VERSION "HNNBNNNYNNNNNNNNNNNNNNNNNNNNNNNNNNNNNNNNNN/4/%%%/4/'%**4NNN///"

NS_ :

BS_:

BU_: BAP_Tester FASFrontradar ICAS1_X_Gateway MFK MFK120 MIK MRR2023 NR_1 NR_2

BO_ 588 Heckradar_01: 16 ICAS1_X_Gateway
 SG_ SWA_LED_Hell_BFS : 12|7@1+ (1,0) [0|100] "Unit_PerCent"  Vector__XXX
 SG_ SWA_LED_Hell_FS : 19|7@1+ (1,0) [0|100] "Unit_PerCent"  Vector__XXX
 SG_ SWA_LED_Ausgabemodus_BFS : 26|3@1+ (1.0,0.0) [0.0|7] ""  Vector__XXX
 SG_ SWA_LED_Ausgabemodus_FS : 29|3@1+ (1.0,0.0) [0.0|7] ""  Vector__XXX
 SG_ SWA_Status : 32|2@1+ (1.0,0.0) [0.0|3] ""  MFK
 SG_ ASW_Ton_Richtung_VL : 34|1@1+ (1.0,0.0) [0.0|1] ""  Vector__XXX
 SG_ ASW_Ton_Richtung_VR : 35|1@1+ (1.0,0.0) [0.0|1] ""  Vector__XXX
 SG_ ASW_Ton_Richtung_HL : 36|1@1+ (1.0,0.0) [0.0|1] ""  Vector__XXX
 SG_ ASW_Ton_Richtung_HR : 37|1@1+ (1.0,0.0) [0.0|1] ""  Vector__XXX
 SG_ SWA_Status_System : 38|2@1+ (1.0,0.0) [0.0|3] ""  MFK120
 SG_ SWA_Brightness_Mode_FPM : 40|4@1+ (1.0,0.0) [0.0|15] ""  Vector__XXX
 SG_ SWA_Status_KuFu : 44|2@1+ (1.0,0.0) [0.0|3] ""  MFK120
 SG_ SWA_Infostufe_Assist_li : 46|1@1+ (1.0,0.0) [0.0|1] ""  Vector__XXX
 SG_ SWA_Infostufe_Assist_re : 47|1@1+ (1.0,0.0) [0.0|1] ""  Vector__XXX
 SG_ SWA_Warnstufe_Assist_li : 48|1@1+ (1.0,0.0) [0.0|1] ""  Vector__XXX
 SG_ SWA_Warnstufe_Assist_re : 49|1@1+ (1.0,0.0) [0.0|1] ""  Vector__XXX
 SG_ SWA_Modus_System : 50|3@1+ (1.0,0.0) [0.0|7] ""  MRR2023
 SG_ SWA_Kombiausgabe : 53|3@1+ (1.0,0.0) [0.0|7] ""  Vector__XXX
 SG_ ASW_Kombiausgabe : 56|3@1+ (1.0,0.0) [0.0|7] ""  Vector__XXX
 SG_ ASW_Ausgabemodus_HBFS : 64|3@1+ (1.0,0.0) [0.0|7] ""  Vector__XXX
 SG_ ASW_Ausgabemodus_HFS : 67|3@1+ (1.0,0.0) [0.0|7] ""  Vector__XXX
 SG_ ASW_Akustik_Einstellung : 70|1@1+ (1.0,0.0) [0.0|1] ""  Vector__XXX
 SG_ SWA_Anzeigen : 76|4@1+ (1.0,0.0) [0.0|15] ""  Vector__XXX
 SG_ SWA_Blindheit_erkannt : 80|1@1+ (1.0,0.0) [0.0|1] ""  FASFrontradar,MFK
 SG_ SWA_rel_Nichtverf : 81|1@1+ (1.0,0.0) [0.0|1] ""  FASFrontradar,MFK
 SG_ SWA_rel_Fehler : 82|1@1+ (1.0,0.0) [0.0|1] ""  FASFrontradar,MFK
 SG_ SWA_Sta_aktiv : 83|1@1+ (1.0,0.0) [0.0|1] ""  MFK
 SG_ SWA_Sta_passiv : 84|1@1+ (1.0,0.0) [0.0|1] ""  MFK
 SG_ SWA_FT_RueckLED : 85|1@1+ (1.0,0.0) [0.0|1] ""  Vector__XXX
 SG_ ASW_Status : 86|2@1+ (1.0,0.0) [0.0|3] ""  Vector__XXX
 SG_ SWA_Standziele_li : 88|1@1+ (1.0,0.0) [0.0|1] ""  Vector__XXX
 SG_ ASW_Ausgabemodus_BFS : 89|3@1+ (1.0,0.0) [0.0|7] ""  Vector__XXX
 SG_ ASW_Warnung_FS : 92|1@1+ (1.0,0.0) [0.0|1] ""  Vector__XXX
 SG_ ASW_Warnung_BFS : 93|1@1+ (1.0,0.0) [0.0|1] ""  Vector__XXX
 SG_ ASW_Kombitexte : 94|3@1+ (1.0,0.0) [0.0|7] ""  Vector__XXX
 SG_ ASW_Modus : 98|3@1+ (1.0,0.0) [0.0|7] ""  Vector__XXX
 SG_ SWA_Modus : 101|3@1+ (1.0,0.0) [0.0|7] ""  MFK
 SG_ SWA_Standziele_re : 104|1@1+ (1.0,0.0) [0.0|1] ""  Vector__XXX
 SG_ ASW_Ausgabemodus_FS : 105|3@1+ (1.0,0.0) [0.0|7] ""  Vector__XXX
 SG_ HRE_Anzeigetexte : 108|4@1+ (1.0,0.0) [0.0|15] ""  Vector__XXX
 SG_ SWA_Gischtzaehler : 112|7@1+ (1,0) [0|100] "Unit_PerCent"  MFK
 SG_ SWA_Blindheitsverdacht : 119|1@1+ (1.0,0.0) [0.0|1] ""  FASFrontradar,MFK
 SG_ Heckradar_Kombitexte : 120|5@1+ (1.0,0.0) [0.0|31] ""  Vector__XXX
 SG_ RCTA_Kombitexte : 125|3@1+ (1.0,0.0) [0.0|7] ""  Vector__XXX

BO_ 589 Heckradar_02: 64 ICAS1_X_Gateway
 SG_ SWA_StrukturLinks_querAbstand : 12|9@1+ (0.03125,0) [0.00000|15.93750] "Unit_Meter"  MFK
 SG_ SWA_StrukturLinks_Typ : 21|3@1+ (1.0,0.0) [0.0|7] ""  MFK
 SG_ SWA_Umfeld_Zeitstempel : 24|16@1+ (0.1,0) [0.0|6553.5] "Unit_MilliSecon"  MFK
 SG_ SWA_Umfeld_Zeitstempel_Status : 54|3@1+ (1.0,0.0) [0.0|7] ""  MFK
 SG_ SWA_Kolonne_li : 57|1@1+ (1.0,0.0) [0.0|1] ""  MFK
 SG_ SWA_Kolonne_mi : 58|1@1+ (1.0,0.0) [0.0|1] ""  MFK
 SG_ SWA_Kolonne_re : 59|1@1+ (1.0,0.0) [0.0|1] ""  MFK
 SG_ SWA_Infostufe_SWA_li : 60|1@1+ (1.0,0.0) [0.0|1] ""  FASFrontradar,MFK,MFK120
 SG_ SWA_Infostufe_SWA_re : 61|1@1+ (1.0,0.0) [0.0|1] ""  FASFrontradar,MFK,MFK120
 SG_ SWA_Warnung_SWA_li : 62|1@1+ (1.0,0.0) [0.0|1] ""  FASFrontradar,MFK,MFK120
 SG_ SWA_Warnung_SWA_re : 63|1@1+ (1.0,0.0) [0.0|1] ""  FASFrontradar,MFK,MFK120
 SG_ SWA_Obj_Kurvenradius : 64|16@1+ (1,-32767) [-32767|32767] "Unit_Meter"  MFK
 SG_ SWA_StrukturRechts_querAbstand : 80|9@1+ (0.03125,0) [0.00000|15.93750] "Unit_Meter"  MFK
 SG_ SWA_StrukturRechts_Typ : 89|3@1+ (1.0,0.0) [0.0|7] ""  MFK
 SG_ SWA_Obj_01_Gemessen : 92|1@1+ (1.0,0.0) [0.0|1] ""  FASFrontradar,MFK
 SG_ SWA_Obj_01_ID : 93|5@1+ (1,0) [1|30] ""  FASFrontradar,MFK
 SG_ SWA_Obj_02_Gemessen : 98|1@1+ (1.0,0.0) [0.0|1] ""  FASFrontradar,MFK
 SG_ SWA_Obj_02_ID : 99|5@1+ (1,0) [1|30] ""  FASFrontradar,MFK
 SG_ SWA_Obj_03_Gemessen : 104|1@1+ (1.0,0.0) [0.0|1] ""  FASFrontradar,MFK
 SG_ SWA_Obj_03_ID : 105|5@1+ (1,0) [1|30] ""  FASFrontradar,MFK
 SG_ SWA_Obj_04_Gemessen : 110|1@1+ (1.0,0.0) [0.0|1] ""  FASFrontradar,MFK
 SG_ SWA_Obj_04_ID : 111|5@1+ (1,0) [1|30] ""  FASFrontradar,MFK,MRR2023
 SG_ SWA_Obj_05_Gemessen : 116|1@1+ (1.0,0.0) [0.0|1] ""  FASFrontradar,MFK
 SG_ SWA_Obj_05_ID : 117|5@1+ (1,0) [1|30] ""  FASFrontradar,MFK
 SG_ SWA_Obj_06_Gemessen : 122|1@1+ (1.0,0.0) [0.0|1] ""  FASFrontradar,MFK
 SG_ SWA_Obj_06_ID : 123|5@1+ (1,0) [1|30] ""  FASFrontradar,MFK
 SG_ SWA_Obj_01_GeschwRelX : 128|9@1+ (0.25,-37.5) [-37.50|90.00] "Unit_MeterPerSecon"  FASFrontradar,MFK
 SG_ SWA_Obj_01_Breite : 137|7@1+ (0.03125,0) [0.00000|3.93750] "Unit_Meter"  MFK
 SG_ SWA_Obj_01_GeschwRelY : 144|9@1+ (0.03125,-7.9375) [-7.93750|8.00000] "Unit_MeterPerSecon"  MFK
 SG_ SWA_Obj_01_Existenzwahrsch : 153|7@1+ (1,0) [0|100] "Unit_PerCent"  MFK
 SG_ SWA_Obj_01_Objektklasse : 160|4@1+ (1.0,0.0) [0.0|15] ""  MFK
 SG_ SWA_Obj_01_ReferenzPkt : 164|4@1+ (1.0,0.0) [0.0|15] ""  MFK
 SG_ SWA_Obj_01_PositionX : 168|9@1+ (0.25,-102.5) [-102.50|25.00] "Unit_Meter"  FASFrontradar,MFK
 SG_ SWA_Obj_01_Laenge : 177|7@1+ (0.25,0) [0.00|31.50] "Unit_Meter"  MFK
 SG_ SWA_Obj_01_PositionY : 184|8@1+ (0.125,-16) [-16.000|15.750] "Unit_Meter"  FASFrontradar,MFK
 SG_ SWA_Obj_02_GeschwRelX : 192|9@1+ (0.25,-37.5) [-37.50|90.00] "Unit_MeterPerSecon"  FASFrontradar,MFK
 SG_ SWA_Obj_02_Breite : 201|7@1+ (0.03125,0) [0.00000|3.93750] "Unit_Meter"  MFK
 SG_ SWA_Obj_02_GeschwRelY : 208|9@1+ (0.03125,-7.9375) [-7.93750|8.00000] "Unit_MeterPerSecon"  MFK
 SG_ SWA_Obj_02_Existenzwahrsch : 217|7@1+ (1,0) [0|100] "Unit_PerCent"  MFK
 SG_ SWA_Obj_02_Objektklasse : 224|4@1+ (1.0,0.0) [0.0|15] ""  MFK
 SG_ SWA_Obj_02_ReferenzPkt : 228|4@1+ (1.0,0.0) [0.0|15] ""  MFK
 SG_ SWA_Obj_02_PositionX : 232|9@1+ (0.25,-102.5) [-102.50|25.00] "Unit_Meter"  FASFrontradar,MFK
 SG_ SWA_Obj_02_Laenge : 241|7@1+ (0.25,0) [0.00|31.50] "Unit_Meter"  MFK
 SG_ SWA_Obj_02_PositionY : 248|8@1+ (0.125,-16) [-16.000|15.750] "Unit_Meter"  FASFrontradar,MFK
 SG_ SWA_Obj_03_GeschwRelX : 256|9@1+ (0.25,-37.5) [-37.50|90.00] "Unit_MeterPerSecon"  FASFrontradar,MFK
 SG_ SWA_Obj_03_Breite : 265|7@1+ (0.03125,0) [0.00000|3.93750] "Unit_Meter"  MFK
 SG_ SWA_Obj_03_GeschwRelY : 272|9@1+ (0.03125,-7.9375) [-7.93750|8.00000] "Unit_MeterPerSecon"  MFK
 SG_ SWA_Obj_03_Existenzwahrsch : 281|7@1+ (1,0) [0|100] "Unit_PerCent"  MFK
 SG_ SWA_Obj_03_Objektklasse : 288|4@1+ (1.0,0.0) [0.0|15] ""  MFK
 SG_ SWA_Obj_03_ReferenzPkt : 292|4@1+ (1.0,0.0) [0.0|15] ""  MFK
 SG_ SWA_Obj_03_PositionX : 296|9@1+ (0.25,-102.5) [-102.50|25.00] "Unit_Meter"  FASFrontradar,MFK
 SG_ SWA_Obj_03_Laenge : 305|7@1+ (0.25,0) [0.00|31.50] "Unit_Meter"  MFK
 SG_ SWA_Obj_03_PositionY : 312|8@1+ (0.125,-16) [-16.000|15.750] "Unit_Meter"  FASFrontradar,MFK
 SG_ SWA_Obj_04_GeschwRelX : 320|9@1+ (0.25,-37.5) [-37.50|90.00] "Unit_MeterPerSecon"  FASFrontradar,MFK
 SG_ SWA_Obj_04_Breite : 329|7@1+ (0.03125,0) [0.00000|3.93750] "Unit_Meter"  MFK
 SG_ SWA_Obj_04_GeschwRelY : 336|9@1+ (0.03125,-7.9375) [-7.93750|8.00000] "Unit_MeterPerSecon"  MFK
 SG_ SWA_Obj_04_Existenzwahrsch : 345|7@1+ (1,0) [0|100] "Unit_PerCent"  MFK
 SG_ SWA_Obj_04_Objektklasse : 352|4@1+ (1.0,0.0) [0.0|15] ""  MFK
 SG_ SWA_Obj_04_ReferenzPkt : 356|4@1+ (1.0,0.0) [0.0|15] ""  MFK
 SG_ SWA_Obj_04_PositionX : 360|9@1+ (0.25,-102.5) [-102.50|25.00] "Unit_Meter"  FASFrontradar,MFK
 SG_ SWA_Obj_04_Laenge : 369|7@1+ (0.25,0) [0.00|31.50] "Unit_Meter"  MFK
 SG_ SWA_Obj_04_PositionY : 376|8@1+ (0.125,-16) [-16.000|15.750] "Unit_Meter"  FASFrontradar,MFK
 SG_ SWA_Obj_05_GeschwRelX : 384|9@1+ (0.25,-37.5) [-37.50|90.00] "Unit_MeterPerSecon"  FASFrontradar,MFK
 SG_ SWA_Obj_05_Breite : 393|7@1+ (0.03125,0) [0.00000|3.93750] "Unit_Meter"  MFK
 SG_ SWA_Obj_05_GeschwRelY : 400|9@1+ (0.03125,-7.9375) [-7.93750|8.00000] "Unit_MeterPerSecon"  MFK
 SG_ SWA_Obj_05_Existenzwahrsch : 409|7@1+ (1,0) [0|100] "Unit_PerCent"  MFK
 SG_ SWA_Obj_05_Objektklasse : 416|4@1+ (1.0,0.0) [0.0|15] ""  MFK
 SG_ SWA_Obj_05_ReferenzPkt : 420|4@1+ (1.0,0.0) [0.0|15] ""  MFK
 SG_ SWA_Obj_05_PositionX : 424|9@1+ (0.25,-102.5) [-102.50|25.00] "Unit_Meter"  FASFrontradar,MFK
 SG_ SWA_Obj_05_Laenge : 433|7@1+ (0.25,0) [0.00|31.50] "Unit_Meter"  MFK
 SG_ SWA_Obj_05_PositionY : 440|8@1+ (0.125,-16) [-16.000|15.750] "Unit_Meter"  FASFrontradar,MFK
 SG_ SWA_Obj_06_GeschwRelX : 448|9@1+ (0.25,-37.5) [-37.50|90.00] "Unit_MeterPerSecon"  FASFrontradar,MFK
 SG_ SWA_Obj_06_Breite : 457|7@1+ (0.03125,0) [0.00000|3.93750] "Unit_Meter"  MFK
 SG_ SWA_Obj_06_GeschwRelY : 464|9@1+ (0.03125,-7.9375) [-7.93750|8.00000] "Unit_MeterPerSecon"  MFK
 SG_ SWA_Obj_06_Existenzwahrsch : 473|7@1+ (1,0) [0|100] "Unit_PerCent"  MFK
 SG_ SWA_Obj_06_Objektklasse : 480|4@1+ (1.0,0.0) [0.0|15] ""  MFK
 SG_ SWA_Obj_06_ReferenzPkt : 484|4@1+ (1.0,0.0) [0.0|15] ""  MFK
 SG_ SWA_Obj_06_PositionX : 488|9@1+ (0.25,-102.5) [-102.50|25.00] "Unit_Meter"  FASFrontradar,MFK
 SG_ SWA_Obj_06_Laenge : 497|7@1+ (0.25,0) [0.00|31.50] "Unit_Meter"  MFK
 SG_ SWA_Obj_06_PositionY : 504|8@1+ (0.125,-16) [-16.000|15.750] "Unit_Meter"  FASFrontradar,MFK

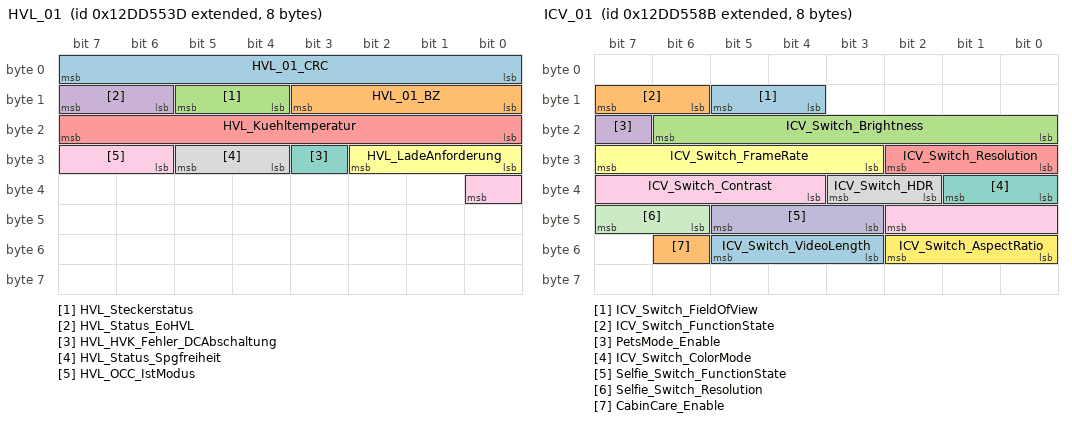
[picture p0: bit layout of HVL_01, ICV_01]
BO_ 2463978813 HVL_01: 8 ICAS1_X_Gateway
 SG_ HVL_01_CRC : 0|8@1+ (1,0) [0|255] ""  Vector__XXX
 SG_ HVL_01_BZ : 8|4@1+ (1,0) [0|15] ""  Vector__XXX
 SG_ HVL_Steckerstatus : 12|2@1+ (1.0,0.0) [0.0|3] ""  MFK,MFK120
 SG_ HVL_Status_EoHVL : 14|2@1+ (1.0,0.0) [0.0|3] ""  Vector__XXX
 SG_ HVL_Kuehltemperatur : 16|8@1+ (1,-40) [-40|213] "Unit_DegreCelsi"  Vector__XXX
 SG_ HVL_LadeAnforderung : 24|3@1+ (1.0,0.0) [0.0|7] ""  Vector__XXX
 SG_ HVL_HVK_Fehler_DCAbschaltung : 27|1@1+ (1.0,0.0) [0.0|1] ""  Vector__XXX
 SG_ HVL_Status_Spgfreiheit : 28|2@1+ (1.0,0.0) [0.0|3] ""  Vector__XXX
 SG_ HVL_OCC_IstModus : 30|3@1+ (1.0,0.0) [0.0|7] ""  Vector__XXX

BO_ 2463978891 ICV_01: 8 ICAS1_X_Gateway
 SG_ ICV_Switch_FieldOfView : 12|2@1+ (1.0,0.0) [0.0|3] ""  MIK
 SG_ ICV_Switch_FunctionState : 14|2@1+ (1.0,0.0) [0.0|3] ""  MIK
 SG_ ICV_Switch_Brightness : 16|7@1+ (1,0) [0|100] "Unit_PerCent"  MIK
 SG_ PetsMode_Enable : 23|1@1+ (1.0,0.0) [0.0|1] ""  MIK
 SG_ ICV_Switch_Resolution : 24|3@1+ (1.0,0.0) [0.0|7] ""  MIK
 SG_ ICV_Switch_FrameRate : 27|5@1+ (1,0) [15|30] "Unit_SeconInver"  MIK
 SG_ ICV_Switch_ColorMode : 32|2@1+ (1.0,0.0) [0.0|3] ""  MIK
 SG_ ICV_Switch_HDR : 34|2@1+ (1.0,0.0) [0.0|3] ""  MIK
 SG_ ICV_Switch_Contrast : 36|7@1+ (1,0) [0|100] "Unit_PerCent"  MIK
 SG_ Selfie_Switch_FunctionState : 43|3@1+ (1.0,0.0) [0.0|7] ""  MIK
 SG_ Selfie_Switch_Resolution : 46|2@1+ (1.0,0.0) [0.0|3] ""  MIK
 SG_ ICV_Switch_AspectRatio : 48|3@1+ (1.0,0.0) [0.0|7] ""  MIK
 SG_ ICV_Switch_VideoLength : 51|3@1+ (1.0,0.0) [0.0|7] ""  MIK
 SG_ CabinCare_Enable : 54|1@1+ (1.0,0.0) [0.0|1] ""  MIK

BO_ 1524 Innenlicht_11: 8 ICAS1_X_Gateway
 SG_ IL_Dimmung_V_Tuerkontur : 0|8@1+ (1,0) [0|100] "Unit_PerCent"  Vector__XXX
 SG_ IL_Dimmung_H_Tuerkontur : 8|8@1+ (1,0) [0|100] "Unit_PerCent"  Vector__XXX
 SG_ IL_Dimmung_Tuerinnengriff : 16|8@1+ (1,0) [0|100] "Unit_PerCent"  Vector__XXX
 SG_ IL_Dimmung_Umfeldbel : 24|8@1+ (1,0) [0|100] "Unit_PerCent"  Vector__XXX
 SG_ IL_Bel_FS_Ausstieg : 32|1@1+ (1.0,0.0) [0.0|1] ""  Vector__XXX
 SG_ IL_Bel_BFS_Ausstieg : 33|1@1+ (1.0,0.0) [0.0|1] ""  Vector__XXX
 SG_ IL_Bel_HFS_Ausstieg : 34|1@1+ (1.0,0.0) [0.0|1] ""  Vector__XXX
 SG_ IL_Bel_HBFS_Ausstieg : 35|1@1+ (1.0,0.0) [0.0|1] ""  Vector__XXX
 SG_ BCM1_Innenlicht_gedimmt_V : 36|1@1+ (1.0,0.0) [0.0|1] ""  Vector__XXX
 SG_ BCM1_Innenlicht_gedimmt_H : 37|1@1+ (1.0,0.0) [0.0|1] ""  Vector__XXX
 SG_ IL_Innenlicht_aktiv : 38|1@1+ (1.0,0.0) [0.0|1] ""  MFK,MIK
 SG_ IL_Klemme_30G_aktiv : 39|1@1+ (1.0,0.0) [0.0|1] ""  Vector__XXX
 SG_ BCM1_DI_Rampe_Innenlicht : 40|1@1+ (1.0,0.0) [0.0|1] ""  Vector__XXX
 SG_ BCM1_DI_Rampe_Leselicht : 41|1@1+ (1.0,0.0) [0.0|1] ""  Vector__XXX
 SG_ BCM1_Innenlicht_H : 42|1@1+ (1.0,0.0) [0.0|1] ""  Vector__XXX
 SG_ BCM1_Innenlicht_V : 43|1@1+ (1.0,0.0) [0.0|1] ""  Vector__XXX
 SG_ BCM1_Leselicht_Anf_hl : 44|1@1+ (1.0,0.0) [0.0|1] ""  Vector__XXX
 SG_ BCM1_Leselicht_Anf_hr : 45|1@1+ (1.0,0.0) [0.0|1] ""  Vector__XXX
 SG_ BCM1_Leselicht_Anf_vl : 46|1@1+ (1.0,0.0) [0.0|1] ""  Vector__XXX
 SG_ BCM1_Leselicht_Anf_vr : 47|1@1+ (1.0,0.0) [0.0|1] ""  Vector__XXX
 SG_ BCM1_Leuchten_Aus : 48|1@1+ (1.0,0.0) [0.0|1] ""  Vector__XXX
 SG_ AMB_Charisma_FahrPr : 49|4@1+ (1.0,0.0) [0.0|15] ""  Vector__XXX
 SG_ AMB_Charisma_Status : 53|2@1+ (1.0,0.0) [0.0|3] ""  Vector__XXX
 SG_ IL_Tuerkontakt_Taster : 55|1@1+ (1.0,0.0) [0.0|1] ""  Vector__XXX
 SG_ IL_Dimmung_Lautspr : 56|8@1+ (1,0) [0|100] "Unit_PerCent"  Vector__XXX

BO_ 1879 ISO_ACC_Req: 8 ICAS1_X_Gateway
 SG_ ISO_ACC_Req_Data : 0|64@1+ (1.0,0.0) [0.0|18446744073709551615] ""  FASFrontradar,MRR2023

BO_ 1985 ISO_ACC_Resp: 8 FASFrontradar
 SG_ ISO_ACC_Resp_Data : 0|64@1+ (1.0,0.0) [0.0|18446744073709551615] ""  ICAS1_X_Gateway

BO_ 1792 ISO_Funktionaler_Req_All: 8 ICAS1_X_Gateway
 SG_ ISO_ALL_01_Req_Data : 0|64@1+ (1.0,0.0) [0.0|18446744073709551615] ""  FASFrontradar,MFK,MRR2023,NR_1,NR_2

BO_ 1871 ISO_Kamera_Req: 8 ICAS1_X_Gateway
 SG_ ISO_Kamera_Req_Data : 0|64@1+ (1.0,0.0) [0.0|18446744073709551615] ""  MFK

BO_ 1977 ISO_Kamera_Resp: 8 MFK
 SG_ ISO_Kamera_Resp_Data : 0|64@1+ (1.0,0.0) [0.0|18446744073709551615] ""  ICAS1_X_Gateway

BO_ 2621440087 ISOx_ACC_Req_FD: 64 ICAS1_X_Gateway
 SG_ ISOx_ACC_Req_FD_Data : 0|512@1+ (1.0,0.0) [0.0|13407807929942597099574024998205846127479365820592393377723561443721764030073546976801874298166903427690031858186486050853753882811946569946433649006084095] ""  FASFrontradar,MRR2023

BO_ 2621571159 ISOx_ACC_Resp_FD: 64 FASFrontradar
 SG_ ISOx_ACC_Resp_FD_Data : 0|512@1+ (1.0,0.0) [0.0|13407807929942597099574024998205846127479365820592393377723561443721764030073546976801874298166903427690031858186486050853753882811946569946433649006084095] ""  ICAS1_X_Gateway

BO_ 2621505536 ISOx_Funkt_Req_All_FD: 64 ICAS1_X_Gateway
 SG_ ISOx_Funkt_Req_All_FD_Data : 0|512@1+ (1.0,0.0) [0.0|13407807929942597099574024998205846127479365820592393377723561443721764030073546976801874298166903427690031858186486050853753882811946569946433649006084095] ""  FASFrontradar,MFK,MRR2023,NR_1,NR_2

BO_ 2621440079 ISOx_Kamera_Req_FD: 64 ICAS1_X_Gateway
 SG_ ISOx_Kamera_Req_FD_Data : 0|512@1+ (1.0,0.0) [0.0|13407807929942597099574024998205846127479365820592393377723561443721764030073546976801874298166903427690031858186486050853753882811946569946433649006084095] ""  MFK

BO_ 2621571151 ISOx_Kamera_Resp_FD: 64 MFK
 SG_ ISOx_Kamera_Resp_FD_Data : 0|512@1+ (1.0,0.0) [0.0|13407807929942597099574024998205846127479365820592393377723561443721764030073546976801874298166903427690031858186486050853753882811946569946433649006084095] ""  ICAS1_X_Gateway

BO_ 2549874875 ISOx_NR_01_Req: 8 ICAS1_X_Gateway
 SG_ ISOx_NR_01_Req_Data : 0|64@1+ (1.0,0.0) [0.0|18446744073709551615] ""  NR_1

BO_ 2621440187 ISOx_NR_01_Req_FD: 64 ICAS1_X_Gateway
 SG_ ISOx_NR_01_Req_FD_Data : 0|512@1+ (1.0,0.0) [0.0|13407807929942597099574024998205846127479365820592393377723561443721764030073546976801874298166903427690031858186486050853753882811946569946433649006084095] ""  NR_1

BO_ 2550005947 ISOx_NR_01_Resp: 8 NR_1
 SG_ ISOx_NR_01_Resp_Data : 0|64@1+ (1.0,0.0) [0.0|18446744073709551615] ""  ICAS1_X_Gateway

BO_ 2621571259 ISOx_NR_01_Resp_FD: 64 NR_1
 SG_ ISOx_NR_01_Resp_FD_Data : 0|512@1+ (1.0,0.0) [0.0|13407807929942597099574024998205846127479365820592393377723561443721764030073546976801874298166903427690031858186486050853753882811946569946433649006084095] ""  ICAS1_X_Gateway

BO_ 2549874876 ISOx_NR_02_Req: 8 ICAS1_X_Gateway
 SG_ ISOx_NR_02_Req_Data : 0|64@1+ (1.0,0.0) [0.0|18446744073709551615] ""  NR_2

BO_ 2621440188 ISOx_NR_02_Req_FD: 64 ICAS1_X_Gateway
 SG_ ISOx_NR_02_Req_FD_Data : 0|512@1+ (1.0,0.0) [0.0|13407807929942597099574024998205846127479365820592393377723561443721764030073546976801874298166903427690031858186486050853753882811946569946433649006084095] ""  NR_2

BO_ 2550005948 ISOx_NR_02_Resp: 8 NR_2
 SG_ ISOx_NR_02_Resp_Data : 0|64@1+ (1.0,0.0) [0.0|18446744073709551615] ""  ICAS1_X_Gateway

BO_ 2621571260 ISOx_NR_02_Resp_FD: 64 NR_2
 SG_ ISOx_NR_02_Resp_FD_Data : 0|512@1+ (1.0,0.0) [0.0|13407807929942597099574024998205846127479365820592393377723561443721764030073546976801874298166903427690031858186486050853753882811946569946433649006084095] ""  ICAS1_X_Gateway

BO_ 2527679667 Kamera_AHC_01: 16 MFK
 SG_ Kamera_AHC_L_Funktionsstatus : 12|4@1+ (1.0,0.0) [0.0|15] ""  Vector__XXX
 SG_ Kamera_AHC_L_Gierwinkel : 16|13@1+ (0.01,-40.95) [-40.95|40.95] "Unit_DegreOfArc"  Vector__XXX
 SG_ Kamera_AHC_L_Nickwinkel : 29|13@1+ (0.01,-40.95) [-40.95|40.95] "Unit_DegreOfArc"  Vector__XXX
 SG_ Kamera_AHC_L_ROI_ID : 42|4@1+ (1,0) [0|14] "Unit_None"  Vector__XXX
 SG_ Kamera_AHC_L_Qualitaet : 46|5@1+ (4,0) [0|100] "Unit_PerCent"  Vector__XXX
 SG_ Kamera_AHC_R_Funktionsstatus : 76|4@1+ (1.0,0.0) [0.0|15] ""  Vector__XXX
 SG_ Kamera_AHC_R_Gierwinkel : 80|13@1+ (0.01,-40.95) [-40.95|40.95] "Unit_DegreOfArc"  Vector__XXX
 SG_ Kamera_AHC_R_Nickwinkel : 93|13@1+ (0.01,-40.95) [-40.95|40.95] "Unit_DegreOfArc"  Vector__XXX
 SG_ Kamera_AHC_R_ROI_ID : 106|4@1+ (1,0) [0|14] "Unit_None"  Vector__XXX
 SG_ Kamera_AHC_R_Qualitaet : 110|5@1+ (4,0) [0|100] "Unit_PerCent"  Vector__XXX

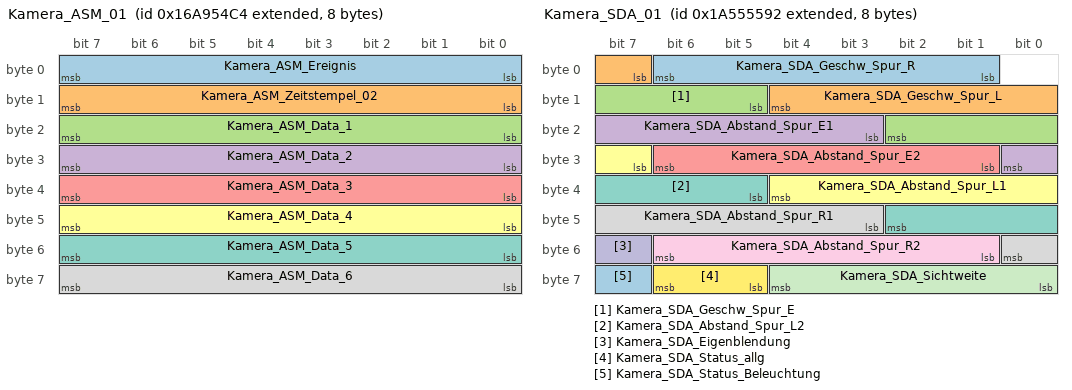
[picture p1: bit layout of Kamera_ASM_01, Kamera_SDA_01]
BO_ 2527679684 Kamera_ASM_01: 8 MFK
 SG_ Kamera_ASM_Ereignis : 0|8@1+ (1,0) [1|254] ""  ICAS1_X_Gateway
 SG_ Kamera_ASM_Zeitstempel_02 : 8|8@1+ (0.04,0) [0.00|10.16] "Unit_Secon"  ICAS1_X_Gateway
 SG_ Kamera_ASM_Data_1 : 16|8@1+ (1,0) [0|255] ""  ICAS1_X_Gateway
 SG_ Kamera_ASM_Data_2 : 24|8@1+ (1,0) [0|255] ""  ICAS1_X_Gateway
 SG_ Kamera_ASM_Data_3 : 32|8@1+ (1,0) [0|255] ""  ICAS1_X_Gateway
 SG_ Kamera_ASM_Data_4 : 40|8@1+ (1,0) [0|255] ""  ICAS1_X_Gateway
 SG_ Kamera_ASM_Data_5 : 48|8@1+ (1,0) [0|255] ""  ICAS1_X_Gateway
 SG_ Kamera_ASM_Data_6 : 56|8@1+ (1,0) [0|255] ""  ICAS1_X_Gateway

BO_ 2589283730 Kamera_SDA_01: 8 MFK
 SG_ Kamera_SDA_Geschw_Spur_R : 1|6@1+ (7.7581,-240) [-240.0000|241.0022] "Unit_KiloMeterPerHour"  ICAS1_X_Gateway
 SG_ Kamera_SDA_Geschw_Spur_L : 7|6@1+ (7.7581,-240) [-240.0000|241.0022] "Unit_KiloMeterPerHour"  ICAS1_X_Gateway
 SG_ Kamera_SDA_Geschw_Spur_E : 13|6@1+ (7.7581,-240) [-240.0000|241.0022] "Unit_KiloMeterPerHour"  ICAS1_X_Gateway
 SG_ Kamera_SDA_Abstand_Spur_E1 : 19|6@1+ (4.0323,0) [0.0000|250.0026] "Unit_Meter"  ICAS1_X_Gateway
 SG_ Kamera_SDA_Abstand_Spur_E2 : 25|6@1+ (4.0323,0) [0.0000|250.0026] "Unit_Meter"  ICAS1_X_Gateway
 SG_ Kamera_SDA_Abstand_Spur_L1 : 31|6@1+ (4.0323,0) [0.0000|250.0026] "Unit_Meter"  ICAS1_X_Gateway
 SG_ Kamera_SDA_Abstand_Spur_L2 : 37|6@1+ (4.0323,0) [0.0000|250.0026] "Unit_Meter"  ICAS1_X_Gateway
 SG_ Kamera_SDA_Abstand_Spur_R1 : 43|6@1+ (4.0323,0) [0.0000|250.0026] "Unit_Meter"  ICAS1_X_Gateway
 SG_ Kamera_SDA_Abstand_Spur_R2 : 49|6@1+ (4.0323,0) [0.0000|250.0026] "Unit_Meter"  ICAS1_X_Gateway
 SG_ Kamera_SDA_Eigenblendung : 55|1@1+ (1.0,0.0) [0.0|1] ""  ICAS1_X_Gateway
 SG_ Kamera_SDA_Sichtweite : 56|5@1+ (10,-10) [10|250] "Unit_Meter"  ICAS1_X_Gateway
 SG_ Kamera_SDA_Status_allg : 61|2@1+ (1.0,0.0) [0.0|3] ""  ICAS1_X_Gateway
 SG_ Kamera_SDA_Status_Beleuchtung : 63|1@1+ (1.0,0.0) [0.0|1] ""  ICAS1_X_Gateway

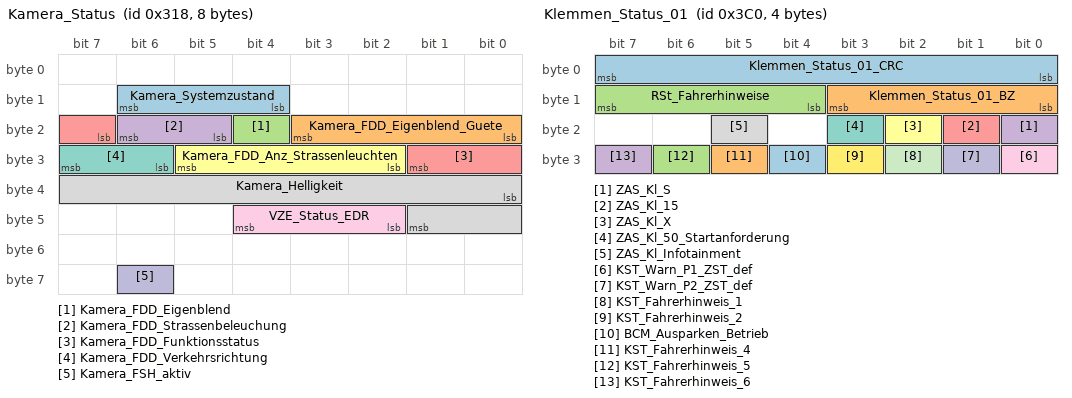
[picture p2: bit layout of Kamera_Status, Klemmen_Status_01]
BO_ 792 Kamera_Status: 8 MFK
 SG_ Kamera_Systemzustand : 12|3@1+ (1.0,0.0) [0.0|7] ""  FASFrontradar,ICAS1_X_Gateway,MRR2023
 SG_ Kamera_FDD_Eigenblend_Guete : 16|4@1+ (10,0) [0|100] "Unit_PerCent"  ICAS1_X_Gateway
 SG_ Kamera_FDD_Eigenblend : 20|1@1+ (1.0,0.0) [0.0|1] ""  ICAS1_X_Gateway
 SG_ Kamera_FDD_Strassenbeleuchung : 21|2@1+ (1.0,0.0) [0.0|3] ""  ICAS1_X_Gateway
 SG_ Kamera_FDD_Funktionsstatus : 23|3@1+ (1.0,0.0) [0.0|7] ""  ICAS1_X_Gateway
 SG_ Kamera_FDD_Anz_Strassenleuchten : 26|4@1+ (1,0) [0|14] ""  ICAS1_X_Gateway
 SG_ Kamera_FDD_Verkehrsrichtung : 30|2@1+ (1.0,0.0) [0.0|3] ""  ICAS1_X_Gateway
 SG_ Kamera_Helligkeit : 32|10@1+ (10,0) [0|10000] "Unit_Lux"  ICAS1_X_Gateway
 SG_ VZE_Status_EDR : 42|3@1+ (1.0,0.0) [0.0|7] ""  ICAS1_X_Gateway
 SG_ Kamera_FSH_aktiv : 62|1@1+ (1.0,0.0) [0.0|1] ""  ICAS1_X_Gateway

BO_ 960 Klemmen_Status_01: 4 ICAS1_X_Gateway
 SG_ Klemmen_Status_01_CRC : 0|8@1+ (1,0) [0|255] ""  FASFrontradar,MFK,MFK120,MRR2023
 SG_ Klemmen_Status_01_BZ : 8|4@1+ (1,0) [0|15] ""  FASFrontradar,MFK,MFK120,MRR2023
 SG_ RSt_Fahrerhinweise : 12|4@1+ (1.0,0.0) [0.0|15] ""  Vector__XXX
 SG_ ZAS_Kl_S : 16|1@1+ (1.0,0.0) [0.0|1] ""  MFK,MFK120
 SG_ ZAS_Kl_15 : 17|1@1+ (1.0,0.0) [0.0|1] ""  FASFrontradar,MFK,MFK120,MIK,MRR2023
 SG_ ZAS_Kl_X : 18|1@1+ (1.0,0.0) [0.0|1] ""  Vector__XXX
 SG_ ZAS_Kl_50_Startanforderung : 19|1@1+ (1.0,0.0) [0.0|1] ""  MFK,MFK120
 SG_ ZAS_Kl_Infotainment : 21|1@1+ (1.0,0.0) [0.0|1] ""  Vector__XXX
 SG_ KST_Warn_P1_ZST_def : 24|1@1+ (1.0,0.0) [0.0|1] ""  Vector__XXX
 SG_ KST_Warn_P2_ZST_def : 25|1@1+ (1.0,0.0) [0.0|1] ""  Vector__XXX
 SG_ KST_Fahrerhinweis_1 : 26|1@1+ (1.0,0.0) [0.0|1] ""  Vector__XXX
 SG_ KST_Fahrerhinweis_2 : 27|1@1+ (1.0,0.0) [0.0|1] ""  Vector__XXX
 SG_ BCM_Ausparken_Betrieb : 28|1@1+ (1.0,0.0) [0.0|1] ""  Vector__XXX
 SG_ KST_Fahrerhinweis_4 : 29|1@1+ (1.0,0.0) [0.0|1] ""  Vector__XXX
 SG_ KST_Fahrerhinweis_5 : 30|1@1+ (1.0,0.0) [0.0|1] ""  Vector__XXX
 SG_ KST_Fahrerhinweis_6 : 31|1@1+ (1.0,0.0) [0.0|1] ""  Vector__XXX

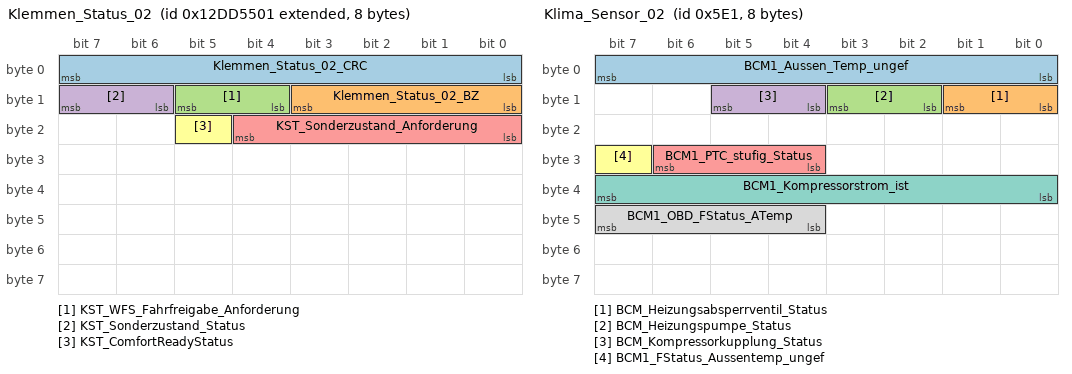
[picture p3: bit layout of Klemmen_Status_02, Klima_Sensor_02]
BO_ 2463978753 Klemmen_Status_02: 8 ICAS1_X_Gateway
 SG_ Klemmen_Status_02_CRC : 0|8@1+ (1,0) [0|255] ""  Vector__XXX
 SG_ Klemmen_Status_02_BZ : 8|4@1+ (1,0) [0|15] ""  Vector__XXX
 SG_ KST_WFS_Fahrfreigabe_Anforderung : 12|2@1+ (1.0,0.0) [0.0|3] ""  Vector__XXX
 SG_ KST_Sonderzustand_Status : 14|2@1+ (1.0,0.0) [0.0|3] ""  Vector__XXX
 SG_ KST_Sonderzustand_Anforderung : 16|5@1+ (1.0,0.0) [0.0|31] ""  Vector__XXX
 SG_ KST_ComfortReadyStatus : 21|1@1+ (1.0,0.0) [0.0|1] ""  Vector__XXX

BO_ 1640 Klima_12: 8 ICAS1_X_Gateway
 SG_ KL_LRH_Taster : 0|1@1+ (1.0,0.0) [0.0|1] ""  Vector__XXX
 SG_ KL_LRH_Stufe : 1|2@1+ (1.0,0.0) [0.0|3] ""  Vector__XXX
 SG_ HSH_Taster : 3|2@1+ (1.0,0.0) [0.0|3] ""  Vector__XXX
 SG_ FSH_Taster : 5|1@1+ (1.0,0.0) [0.0|1] ""  Vector__XXX
 SG_ KL_Zuheizer_Freigabe : 6|1@1+ (1.0,0.0) [0.0|1] ""  Vector__XXX
 SG_ KL_Beschlagsgefahr : 7|1@1+ (1.0,0.0) [0.0|1] ""  MFK,MFK120
 SG_ KL_SIH_Soll_li : 8|3@1+ (1,0) [0|6] ""  Vector__XXX
 SG_ KL_SIH_Soll_re : 11|3@1+ (1,0) [0|6] ""  Vector__XXX
 SG_ KRH_Soll_li : 14|2@1+ (1.0,0.0) [0.0|3] ""  Vector__XXX
 SG_ KL_SIL_Soll_li : 16|3@1+ (1,0) [0|6] ""  Vector__XXX
 SG_ KL_SIL_Soll_re : 19|3@1+ (1,0) [0|6] ""  Vector__XXX
 SG_ KRH_Soll_re : 22|2@1+ (1.0,0.0) [0.0|3] ""  Vector__XXX
 SG_ KL_Geblspng_Soll : 24|8@1+ (0.05,1.45) [1.50|14.00] "Unit_Volt"  Vector__XXX
 SG_ KL_Geblspng_Fond_Soll : 32|8@1+ (0.05,1.45) [1.50|14.00] "Unit_Volt"  Vector__XXX
 SG_ KL_I_Geblaese : 40|8@1+ (0.25,0) [0.00|63.50] "Unit_Amper"  Vector__XXX
 SG_ KL_Kompressorstrom_soll : 48|10@1+ (1,0) [0|1021] ""  Vector__XXX
 SG_ KL_Umluftklappe_Status : 58|4@1+ (1.0,0.0) [0.0|15] ""  Vector__XXX
 SG_ KL_PTC_Verbauinfo : 62|2@1+ (1.0,0.0) [0.0|3] ""  Vector__XXX

BO_ 1505 Klima_Sensor_02: 8 ICAS1_X_Gateway
 SG_ BCM1_Aussen_Temp_ungef : 0|8@1+ (0.5,-50) [-50.0|76.0] "Unit_DegreCelsi"  Vector__XXX
 SG_ BCM_Heizungsabsperrventil_Status : 8|2@1+ (1.0,0.0) [0.0|3] ""  Vector__XXX
 SG_ BCM_Heizungspumpe_Status : 10|2@1+ (1.0,0.0) [0.0|3] ""  Vector__XXX
 SG_ BCM_Kompressorkupplung_Status : 12|2@1+ (1.0,0.0) [0.0|3] ""  Vector__XXX
 SG_ BCM1_PTC_stufig_Status : 28|3@1+ (1.0,0.0) [0.0|7] ""  Vector__XXX
 SG_ BCM1_FStatus_Aussentemp_ungef : 31|1@1+ (1.0,0.0) [0.0|1] ""  MFK120
 SG_ BCM1_Kompressorstrom_ist : 32|8@1+ (4,0) [0|1000] "Unit_MilliAmper"  Vector__XXX
 SG_ BCM1_OBD_FStatus_ATemp : 44|4@1+ (1.0,0.0) [0.0|15] ""  Vector__XXX

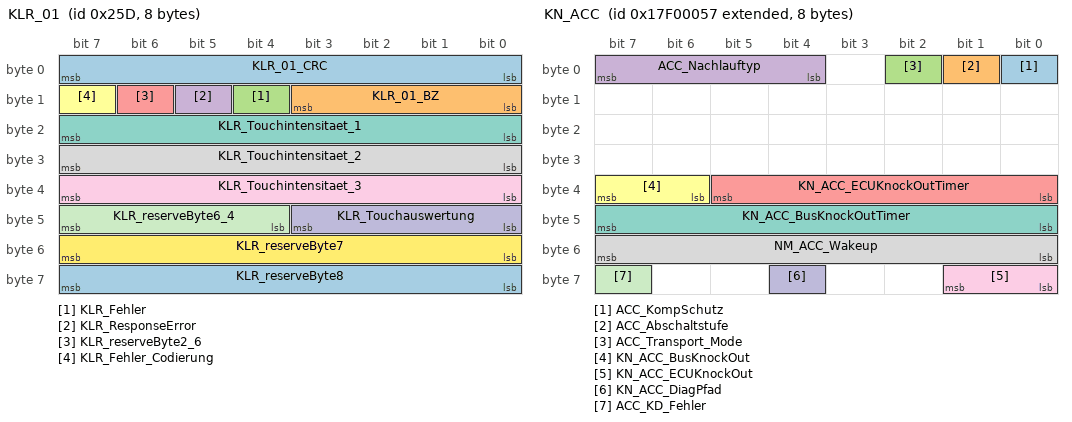
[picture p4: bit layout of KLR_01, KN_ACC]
BO_ 605 KLR_01: 8 ICAS1_X_Gateway
 SG_ KLR_01_CRC : 0|8@1+ (1,0) [0|255] ""  FASFrontradar,MRR2023
 SG_ KLR_01_BZ : 8|4@1+ (1,0) [0|15] ""  FASFrontradar,MRR2023
 SG_ KLR_Fehler : 12|1@1+ (1.0,0.0) [0.0|1] ""  MFK,MFK120
 SG_ KLR_ResponseError : 13|1@1+ (1.0,0.0) [0.0|1] ""  MFK
 SG_ KLR_reserveByte2_6 : 14|1@1+ (1.0,0.0) [0.0|1] ""  Vector__XXX
 SG_ KLR_Fehler_Codierung : 15|1@1+ (1.0,0.0) [0.0|1] ""  Vector__XXX
 SG_ KLR_Touchintensitaet_1 : 16|8@1+ (1,0) [0|250] "Unit_None"  FASFrontradar,MFK,MFK120,MRR2023
 SG_ KLR_Touchintensitaet_2 : 24|8@1+ (1,0) [0|250] "Unit_None"  MFK,MFK120
 SG_ KLR_Touchintensitaet_3 : 32|8@1+ (1,0) [0|250] "Unit_None"  MFK,MFK120
 SG_ KLR_Touchauswertung : 40|4@1+ (1.0,0.0) [0.0|15] ""  FASFrontradar,MFK,MFK120,MRR2023
 SG_ KLR_reserveByte6_4 : 44|4@1+ (1.0,0.0) [0.0|15] ""  Vector__XXX
 SG_ KLR_reserveByte7 : 48|8@1+ (1.0,0.0) [0.0|255] ""  Vector__XXX
 SG_ KLR_reserveByte8 : 56|8@1+ (1.0,0.0) [0.0|255] ""  Vector__XXX

BO_ 2549088343 KN_ACC: 8 FASFrontradar
 SG_ ACC_KompSchutz : 0|1@1+ (1.0,0.0) [0.0|1] ""  Vector__XXX
 SG_ ACC_Abschaltstufe : 1|1@1+ (1.0,0.0) [0.0|1] ""  Vector__XXX
 SG_ ACC_Transport_Mode : 2|1@1+ (1.0,0.0) [0.0|1] ""  Vector__XXX
 SG_ ACC_Nachlauftyp : 4|4@1+ (1.0,0.0) [0.0|15] ""  ICAS1_X_Gateway
 SG_ KN_ACC_ECUKnockOutTimer : 32|6@1+ (1,0) [0|62] ""  Vector__XXX
 SG_ KN_ACC_BusKnockOut : 38|2@1+ (1.0,0.0) [0.0|3] ""  Vector__XXX
 SG_ KN_ACC_BusKnockOutTimer : 40|8@1+ (1,0) [0|254] ""  Vector__XXX
 SG_ NM_ACC_Wakeup : 48|8@1+ (1.0,0.0) [0.0|255] ""  Vector__XXX
 SG_ KN_ACC_ECUKnockOut : 56|2@1+ (1.0,0.0) [0.0|3] ""  Vector__XXX
 SG_ KN_ACC_DiagPfad : 60|1@1+ (1.0,0.0) [0.0|1] ""  ICAS1_X_Gateway
 SG_ ACC_KD_Fehler : 63|1@1+ (1.0,0.0) [0.0|1] ""  ICAS1_X_Gateway

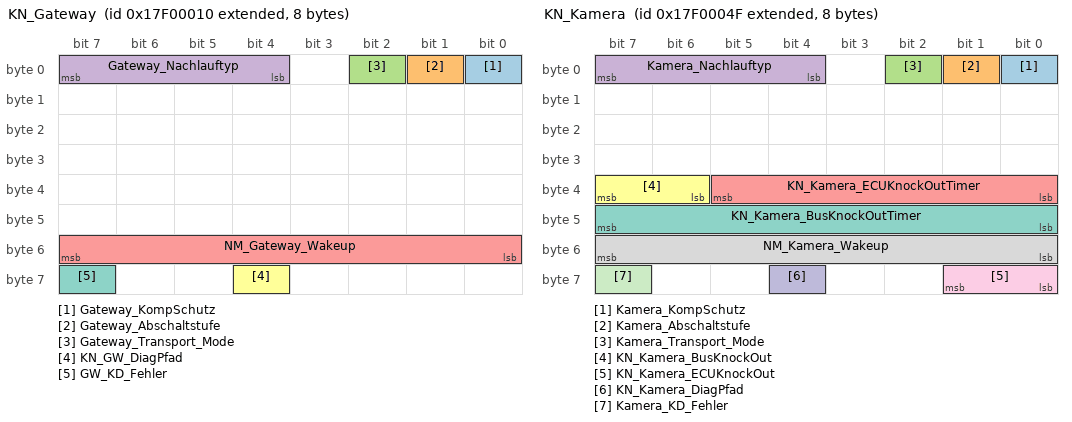
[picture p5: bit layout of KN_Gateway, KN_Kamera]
BO_ 2549088272 KN_Gateway: 8 ICAS1_X_Gateway
 SG_ Gateway_KompSchutz : 0|1@1+ (1.0,0.0) [0.0|1] ""  Vector__XXX
 SG_ Gateway_Abschaltstufe : 1|1@1+ (1.0,0.0) [0.0|1] ""  Vector__XXX
 SG_ Gateway_Transport_Mode : 2|1@1+ (1.0,0.0) [0.0|1] ""  Vector__XXX
 SG_ Gateway_Nachlauftyp : 4|4@1+ (1.0,0.0) [0.0|15] ""  Vector__XXX
 SG_ NM_Gateway_Wakeup : 48|8@1+ (1.0,0.0) [0.0|255] ""  Vector__XXX
 SG_ KN_GW_DiagPfad : 60|1@1+ (1.0,0.0) [0.0|1] ""  Vector__XXX
 SG_ GW_KD_Fehler : 63|1@1+ (1.0,0.0) [0.0|1] ""  Vector__XXX

BO_ 2549088335 KN_Kamera: 8 MFK
 SG_ Kamera_KompSchutz : 0|1@1+ (1.0,0.0) [0.0|1] ""  Vector__XXX
 SG_ Kamera_Abschaltstufe : 1|1@1+ (1.0,0.0) [0.0|1] ""  Vector__XXX
 SG_ Kamera_Transport_Mode : 2|1@1+ (1.0,0.0) [0.0|1] ""  Vector__XXX
 SG_ Kamera_Nachlauftyp : 4|4@1+ (1.0,0.0) [0.0|15] ""  ICAS1_X_Gateway
 SG_ KN_Kamera_ECUKnockOutTimer : 32|6@1+ (1,0) [0|62] ""  Vector__XXX
 SG_ KN_Kamera_BusKnockOut : 38|2@1+ (1.0,0.0) [0.0|3] ""  Vector__XXX
 SG_ KN_Kamera_BusKnockOutTimer : 40|8@1+ (1,0) [0|254] ""  Vector__XXX
 SG_ NM_Kamera_Wakeup : 48|8@1+ (1.0,0.0) [0.0|255] ""  Vector__XXX
 SG_ KN_Kamera_ECUKnockOut : 56|2@1+ (1.0,0.0) [0.0|3] ""  Vector__XXX
 SG_ KN_Kamera_DiagPfad : 60|1@1+ (1.0,0.0) [0.0|1] ""  ICAS1_X_Gateway
 SG_ Kamera_KD_Fehler : 63|1@1+ (1.0,0.0) [0.0|1] ""  ICAS1_X_Gateway

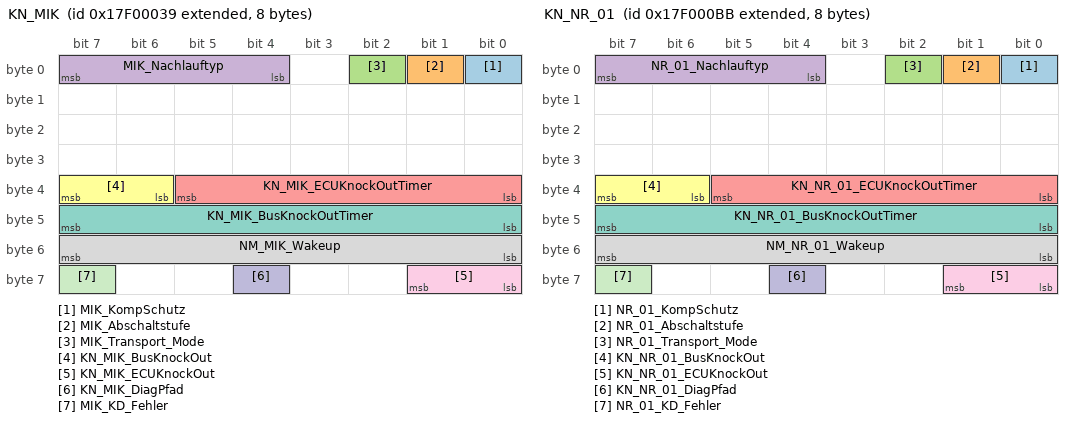
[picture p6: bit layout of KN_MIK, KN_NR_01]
BO_ 2549088313 KN_MIK: 8 MIK
 SG_ MIK_KompSchutz : 0|1@1+ (1.0,0.0) [0.0|1] ""  Vector__XXX
 SG_ MIK_Abschaltstufe : 1|1@1+ (1.0,0.0) [0.0|1] ""  Vector__XXX
 SG_ MIK_Transport_Mode : 2|1@1+ (1.0,0.0) [0.0|1] ""  Vector__XXX
 SG_ MIK_Nachlauftyp : 4|4@1+ (1.0,0.0) [0.0|15] ""  ICAS1_X_Gateway
 SG_ KN_MIK_ECUKnockOutTimer : 32|6@1+ (1,0) [0|62] "Unit_Minut"  Vector__XXX
 SG_ KN_MIK_BusKnockOut : 38|2@1+ (1.0,0.0) [0.0|3] ""  Vector__XXX
 SG_ KN_MIK_BusKnockOutTimer : 40|8@1+ (1,0) [0|254] "Unit_Minut"  Vector__XXX
 SG_ NM_MIK_Wakeup : 48|8@1+ (1.0,0.0) [0.0|255] ""  Vector__XXX
 SG_ KN_MIK_ECUKnockOut : 56|2@1+ (1.0,0.0) [0.0|3] ""  Vector__XXX
 SG_ KN_MIK_DiagPfad : 60|1@1+ (1.0,0.0) [0.0|1] ""  ICAS1_X_Gateway
 SG_ MIK_KD_Fehler : 63|1@1+ (1.0,0.0) [0.0|1] ""  ICAS1_X_Gateway

BO_ 2549088443 KN_NR_01: 8 NR_1
 SG_ NR_01_KompSchutz : 0|1@1+ (1.0,0.0) [0.0|1] ""  Vector__XXX
 SG_ NR_01_Abschaltstufe : 1|1@1+ (1.0,0.0) [0.0|1] ""  Vector__XXX
 SG_ NR_01_Transport_Mode : 2|1@1+ (1.0,0.0) [0.0|1] ""  Vector__XXX
 SG_ NR_01_Nachlauftyp : 4|4@1+ (1.0,0.0) [0.0|15] ""  ICAS1_X_Gateway
 SG_ KN_NR_01_ECUKnockOutTimer : 32|6@1+ (1,0) [0|62] ""  Vector__XXX
 SG_ KN_NR_01_BusKnockOut : 38|2@1+ (1.0,0.0) [0.0|3] ""  Vector__XXX
 SG_ KN_NR_01_BusKnockOutTimer : 40|8@1+ (1,0) [0|254] ""  Vector__XXX
 SG_ NM_NR_01_Wakeup : 48|8@1+ (1.0,0.0) [0.0|255] ""  Vector__XXX
 SG_ KN_NR_01_ECUKnockOut : 56|2@1+ (1.0,0.0) [0.0|3] ""  Vector__XXX
 SG_ KN_NR_01_DiagPfad : 60|1@1+ (1.0,0.0) [0.0|1] ""  Vector__XXX
 SG_ NR_01_KD_Fehler : 63|1@1+ (1.0,0.0) [0.0|1] ""  ICAS1_X_Gateway

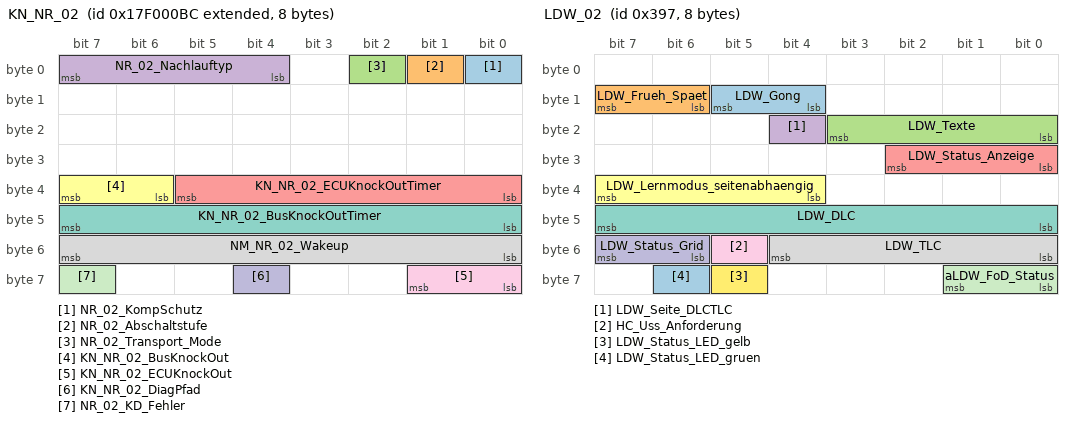
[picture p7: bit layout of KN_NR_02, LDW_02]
BO_ 2549088444 KN_NR_02: 8 NR_2
 SG_ NR_02_KompSchutz : 0|1@1+ (1.0,0.0) [0.0|1] ""  Vector__XXX
 SG_ NR_02_Abschaltstufe : 1|1@1+ (1.0,0.0) [0.0|1] ""  Vector__XXX
 SG_ NR_02_Transport_Mode : 2|1@1+ (1.0,0.0) [0.0|1] ""  Vector__XXX
 SG_ NR_02_Nachlauftyp : 4|4@1+ (1.0,0.0) [0.0|15] ""  ICAS1_X_Gateway
 SG_ KN_NR_02_ECUKnockOutTimer : 32|6@1+ (1,0) [0|62] ""  Vector__XXX
 SG_ KN_NR_02_BusKnockOut : 38|2@1+ (1.0,0.0) [0.0|3] ""  Vector__XXX
 SG_ KN_NR_02_BusKnockOutTimer : 40|8@1+ (1,0) [0|254] ""  Vector__XXX
 SG_ NM_NR_02_Wakeup : 48|8@1+ (1.0,0.0) [0.0|255] ""  Vector__XXX
 SG_ KN_NR_02_ECUKnockOut : 56|2@1+ (1.0,0.0) [0.0|3] ""  Vector__XXX
 SG_ KN_NR_02_DiagPfad : 60|1@1+ (1.0,0.0) [0.0|1] ""  ICAS1_X_Gateway
 SG_ NR_02_KD_Fehler : 63|1@1+ (1.0,0.0) [0.0|1] ""  ICAS1_X_Gateway

BO_ 2621440343 KS_ACC_Req_FD: 16 ICAS1_X_Gateway
 SG_ KS_ACC_Req_FD_Data : 0|128@1+ (1.0,0.0) [0.0|340282366920938463463374607431768211455] ""  FASFrontradar,MRR2023

BO_ 2621571415 KS_ACC_Resp_FD: 16 FASFrontradar
 SG_ KS_ACC_Resp_FD_Data : 0|128@1+ (1.0,0.0) [0.0|340282366920938463463374607431768211455] ""  ICAS1_X_Gateway

BO_ 2621440335 KS_Kamera_Req_FD: 16 ICAS1_X_Gateway
 SG_ KS_Kamera_Req_FD_Data : 0|128@1+ (1.0,0.0) [0.0|340282366920938463463374607431768211455] ""  MFK

BO_ 2621571407 KS_Kamera_Resp_FD: 16 MFK
 SG_ KS_Kamera_Resp_FD_Data : 0|128@1+ (1.0,0.0) [0.0|340282366920938463463374607431768211455] ""  ICAS1_X_Gateway

BO_ 2621440443 KS_NR_01_Req_FD: 16 ICAS1_X_Gateway
 SG_ KS_NR_01_Req_FD_Data : 0|128@1+ (1.0,0.0) [0.0|340282366920938463463374607431768211455] ""  NR_1

BO_ 2621571515 KS_NR_01_Resp_FD: 16 NR_1
 SG_ KS_NR_01_Resp_FD_Data : 0|128@1+ (1.0,0.0) [0.0|340282366920938463463374607431768211455] ""  ICAS1_X_Gateway

BO_ 2621440444 KS_NR_02_Req_FD: 16 ICAS1_X_Gateway
 SG_ KS_NR_02_Req_FD_Data : 0|128@1+ (1.0,0.0) [0.0|340282366920938463463374607431768211455] ""  NR_2

BO_ 2621571516 KS_NR_02_Resp_FD: 16 NR_2
 SG_ KS_NR_02_Resp_FD_Data : 0|128@1+ (1.0,0.0) [0.0|340282366920938463463374607431768211455] ""  ICAS1_X_Gateway

BO_ 919 LDW_02: 8 MFK
 SG_ LDW_Gong : 12|2@1+ (1.0,0.0) [0.0|3] ""  ICAS1_X_Gateway
 SG_ LDW_Frueh_Spaet : 14|2@1+ (1.0,0.0) [0.0|3] ""  ICAS1_X_Gateway
 SG_ LDW_Texte : 16|4@1+ (1.0,0.0) [0.0|15] ""  ICAS1_X_Gateway
 SG_ LDW_Seite_DLCTLC : 20|1@1+ (1.0,0.0) [0.0|1] ""  ICAS1_X_Gateway
 SG_ LDW_Status_Anzeige : 24|3@1+ (1.0,0.0) [0.0|7] ""  ICAS1_X_Gateway
 SG_ LDW_Lernmodus_seitenabhaengig : 36|4@1+ (1.0,0.0) [0.0|15] ""  ICAS1_X_Gateway
 SG_ LDW_DLC : 40|8@1+ (0.01,-1.25) [-1.25|1.25] "Unit_Meter"  ICAS1_X_Gateway
 SG_ LDW_TLC : 48|5@1+ (0.1,0) [0.0|3.0] "Unit_Secon"  ICAS1_X_Gateway
 SG_ HC_Uss_Anforderung : 53|1@1+ (1.0,0.0) [0.0|1] ""  ICAS1_X_Gateway
 SG_ LDW_Status_Grid : 54|2@1+ (1.0,0.0) [0.0|3] ""  ICAS1_X_Gateway
 SG_ aLDW_FoD_Status : 56|2@1+ (1.0,0.0) [0.0|3] ""  ICAS1_X_Gateway
 SG_ LDW_Status_LED_gelb : 61|1@1+ (1.0,0.0) [0.0|1] ""  ICAS1_X_Gateway
 SG_ LDW_Status_LED_gruen : 62|1@1+ (1.0,0.0) [0.0|1] ""  ICAS1_X_Gateway

BO_ 810 LH_EPS_01: 8 ICAS1_X_Gateway
 SG_ EPS_01_CRC : 0|8@1+ (1,0) [0|255] ""  Vector__XXX
 SG_ EPS_01_BZ : 8|4@1+ (1,0) [0|15] ""  Vector__XXX
 SG_ EPS_SpannungsAnf : 12|2@1+ (1.0,0.0) [0.0|3] ""  Vector__XXX
 SG_ EPS_Endanschlag : 14|2@1+ (1.0,0.0) [0.0|3] ""  Vector__XXX
 SG_ EPS_Akustiksignal : 16|1@1+ (1.0,0.0) [0.0|1] ""  Vector__XXX
 SG_ EPS_Fehlerlampe : 17|1@1+ (1.0,0.0) [0.0|1] ""  Vector__XXX
 SG_ EPS_Warnungen : 19|3@1+ (1.0,0.0) [0.0|7] ""  Vector__XXX
 SG_ EPS_PLA_Abbruch : 22|4@1+ (1,0) [0|15] ""  Vector__XXX
 SG_ EPS_PLA_Fehler : 26|4@1+ (1,0) [0|15] ""  Vector__XXX
 SG_ EPS_PLA_Status : 30|4@1+ (1.0,0.0) [0.0|15] ""  Vector__XXX
 SG_ EPS_Charisma_FahrPr : 34|4@1+ (1.0,0.0) [0.0|15] ""  Vector__XXX
 SG_ EPS_Charisma_Status : 38|2@1+ (1.0,0.0) [0.0|3] ""  Vector__XXX
 SG_ EPS_VZ_Zst_Offset_Geradeaus : 40|1@1+ (1.0,0.0) [0.0|1] ""  MFK,MFK120
 SG_ EPS_Lenkerposition : 41|2@1+ (1.0,0.0) [0.0|3] ""  Vector__XXX
 SG_ EPS_Anf_KL : 43|1@1+ (1.0,0.0) [0.0|1] ""  Vector__XXX
 SG_ EPS_ARA_Status : 44|4@1+ (1.0,0.0) [0.0|15] ""  Vector__XXX
 SG_ EPS_Zst_Offset_Geradeaus : 48|9@1+ (0.00306,0) [0.00000|1.55754] "Unit_MilliMeter"  MFK,MFK120

BO_TX_BU_ 1985 :FASFrontradar,MRR2023;
BO_TX_BU_ 2621571159 :FASFrontradar,MRR2023;
BO_TX_BU_ 2527679684 :MFK,MFK120;
BO_TX_BU_ 2589283730 :MFK,MFK120;
BO_TX_BU_ 792 :MFK,MFK120;
BO_TX_BU_ 2549088343 :FASFrontradar,MRR2023;
BO_TX_BU_ 2549088335 :MFK,MFK120;
BO_TX_BU_ 2621571415 :FASFrontradar,MRR2023;
BO_TX_BU_ 919 :MFK,MFK120;
CM_ BO_ 2621505536 "VWAG Diagnose funktionaler Request auf CANFD";
CM_ BO_ 960 "MQB";
CM_ BO_ 1640 "ab MQB IS-4";
CM_ BO_ 1505 "ab MQB 7.3";
CM_ BO_ 919 "ab MQB ohne CHK/BZ, LDW_SW_Warnung_links/rechts, KD-Fehler und mit Zyklus 100ms";
CM_ BO_ 810 "MQB: 50ms (für CAN-SG), geändertes Charisma, Entfall KD-Fehler";

CM_ SG_ 588 ASW_Akustik_Einstellung "Einstellung der Akustik der Funktion ASW.";
CM_ SG_ 588 ASW_Ausgabemodus_BFS "Ansteuerinformationen der ASW Aktoren";
CM_ SG_ 588 ASW_Ausgabemodus_FS "Ansteuerinformationen der ASW Aktoren";
CM_ SG_ 588 ASW_Ausgabemodus_HBFS "Ansteuerinformationen der ASW Aktoren";
CM_ SG_ 588 ASW_Ausgabemodus_HFS "Ansteuerinformationen der ASW Aktoren";
CM_ SG_ 588 ASW_Kombiausgabe "ASW_Kombiausgabe bestimmt, welcher Text im Kombi angezeigt wird. Darüber hinaus werden auch Kombi-Akkustik durch dieses Signal ausgelöst.";
CM_ SG_ 588 ASW_Kombitexte "ASW_Kombitexte bestimmt welcher Text im Kombi angezeigt wird. Darüber hinaus werden auch Kombi-Akkustik durch dieses Signal ausgelöst.

Dieses Signal ersetzt SWA_Anzeigen für den ASW-Anteil. Der SWA-Anteil des alten Signals findet sich in SWA-Kombitexte";
CM_ SG_ 588 ASW_Modus "gibt die Verfügbarkeit der ASW Modus an";
CM_ SG_ 588 ASW_Status "Funktionsstatus Ausstiegswarnung (ASW)";
CM_ SG_ 588 ASW_Ton_Richtung_HL "ASW-Warntonausgabe hinten links";
CM_ SG_ 588 ASW_Ton_Richtung_HR "ASW_Warntonausgabe hinten rechts";
CM_ SG_ 588 ASW_Ton_Richtung_VL "ASW-Warntonausgabe vorne links";
CM_ SG_ 588 ASW_Ton_Richtung_VR "ASW-Warntonausgabe vorne rechts";
CM_ SG_ 588 ASW_Warnung_BFS "Modus Beifahrerseite der Funktion Ausstiegswarnung (ASW)";
CM_ SG_ 588 ASW_Warnung_FS "Modus Beifahrerseite der Funktion Ausstiegswarnung (ASW)";
CM_ SG_ 588 Heckradar_Kombitexte "Heckradar_Kombitexte bestimmt welcher Text im Kombi angezeigt wird. Darüber hinaus werden auch Kombi-Akkustik durch dieses Signal ausgelöst.

Dieses Signal ersetzt SWA_Anzeigen und deckt alle Kombinationsmöglichkeiten der Heckradarfunktionen ab. Die Fun";
CM_ SG_ 588 HRE_Anzeigetexte "HRE-Texte und -Akustik zur Anzeige im Kombiinstrument";
CM_ SG_ 588 RCTA_Kombitexte "RCTA_Kombitexte bestimmt welcher Text im Kombi angezeigt wird. Darüber hinaus werden auch Kombi-Akkustik durch dieses Signal ausgelöst.";
CM_ SG_ 588 SWA_Anzeigen "SWA- Texte und -Akustik zur Anzeige im Kombiinstrument
0x7-0xF = reserviert";
CM_ SG_ 588 SWA_Blindheit_erkannt "SWA erkennt selbständig eigene Blindheit durch äußere Einflüsse.";
CM_ SG_ 588 SWA_Blindheitsverdacht "Signalwert wird auf Blindheitsverdacht_erkannt gesetzt, wenn ein im Datensatz parametrierbarer Schwellwert überschritten wurde.
Das Signal dient als Vorstufe zur SWA Blindheit und schaltet nicht die SWA Funktion ab.";
CM_ SG_ 588 SWA_Brightness_Mode_FPM "Actual mode for brightness settings of function Spurwechselassistent";
CM_ SG_ 588 SWA_FT_RueckLED "SWA/ASW Rückmelde-LED. Zeigt den Aktivierungszustand der Funktionen SWA/ASW";
CM_ SG_ 588 SWA_Gischtzaehler "Zähler, der die eigene Gischt bei nasser Fahrbahn misst (Kennwert)";
CM_ SG_ 588 SWA_Infostufe_Assist_li "Aktion der SWA-Funktion auf der entsprechenden Fahrzeugseite";
CM_ SG_ 588 SWA_Infostufe_Assist_re "Aktion der SWA-Funktion auf der entsprechenden Fahrzeugseite";
CM_ SG_ 588 SWA_Kombiausgabe "SWA_Kombiausgabe bestimmt, welcher Text im Kombi angezeigt wird.";
CM_ SG_ 588 SWA_LED_Ausgabemodus_BFS "Ansteuerung SWA LED Beifahrerseite";
CM_ SG_ 588 SWA_LED_Ausgabemodus_FS "Ansteuerung SWA LED Fahrerseite";
CM_ SG_ 588 SWA_LED_Hell_BFS "Helligkeitswert SWA LED Beifahrerseite";
CM_ SG_ 588 SWA_LED_Hell_FS "Helligkeitswert SWA LED Fahrerseite";
CM_ SG_ 588 SWA_Modus "gibt die Verfügbarkeit der SWA Modus an";
CM_ SG_ 588 SWA_Modus_System "Gibt Zusatzinformationen zum SWA System Status an";
CM_ SG_ 588 SWA_rel_Fehler "Hinweis: In Zukunft das Signal SWA_Modus anstatt SWA_rel_Fehler verwenden!

SWA erkennt einen Fehler, die Objektdetektion betreffend, mit FSP-Eintrag.";
CM_ SG_ 588 SWA_rel_Nichtverf "Hinweis: In Zukunft das Signal SWA_Modus anstatt SWA_rel_Nichtverf verwenden!

SWA erkennt eine Nichtverfuegbarkeit, die Objektdetektion betreffend, ohne FSP-Eintrag";
CM_ SG_ 588 SWA_Sta_aktiv "SWA Status aktiv; Lampenansteuerung im Kombi";
CM_ SG_ 588 SWA_Sta_passiv "Hinweis: In Zukunft das Signal SWA_Status anstatt SWA_Sta_passiv verwenden!

SWA Status passiv; Lampenansteuerung im Kombi";
CM_ SG_ 588 SWA_Standziele_li "Hinweis: In Zukunft das Signal SWA_StrukturLinks_querAbstand anstatt SWA_Standziele_li verwenden!

Abstand zwischen Fahrzeug und Standziele links geringer als ein applizierbarer Wert.";
CM_ SG_ 588 SWA_Standziele_re "Hinweis: In Zukunft das Signal SWA_StrukturRechts_querAbstand anstatt SWA_Standziele_re verwenden!

Abstand zwischen Fahrzeug und Standziele links geringer als ein applizierbarer Wert.";
CM_ SG_ 588 SWA_Status "gibt die Verfügbarkeit der SWA_Status an";
CM_ SG_ 588 SWA_Status_KuFu "Gibt den Status der Kundenfunktion SWA an";
CM_ SG_ 588 SWA_Status_System "Gibt den Status des Systems SWA an";
CM_ SG_ 588 SWA_Warnstufe_Assist_li "Aktion der SWA-Funktion auf der entsprechenden Fahrzeugseite";
CM_ SG_ 588 SWA_Warnstufe_Assist_re "Aktion der SWA-Funktion auf der entsprechenden Fahrzeugseite";

CM_ SG_ 589 SWA_Infostufe_SWA_li "Aktion der SWA-Funktion auf der entsprechenden Fahrzeugseite";
CM_ SG_ 589 SWA_Infostufe_SWA_re "Aktion der SWA-Funktion auf der entsprechenden Fahrzeugseite";
CM_ SG_ 589 SWA_Kolonne_li "Info, dass auf der entspr. Spur mehr als zwei Fahrzeuge zu finden sind. ";
CM_ SG_ 589 SWA_Kolonne_mi "Info, dass auf der entspr. Spur mehr als zwei Fahrzeuge zu finden sind. ";
CM_ SG_ 589 SWA_Kolonne_re "Info, dass auf der entspr. Spur mehr als zwei Fahrzeuge zu finden sind. ";
CM_ SG_ 589 SWA_Obj_01_Breite "Breite des Objektes in Metern";
CM_ SG_ 589 SWA_Obj_01_Existenzwahrsch "Existenzwahrscheinlichkeit des Objektes in Prozent";
CM_ SG_ 589 SWA_Obj_01_Gemessen "Status Objekt gemessen/getrackt";
CM_ SG_ 589 SWA_Obj_01_GeschwRelX "Relative Geschwindigkeit in x (m/s)
Geschwindigkeiten beziehen sich immer auf den Objektmittelpunkt
Messung in Radialrichtung";
CM_ SG_ 589 SWA_Obj_01_GeschwRelY "Relative Geschwindigkeit in y (m/s)
Geschwindigkeiten beziehen sich immer auf den Objektmittelpunkt";
CM_ SG_ 589 SWA_Obj_01_ID "ID des Objektes";
CM_ SG_ 589 SWA_Obj_01_Laenge "Länge des Objektes in Metern";
CM_ SG_ 589 SWA_Obj_01_Objektklasse "Gibt die Objektklasse an.
Unbekannt: dynamisches oder statisches Objekt; alle nicht zu klassifizierenden nicht über- oder unterfahrbaren Objekte, wie Spielzeug (z.B. Trettraktor) oder Sonderfahrzeuge (u.a. Trike, Quad, Straßenbahn, Rikschas, Kutschen)
D";
CM_ SG_ 589 SWA_Obj_01_PositionX "Position des Objektes in x-Richtung (Referenzpunkt der 3D-Objektbox)";
CM_ SG_ 589 SWA_Obj_01_PositionY "Position des Objektes in y-Richtung (Referenzpunkt der 3D-Objektbox)";
CM_ SG_ 589 SWA_Obj_01_ReferenzPkt "Der Bezugspunkt eines detektierten Objektes zeigt den kürzesten direkten Abstand zur Mitte der EGO-Vorderkante";
CM_ SG_ 589 SWA_Obj_02_Breite "Breite des Objektes in Metern";
CM_ SG_ 589 SWA_Obj_02_Existenzwahrsch "Existenzwahrscheinlichkeit des Objektes in Prozent";
CM_ SG_ 589 SWA_Obj_02_Gemessen "Status der PositionY des Objektes 
0 - ObjektpositionY_geschaetzt (Kalibrierung nicht abgeschlossen, hohe Entfernung, etc.)
1 - ObjektpositionY_bestaetigt (Messung hinreichend genau)";
CM_ SG_ 589 SWA_Obj_02_GeschwRelX "Relative Geschwindigkeit in x (m/s)
Geschwindigkeiten beziehen sich immer auf den Objektmittelpunkt
Messung in Radialrichtung";
CM_ SG_ 589 SWA_Obj_02_GeschwRelY "Relative Geschwindigkeit in y (m/s)
Geschwindigkeiten beziehen sich immer auf den Objektmittelpunkt";
CM_ SG_ 589 SWA_Obj_02_ID "ID des Objektes";
CM_ SG_ 589 SWA_Obj_02_Laenge "Länge des Objektes in Metern";
CM_ SG_ 589 SWA_Obj_02_Objektklasse "Gibt die Objektklasse an.
Unbekannt: dynamisches oder statisches Objekt; alle nicht zu klassifizierenden nicht über- oder unterfahrbaren Objekte, wie Spielzeug (z.B. Trettraktor) oder Sonderfahrzeuge (u.a. Trike, Quad, Straßenbahn, Rikschas, Kutschen)
D";
CM_ SG_ 589 SWA_Obj_02_PositionX "Position des Objektes in x-Richtung (Referenzpunkt der 3D-Objektbox)";
CM_ SG_ 589 SWA_Obj_02_PositionY "Position des Objektes in y-Richtung (Referenzpunkt der 3D-Objektbox)";
CM_ SG_ 589 SWA_Obj_02_ReferenzPkt "Der Bezugspunkt eines detektierten Objektes zeigt den kürzesten direkten Abstand zur Mitte der EGO-Vorderkante";
CM_ SG_ 589 SWA_Obj_03_Breite "Breite des Objektes in Metern";
CM_ SG_ 589 SWA_Obj_03_Existenzwahrsch "Existenzwahrscheinlichkeit des Objektes in Prozent";
CM_ SG_ 589 SWA_Obj_03_Gemessen "Status der PositionY des Objektes 
0 - ObjektpositionY_geschaetzt (Kalibrierung nicht abgeschlossen, hohe Entfernung, etc.)
1 - ObjektpositionY_bestaetigt (Messung hinreichend genau)";
CM_ SG_ 589 SWA_Obj_03_GeschwRelX "Relative Geschwindigkeit in x (m/s)
Geschwindigkeiten beziehen sich immer auf den Objektmittelpunkt
Messung in Radialrichtung";
CM_ SG_ 589 SWA_Obj_03_GeschwRelY "Relative Geschwindigkeit in y (m/s)
Geschwindigkeiten beziehen sich immer auf den Objektmittelpunkt";
CM_ SG_ 589 SWA_Obj_03_ID "ID des Objektes";
CM_ SG_ 589 SWA_Obj_03_Laenge "Länge des Objektes in Metern";
CM_ SG_ 589 SWA_Obj_03_Objektklasse "Gibt die Objektklasse an.
Unbekannt: dynamisches oder statisches Objekt; alle nicht zu klassifizierenden nicht über- oder unterfahrbaren Objekte, wie Spielzeug (z.B. Trettraktor) oder Sonderfahrzeuge (u.a. Trike, Quad, Straßenbahn, Rikschas, Kutschen)
D";
CM_ SG_ 589 SWA_Obj_03_PositionX "Position des Objektes in x-Richtung (Referenzpunkt der 3D-Objektbox)";
CM_ SG_ 589 SWA_Obj_03_PositionY "Position des Objektes in y-Richtung (Referenzpunkt der 3D-Objektbox)";
CM_ SG_ 589 SWA_Obj_03_ReferenzPkt "Der Bezugspunkt eines detektierten Objektes zeigt den kürzesten direkten Abstand zur Mitte der EGO-Vorderkante";
CM_ SG_ 589 SWA_Obj_04_Breite "Breite des Objektes in Metern";
CM_ SG_ 589 SWA_Obj_04_Existenzwahrsch "Existenzwahrscheinlichkeit des Objektes in Prozent";
CM_ SG_ 589 SWA_Obj_04_Gemessen "Status der PositionY des Objektes 
0 - ObjektpositionY_geschaetzt (Kalibrierung nicht abgeschlossen, hohe Entfernung, etc.)
1 - ObjektpositionY_bestaetigt (Messung hinreichend genau)";
CM_ SG_ 589 SWA_Obj_04_GeschwRelX "Relative Geschwindigkeit in x (m/s)
Geschwindigkeiten beziehen sich immer auf den Objektmittelpunkt
Messung in Radialrichtung";
CM_ SG_ 589 SWA_Obj_04_GeschwRelY "Relative Geschwindigkeit in y (m/s)
Geschwindigkeiten beziehen sich immer auf den Objektmittelpunkt";
CM_ SG_ 589 SWA_Obj_04_ID "ID des Objektes";
CM_ SG_ 589 SWA_Obj_04_Laenge "Länge des Objektes in Metern";
CM_ SG_ 589 SWA_Obj_04_Objektklasse "Gibt die Objektklasse an.
Unbekannt: dynamisches oder statisches Objekt; alle nicht zu klassifizierenden nicht über- oder unterfahrbaren Objekte, wie Spielzeug (z.B. Trettraktor) oder Sonderfahrzeuge (u.a. Trike, Quad, Straßenbahn, Rikschas, Kutschen)
D";
CM_ SG_ 589 SWA_Obj_04_PositionX "Position des Objektes in x-Richtung (Referenzpunkt der 3D-Objektbox)";
CM_ SG_ 589 SWA_Obj_04_PositionY "Position des Objektes in y-Richtung (Referenzpunkt der 3D-Objektbox)";
CM_ SG_ 589 SWA_Obj_04_ReferenzPkt "Der Bezugspunkt eines detektierten Objektes zeigt den kürzesten direkten Abstand zur Mitte der EGO-Vorderkante";
CM_ SG_ 589 SWA_Obj_05_Breite "Breite des Objektes in Metern";
CM_ SG_ 589 SWA_Obj_05_Existenzwahrsch "Existenzwahrscheinlichkeit des Objektes in Prozent";
CM_ SG_ 589 SWA_Obj_05_Gemessen "Status der PositionY des Objektes 
0 - ObjektpositionY_geschaetzt (Kalibrierung nicht abgeschlossen, hohe Entfernung, etc.)
1 - ObjektpositionY_bestaetigt (Messung hinreichend genau)";
CM_ SG_ 589 SWA_Obj_05_GeschwRelX "Relative Geschwindigkeit in x (m/s)
Geschwindigkeiten beziehen sich immer auf den Objektmittelpunkt
Messung in Radialrichtung";
CM_ SG_ 589 SWA_Obj_05_GeschwRelY "Relative Geschwindigkeit in y (m/s)
Geschwindigkeiten beziehen sich immer auf den Objektmittelpunkt";
CM_ SG_ 589 SWA_Obj_05_ID "ID des Objektes";
CM_ SG_ 589 SWA_Obj_05_Laenge "Länge des Objektes in Metern";
CM_ SG_ 589 SWA_Obj_05_Objektklasse "Gibt die Objektklasse an.
Unbekannt: dynamisches oder statisches Objekt; alle nicht zu klassifizierenden nicht über- oder unterfahrbaren Objekte, wie Spielzeug (z.B. Trettraktor) oder Sonderfahrzeuge (u.a. Trike, Quad, Straßenbahn, Rikschas, Kutschen)
D";
CM_ SG_ 589 SWA_Obj_05_PositionX "Position des Objektes in x-Richtung (Referenzpunkt der 3D-Objektbox)";
CM_ SG_ 589 SWA_Obj_05_PositionY "Position des Objektes in y-Richtung (Referenzpunkt der 3D-Objektbox)";
CM_ SG_ 589 SWA_Obj_05_ReferenzPkt "Der Bezugspunkt eines detektierten Objektes zeigt den kürzesten direkten Abstand zur Mitte der EGO-Vorderkante";
CM_ SG_ 589 SWA_Obj_06_Breite "Breite des Objektes in Metern";
CM_ SG_ 589 SWA_Obj_06_Existenzwahrsch "Existenzwahrscheinlichkeit des Objektes in Prozent";
CM_ SG_ 589 SWA_Obj_06_Gemessen "Status der PositionY des Objektes 
0 - ObjektpositionY_geschaetzt (Kalibrierung nicht abgeschlossen, hohe Entfernung, etc.)
1 - ObjektpositionY_bestaetigt (Messung hinreichend genau)";
CM_ SG_ 589 SWA_Obj_06_GeschwRelX "Relative Geschwindigkeit in x (m/s)
Geschwindigkeiten beziehen sich immer auf den Objektmittelpunkt
Messung in Radialrichtung";
CM_ SG_ 589 SWA_Obj_06_GeschwRelY "Relative Geschwindigkeit in y (m/s)
Geschwindigkeiten beziehen sich immer auf den Objektmittelpunkt";
CM_ SG_ 589 SWA_Obj_06_ID "ID des Objektes";
CM_ SG_ 589 SWA_Obj_06_Laenge "Länge des Objektes in Metern";
CM_ SG_ 589 SWA_Obj_06_Objektklasse "Gibt die Objektklasse an.
Unbekannt: dynamisches oder statisches Objekt; alle nicht zu klassifizierenden nicht über- oder unterfahrbaren Objekte, wie Spielzeug (z.B. Trettraktor) oder Sonderfahrzeuge (u.a. Trike, Quad, Straßenbahn, Rikschas, Kutschen)
D";
CM_ SG_ 589 SWA_Obj_06_PositionX "Position des Objektes in x-Richtung (Referenzpunkt der 3D-Objektbox)";
CM_ SG_ 589 SWA_Obj_06_PositionY "Position des Objektes in y-Richtung (Referenzpunkt der 3D-Objektbox)";
CM_ SG_ 589 SWA_Obj_06_ReferenzPkt "Der Bezugspunkt eines detektierten Objektes zeigt den kürzesten direkten Abstand zur Mitte der EGO-Vorderkante";
CM_ SG_ 589 SWA_Obj_Kurvenradius "Kurvenradius ermittelt aus dem zurückgelegten Streckenverlauf in Metern. Die aktuelle Berechnungsgrundlage für die kurvenbereinigte PositionY der ausgegebenen Objekte.";
CM_ SG_ 589 SWA_StrukturLinks_querAbstand "Abstand zur Randbebauung auf der entsprechenden Fahrzeugseite bezogen auf die Mitte der Hinterachse von dem Ego-Fahrzeug.";
CM_ SG_ 589 SWA_StrukturLinks_Typ "Typ der vom Heckradar erkannten Randbebauung";
CM_ SG_ 589 SWA_StrukturRechts_querAbstand "Abstand zur Randbebauung auf der entsprechenden Fahrzeugseite bezogen auf die Mitte der Hinterachse von dem Ego-Fahrzeug.";
CM_ SG_ 589 SWA_StrukturRechts_Typ "Typ der vom Heckradar erkannten Randbebauung";
CM_ SG_ 589 SWA_Umfeld_Zeitstempel "Das Signal beschreibt den Messzeitpunkt zu dem die Messdaten erfasst worden sind in Sekunden.";
CM_ SG_ 589 SWA_Umfeld_Zeitstempel_Status "Das Signal beschreibt die Art der Zeitsynchonisierung und ggf. die Fehlerursache bei fehlender Zeitstempelausgabe.";
CM_ SG_ 589 SWA_Warnung_SWA_li "Aktion der SWA-Funktion auf der entsprechenden Fahrzeugseite";
CM_ SG_ 589 SWA_Warnung_SWA_re "Aktion der SWA-Funktion auf der entsprechenden Fahrzeugseite";

CM_ SG_ 2463978813 HVL_01_BZ "4bit Botschaftszähler, wird mit jeder Sendebotschaft inkrementiert";
CM_ SG_ 2463978813 HVL_01_CRC "Für MLB:
Berechnung siehe Lastenheft 'Kommunikationsabsicherung für FlexRay und CAN'
Ab MQB und MLBevo:
Berechnung siehe Lastenheft 'End-to-End Kommunikationsabsicherung'

Endwerte siehe Begleitdokument 'S-PDU Kennungsfolgen'";
CM_ SG_ 2463978813 HVL_HVK_Fehler_DCAbschaltung "Status der Anforderung einer DC-Laden-Notabschaltung";
CM_ SG_ 2463978813 HVL_Kuehltemperatur "Istwert der OCC-Kühlkanaltemperatur";
CM_ SG_ 2463978813 HVL_LadeAnforderung "FuSi-Abgesicherte Ladeanforderung an den HVK";
CM_ SG_ 2463978813 HVL_OCC_IstModus "aktueller Funktionszustand des OCC";
CM_ SG_ 2463978813 HVL_Status_EoHVL "Erkennung einer offenen HV-Leitung (EoHVL), bewertet anhand einer Spannungsgrenze";
CM_ SG_ 2463978813 HVL_Status_Spgfreiheit "Status der Spannungsfreiheit für den Onboard Charge Client";
CM_ SG_ 2463978813 HVL_Steckerstatus "Stellt den Status des Ladesteckers hinsichtlich Präsenz zur Verfügung";

CM_ SG_ 2463978891 CabinCare_Enable "HMI to MIK ECU to transmit the de-/activation by the customer.";
CM_ SG_ 2463978891 ICV_Switch_AspectRatio "This signal is needed to configure the image and video's aspect ratio(e.g. 4:3, 16:9, 3:4, 9:16)";
CM_ SG_ 2463978891 ICV_Switch_Brightness "This signal is needed to configure the brightness (0...100%)";
CM_ SG_ 2463978891 ICV_Switch_ColorMode "This signal is needed to configure the color mode (init, RGB, IR)";
CM_ SG_ 2463978891 ICV_Switch_Contrast "This signal is needed to configure the contrast (0...100%)";
CM_ SG_ 2463978891 ICV_Switch_FieldOfView "This signal is needed to configure the field of view (Driver, CoDriver and FullCabin)";
CM_ SG_ 2463978891 ICV_Switch_FrameRate "This signal is needed to configure the framerate (15...30 frames per seconds)";
CM_ SG_ 2463978891 ICV_Switch_FunctionState "This signal is needed to configure the MIK function state";
CM_ SG_ 2463978891 ICV_Switch_HDR "This signal is needed to configure the High Dynamic Range Image (HDR) of the videostream (init, on, off)";
CM_ SG_ 2463978891 ICV_Switch_Resolution "The signal is needed to configure the resolution (160x120, 320x240, 640x480, 1280x720, 1920x1080)";
CM_ SG_ 2463978891 ICV_Switch_VideoLength "This signal is needed to configure the short video length to fits the social media directly. e.g. Tiktok, wechat. (init, 15s, 30s, 60s, customized)";
CM_ SG_ 2463978891 PetsMode_Enable "HMI to MIK ECU to transmit the de-/activation by the customer.";
CM_ SG_ 2463978891 Selfie_Switch_FunctionState "This signal is needed to configure the Selfie function state(init, VideoShot_Start, VideoShot_Stop, PhotoShot_Single, PhotoShot_Continuous, Cancel)";
CM_ SG_ 2463978891 Selfie_Switch_Resolution "This signal is needed to configure the image's resolution (int, 5M pixels, 2M pixels)";

CM_ SG_ 1524 AMB_Charisma_FahrPr "MLBevo: Aktuelles Fahrprogramm des Charisma-Teilnehmers (siehe Systemlastenheft Drive Select)
MQB: Istwert der Kennlinie (siehe Systemlastenheft MQB FPA)";
CM_ SG_ 1524 AMB_Charisma_Status "Systemstatus des Charismateilnehmers

Wert 0x3 ist nur für Fahrzeuge ab MQB relevant";
CM_ SG_ 1524 BCM1_DI_Rampe_Innenlicht "Dimmrampe Innenlicht";
CM_ SG_ 1524 BCM1_DI_Rampe_Leselicht "Dimmrampe Leselicht";
CM_ SG_ 1524 BCM1_Innenlicht_gedimmt_H "Steuerung von BCM_Innenlicht_H";
CM_ SG_ 1524 BCM1_Innenlicht_gedimmt_V "Steuerung von BCM_Innenlicht_V";
CM_ SG_ 1524 BCM1_Innenlicht_H "Anforderung Innenlicht hinten";
CM_ SG_ 1524 BCM1_Innenlicht_V "Anforderung Innenlicht vorne";
CM_ SG_ 1524 BCM1_Leselicht_Anf_hl " Leselicht hinten links Anforderung";
CM_ SG_ 1524 BCM1_Leselicht_Anf_hr "Leselicht hinten rechts Anforderung";
CM_ SG_ 1524 BCM1_Leselicht_Anf_vl "Leselicht vorne links Anforderung";
CM_ SG_ 1524 BCM1_Leselicht_Anf_vr "Leselicht vorne rechts Anforderung";
CM_ SG_ 1524 BCM1_Leuchten_Aus "Innenbeleuchtung ausschalten (keine Änderung / ausschalten)";
CM_ SG_ 1524 IL_Bel_BFS_Ausstieg "Einschalten der Ausstiegsleuchten oder Türwarnleuchten in Tür oder im Schweller";
CM_ SG_ 1524 IL_Bel_FS_Ausstieg "Einschalten der Ausstiegsleuchten oder Türwarnleuchten in Tür oder im Schweller";
CM_ SG_ 1524 IL_Bel_HBFS_Ausstieg "Einschalten der Ausstiegsleuchten oder Türwarnleuchten in Tür oder im Schweller";
CM_ SG_ 1524 IL_Bel_HFS_Ausstieg "Einschalten der Ausstiegsleuchten oder Türwarnleuchten in Tür oder im Schweller";
CM_ SG_ 1524 IL_Dimmung_H_Tuerkontur "Dimmung Türkontur hinten (bei Änderung im 30 ms Raster)";
CM_ SG_ 1524 IL_Dimmung_Lautspr "Dimmung Umfeldbeleuchtung an Türaußenseite oder Außenspiegel";
CM_ SG_ 1524 IL_Dimmung_Tuerinnengriff "Dimmung Türinnengriff";
CM_ SG_ 1524 IL_Dimmung_Umfeldbel "Dimmung Umfeldbeleuchtung an Türaußenseite oder Außenspiegel";
CM_ SG_ 1524 IL_Dimmung_V_Tuerkontur "Dimmung Türkontur vorne (bei Änderung im 30 ms Raster)";
CM_ SG_ 1524 IL_Innenlicht_aktiv "Status Innenlicht";
CM_ SG_ 1524 IL_Klemme_30G_aktiv "Synchrones Abschalten";
CM_ SG_ 1524 IL_Tuerkontakt_Taster "Statussignal des Türkontakts-Tasters der Dachkonsole";

CM_ SG_ 1879 ISO_ACC_Req_Data "OffBoard Tester Diagnose Request ACC";

CM_ SG_ 1985 ISO_ACC_Resp_Data "OffBoard Tester Diagnose Response ACC";

CM_ SG_ 1792 ISO_ALL_01_Req_Data "Funktionaler Request ALL";

CM_ SG_ 1871 ISO_Kamera_Req_Data "Diagnose Request Kamerasteuergeraet";

CM_ SG_ 1977 ISO_Kamera_Resp_Data "Diagnose Response Kamerasteuergeraet";

CM_ SG_ 2621440087 ISOx_ACC_Req_FD_Data "OffBoard Tester Diagnose Response ACC";

CM_ SG_ 2621571159 ISOx_ACC_Resp_FD_Data "OffBoard Tester Diagnose Response ACC";

CM_ SG_ 2621505536 ISOx_Funkt_Req_All_FD_Data "OffBoard Tester funktionaler Diagnose Request ALL CANFD";

CM_ SG_ 2621440079 ISOx_Kamera_Req_FD_Data "Diagnose Request Kamera";

CM_ SG_ 2621571151 ISOx_Kamera_Resp_FD_Data "Diagnose Response Kamera";

CM_ SG_ 2549874875 ISOx_NR_01_Req_Data "OffBoard Tester Diagnose Request NR_01";

CM_ SG_ 2621440187 ISOx_NR_01_Req_FD_Data "OffBoard Tester Diagnose Response NR_01";

CM_ SG_ 2550005947 ISOx_NR_01_Resp_Data "OffBoard Tester Diagnose Response NR_01";

CM_ SG_ 2621571259 ISOx_NR_01_Resp_FD_Data "OffBoard Tester Diagnose Response NR_01";

CM_ SG_ 2549874876 ISOx_NR_02_Req_Data "OffBoard Tester Diagnose Request NR_02";

CM_ SG_ 2621440188 ISOx_NR_02_Req_FD_Data "OffBoard Tester Diagnose Response NR_02";

CM_ SG_ 2550005948 ISOx_NR_02_Resp_Data "OffBoard Tester Diagnose Response NR_02";

CM_ SG_ 2621571260 ISOx_NR_02_Resp_FD_Data "OffBoard Tester Diagnose Response NR_02";

CM_ SG_ 2527679667 Kamera_AHC_L_Funktionsstatus "Gibt den aktuellen Funktionsstatus der AHC Bildverarbeitung an.";
CM_ SG_ 2527679667 Kamera_AHC_L_Gierwinkel "Gibt den gemessenen Gierwinkel des charakteristischen Punktes der Scheinwerfer-Onlinekalibrierung an.";
CM_ SG_ 2527679667 Kamera_AHC_L_Nickwinkel "Gibt den gemessenen Nickwinkel des charakteristischen Punktes der Scheinwerfer-Onlinekalibrierung an.";
CM_ SG_ 2527679667 Kamera_AHC_L_Qualitaet "Gibt die Qualität der Erkennung des charakteristischen Punktes der Scheinwerfer-Onlinekalibrierung an.";
CM_ SG_ 2527679667 Kamera_AHC_L_ROI_ID "Gibt die verwendete ROI der Scheinwerfer-Onlinekalibrierung an.";
CM_ SG_ 2527679667 Kamera_AHC_R_Funktionsstatus "Gibt den aktuellen Funktionsstatus der AHC Bildverarbeitung an.";
CM_ SG_ 2527679667 Kamera_AHC_R_Gierwinkel "Gibt den gemessenen Gierwinkel des charakteristischen Punktes der Scheinwerfer-Onlinekalibrierung an.";
CM_ SG_ 2527679667 Kamera_AHC_R_Nickwinkel "Gibt den gemessenen Nickwinkel des charakteristischen Punktes der Scheinwerfer-Onlinekalibrierung an.";
CM_ SG_ 2527679667 Kamera_AHC_R_Qualitaet "Gibt die Qualität der Erkennung des charakteristischen Punktes der Scheinwerfer-Onlinekalibrierung an.";
CM_ SG_ 2527679667 Kamera_AHC_R_ROI_ID "Gibt die verwendete ROI der Scheinwerfer-Onlinekalibrierung an.";

CM_ SG_ 2527679684 Kamera_ASM_Data_1 "Dieses Signal wird von der Frontkamera befüllt und an den Assistenzsystemmonitor ASM gesendet.";
CM_ SG_ 2527679684 Kamera_ASM_Data_2 "Dieses Signal wird von der Frontkamera befüllt und an den Assistenzsystemmonitor ASM gesendet.";
CM_ SG_ 2527679684 Kamera_ASM_Data_3 "Dieses Signal wird von der Frontkamera befüllt und an den Assistenzsystemmonitor ASM gesendet.";
CM_ SG_ 2527679684 Kamera_ASM_Data_4 "Dieses Signal wird von der Frontkamera befüllt und an den Assistenzsystemmonitor ASM gesendet.";
CM_ SG_ 2527679684 Kamera_ASM_Data_5 "Dieses Signal wird von der Frontkamera befüllt und an den Assistenzsystemmonitor ASM gesendet.";
CM_ SG_ 2527679684 Kamera_ASM_Data_6 "Dieses Signal wird von der Frontkamera befüllt und an den Assistenzsystemmonitor ASM gesendet.";
CM_ SG_ 2527679684 Kamera_ASM_Ereignis "Dieses Signal definiert, welche Funktion und welche Art von Aktivität das Senden der Botschaft an den Assistenzsystemmonitor ASM veranlasst hat.";
CM_ SG_ 2527679684 Kamera_ASM_Zeitstempel_02 "Dieses Signal ermöglicht die zeitliche Zuordnung der von der Kamera an den Assistenzsystemmonitor ASM gesendeten Statusbotschaften.";

CM_ SG_ 2589283730 Kamera_SDA_Abstand_Spur_E1 "Abstand in x-Richtung  zum 1. Fahrzeug auf der Ego Spur.";
CM_ SG_ 2589283730 Kamera_SDA_Abstand_Spur_E2 "Abstand in x-Richtung  zum 2. Fahrzeug auf der Ego Spur.";
CM_ SG_ 2589283730 Kamera_SDA_Abstand_Spur_L1 "Abstand in x-Richtung zum 1. Fahrzeug auf der Linken Spur.";
CM_ SG_ 2589283730 Kamera_SDA_Abstand_Spur_L2 "Abstand in x-Richtung  zum 2. Fahrzeug auf der Linken Spur";
CM_ SG_ 2589283730 Kamera_SDA_Abstand_Spur_R1 "Abstand in x-Richtung  zum 1. Fahrzeug auf der Rechten Spur.";
CM_ SG_ 2589283730 Kamera_SDA_Abstand_Spur_R2 "Abstand in x-Richtung  zum 2. Fahrzeug auf der Rechten Spur.";
CM_ SG_ 2589283730 Kamera_SDA_Eigenblendung "Blendung der Kamera.";
CM_ SG_ 2589283730 Kamera_SDA_Geschw_Spur_E "Relative Geschwindigkeit des vorausfahrenden Fahrzeugs auf der Ego-Spur bzgl. der Ego-Fahrzeug Geschwindigkeit.";
CM_ SG_ 2589283730 Kamera_SDA_Geschw_Spur_L "Relative Geschwindigkeit des 1. Fahrzeugs auf der linken Spur bzgl. der Ego-Fahrzeug Geschwindigkeit.";
CM_ SG_ 2589283730 Kamera_SDA_Geschw_Spur_R "Relative Geschwindigkeit des 1. Fahrzeugs auf der rechten Spur bzgl. der Ego-Fahrzeug Geschwindigkeit.";
CM_ SG_ 2589283730 Kamera_SDA_Sichtweite "Selbstwahrnehmung der detektionsreichweite der Kamera.";
CM_ SG_ 2589283730 Kamera_SDA_Status_allg "Allgemeiner Status der Kamera";
CM_ SG_ 2589283730 Kamera_SDA_Status_Beleuchtung "Status der Strassenbeleuchtung";

CM_ SG_ 792 Kamera_FDD_Anz_Strassenleuchten "Anzahl der erkannten Straßenleuchten";
CM_ SG_ 792 Kamera_FDD_Eigenblend "Dieses Signal gibt an, ob von der Kamera eine Eigenblendung, z.B. Nebel, erkannt wird.";
CM_ SG_ 792 Kamera_FDD_Eigenblend_Guete "Diese Signal gibt an, welches Maß einer Eigenblendung vorliegt.";
CM_ SG_ 792 Kamera_FDD_Funktionsstatus "Status der Fahrzeugdetektion bei Dunkelheit";
CM_ SG_ 792 Kamera_FDD_Strassenbeleuchung "Status Straßenbeleuchungsdetektion";
CM_ SG_ 792 Kamera_FDD_Verkehrsrichtung "Gibt bei Nacht die auf Grund der entgegenkommenden Fahrzeuge erkannte Verkehrsrichtung an";
CM_ SG_ 792 Kamera_FSH_aktiv "Bei aktivierter (lokaler) Frontscheibenheizung wird die Scheibentemperaturmessung des Klimafeuchtesensors beeinflusst. Über das Signal wird dem Klima-SG mitgeteilt, dass die lokale Scheibenheizung aktiviert ist, um entsprechende Korrekturwerte bei der Sch";
CM_ SG_ 792 Kamera_Helligkeit "Helligkeitsinformation der gemessenen Aussenhelligkeit der multifunktionalen Kamera
Bei mehr als 10.000 Lux geht das Signal in die Sättigung.";
CM_ SG_ 792 Kamera_Systemzustand "Systemzustand der Kamera";
CM_ SG_ 792 VZE_Status_EDR "Das Signal zeigt den Status der VZE für den EventDataRecorder an.";

CM_ SG_ 960 BCM_Ausparken_Betrieb "Anforderung zur erneuten Lampenaufprüfung und Anzeige von Warnhinweisen nach einem pilotierten Ausparkvorgang (Trigger: fallende Flanke)";
CM_ SG_ 960 Klemmen_Status_01_BZ "4bit Botschaftszaehler; wird in jeder Sendebotschaft inkrementiert";
CM_ SG_ 960 Klemmen_Status_01_CRC "Für MLB:
'Berechnung siehe Lastenheft 'Kommunikationsabsicherung für FlexRay und CAN''

Ab MQB und MLBevo:
'Berechnung siehe Lastenheft 'End-to-End Kommunikationsabsicherung''

Endwerte siehe Begleitdokument 'S-PDU Kennungsfolgen'";
CM_ SG_ 960 KST_Fahrerhinweis_1 "Signalisierung Fahrerhinweis 1 der Klemmensteuerung an das Kombi";
CM_ SG_ 960 KST_Fahrerhinweis_2 "Signalisierung Fahrerhinweis 2 der Klemmensteuerung an das Kombi";
CM_ SG_ 960 KST_Fahrerhinweis_4 "Signalisierung Fahrerhinweis 4 der Klemmensteuerung an das Kombi";
CM_ SG_ 960 KST_Fahrerhinweis_5 "Anzeigesignal für RemoteStart";
CM_ SG_ 960 KST_Fahrerhinweis_6 "Signal aktiviert die Kombi-Anzeigeinstrumente (Drehzahl, Tankinhalt, Kühlmitteltemperatur) während aktiviertem RemoteStart-Betrieb";
CM_ SG_ 960 KST_Warn_P1_ZST_def "Kombi Prio Warnung Klemmensteuerung 
Zündschloß defekt, Service aufsuchen!";
CM_ SG_ 960 KST_Warn_P2_ZST_def "Kombi Prio Warnung Klemmensteuerung
Zündschloß defekt!
";
CM_ SG_ 960 RSt_Fahrerhinweise "Über das Signal fordert das BCM Fahrerhinweise im Kombi für die Funktion RemoteStart an.";
CM_ SG_ 960 ZAS_Kl_15 "Klemme 15: Zuendung (SW-Kl.15)
";
CM_ SG_ 960 ZAS_Kl_50_Startanforderung "Klemme 50: Startwunsch Fahrer
";
CM_ SG_ 960 ZAS_Kl_Infotainment "Separate Klemmeninformation für das Infotainment. Signal entspricht im wesentlichen einer Klemme S Information, kann aber über einen Vor - bzw. Nachlauf zu Klemme S verfügen. 
Ein konkreter Anwendungsfall für einen Nachlauf ist die Abschaltung der Klemme";
CM_ SG_ 960 ZAS_Kl_S "Klemme S: S-Kontakt (Schluessel steckt)
";
CM_ SG_ 960 ZAS_Kl_X "Klemme 75
";

CM_ SG_ 2463978753 Klemmen_Status_02_BZ "4bit Botschaftszähler, wird mit jeder Sendebotschaft inkrementiert";
CM_ SG_ 2463978753 Klemmen_Status_02_CRC "Für MLB:
Berechnung siehe Lastenheft 'Kommunikationsabsicherung für FlexRay und CAN'
Ab MQB und MLBevo:
Berechnung siehe Lastenheft 'End-to-End Kommunikationsabsicherung'

Endwerte siehe Begleitdokument 'S-PDU Kennungsfolgen'";
CM_ SG_ 2463978753 KST_ComfortReadyStatus "Zustand des ComfortReadyStatus über den Komfortfunktionen aktiviert werden können.";
CM_ SG_ 2463978753 KST_Sonderzustand_Anforderung "Hiermit wird die aktive bzw. aktuell angeforderte (s. KST_Sonderzustand_Status) Sonderfunktion identifiziert";
CM_ SG_ 2463978753 KST_Sonderzustand_Status "Hiermit wird signalisiert, dass eine Sonderfunktion aktiv ist und die Klemme 15 durch diese angefordert wurde bzw. ein Übergang von Sonderfunktionen stattfindet";
CM_ SG_ 2463978753 KST_WFS_Fahrfreigabe_Anforderung "Hiermit wird den Wegfahrsperren-Teilnehmern signalisiert welche Art der Fahrfreigabe von der anfordernden Sonderfunktion benötigt wird";

CM_ SG_ 1640 FSH_Taster "Tasterbetätigung Frontscheibenheizung
";
CM_ SG_ 1640 HSH_Taster "An-/Abforderung Heckscheibenheizung über spezielles Tastersignal
";
CM_ SG_ 1640 KL_Beschlagsgefahr "Beschlagsgefahr auf der Frontscheibe im Bereich des Spiegelfusses. Dient zur präventiven Ansteuerung der  Kamera-Scheibenheizung, um Kamera-Blindheit zu vermeiden
PHEV: volle Leistungsfreigabe 
HV Heizer und HV EKK bei Scheibenbeschlag ";
CM_ SG_ 1640 KL_Geblspng_Fond_Soll "Ausgabe des Sollwertes für die Spannung des Klimagebläsemotores hinten.






";
CM_ SG_ 1640 KL_Geblspng_Soll "Ausgabe des Sollwertes für die Spannung des Klimagebläsemotores vorne.







";
CM_ SG_ 1640 KL_I_Geblaese "Stromaufnahme Gebläse";
CM_ SG_ 1640 KL_Kompressorstrom_soll "Sollvorgabe Klima-Kompressorstrom";
CM_ SG_ 1640 KL_LRH_Stufe "Eingestellte Temperaturstufe der Lenkradheizung";
CM_ SG_ 1640 KL_LRH_Taster "Tasterbetätigung Lenkradheizung";
CM_ SG_ 1640 KL_PTC_Verbauinfo "Im Klima- bzw. Heizungsbedienteil wird der Verbau eines PTCs und dessen elektr. Leistungsklasse codiert";
CM_ SG_ 1640 KL_SIH_Soll_li "Einstellung Sitzheizung Fahrer (0...6)";
CM_ SG_ 1640 KL_SIH_Soll_re "Einstellung Sitzheizung Beifahrer (0...6)";
CM_ SG_ 1640 KL_SIL_Soll_li "Einstellung Sitzlüftung Fahrer (0...6)";
CM_ SG_ 1640 KL_SIL_Soll_re "Einstellung Sitzlüftung Beifahrer (0...6)";
CM_ SG_ 1640 KL_Umluftklappe_Status "Status Umluftklappe";
CM_ SG_ 1640 KL_Zuheizer_Freigabe "Freigabe Zuheizer
";
CM_ SG_ 1640 KRH_Soll_li "Ausgabe des Sollwertes für die Kopfraumheizung links.";
CM_ SG_ 1640 KRH_Soll_re "Ausgabe des Sollwertes für die Kopfraumheizung rechts.";

CM_ SG_ 1505 BCM1_Aussen_Temp_ungef "ungefilterter Wert des Aussentemperatursensors
";
CM_ SG_ 1505 BCM1_FStatus_Aussentemp_ungef "Fehlerstatus für Aussentemperatur (Kombianzeige)";
CM_ SG_ 1505 BCM1_Kompressorstrom_ist "IST-Strom vom Klima-Kompressor";
CM_ SG_ 1505 BCM1_OBD_FStatus_ATemp "Fehlerstatus Umgebungstemperatursensor (OBD relevanter Sensor)
";
CM_ SG_ 1505 BCM1_PTC_stufig_Status "Status des BCM1-Heizverbrauchers PTC (stufig)";
CM_ SG_ 1505 BCM_Heizungsabsperrventil_Status "Das Signal beschreibt den Zustand des Heizungsabsperrventils, welches als Portexpander vom BCM1 elektrisch angesteuert wird.";
CM_ SG_ 1505 BCM_Heizungspumpe_Status "Das Signal beschreibt den Zustand der Heizungspumpe, welche als Portexpander vom BCM1 elektrisch angesteuert wird.";
CM_ SG_ 1505 BCM_Kompressorkupplung_Status "Das Signal beschreibt den Zustand der Klimakompressorkupplung, welche als Portexpander vom BCM1 elektrisch angesteuert wird.";

CM_ SG_ 605 KLR_01_BZ "Botschaftszähler";
CM_ SG_ 605 KLR_01_CRC "'Berechnung siehe Lastenheft 'End-to-End Kommunikationsabsicherung''

Endwerte siehe Begleitdokument 'S-PDU Kennungsfolgen'";
CM_ SG_ 605 KLR_Fehler "Fehler im KLR System";
CM_ SG_ 605 KLR_Fehler_Codierung "Erkennung eines Fehlers in der Codierung der Datensatzauswahl im KLR";
CM_ SG_ 605 KLR_reserveByte2_6 "Zweck: Befüllen der reservierten Bitpositionen mit 0 (wg. LIN-Teilnehmer KLR)";
CM_ SG_ 605 KLR_reserveByte6_4 "Zweck: Befüllen der reservierten Bitpositionen mit 0 (wg. LIN-Teilnehmer KLR)";
CM_ SG_ 605 KLR_reserveByte7 "Zweck: Befüllen der reservierten Bitpositionen mit 0 (wg. LIN-Teilnehmer KLR)";
CM_ SG_ 605 KLR_reserveByte8 "Zweck: Befüllen der reservierten Bitpositionen mit 0 (wg. LIN-Teilnehmer KLR)";
CM_ SG_ 605 KLR_ResponseError "siehe LIN2.0-Specification
(Darf nicht über ein Fehlergueltigkeitsbit abgesichtert werden!)";
CM_ SG_ 605 KLR_Touchauswertung "Touchauswertung der KLR-Elektronik";
CM_ SG_ 605 KLR_Touchintensitaet_1 "Diskreter Wert der Touchintensität von 0 bis 250 für Sensor 1";
CM_ SG_ 605 KLR_Touchintensitaet_2 "Diskreter Wert der Touchintensität von 0 bis 250 für Sensor 2";
CM_ SG_ 605 KLR_Touchintensitaet_3 "Diskreter Wert der Touchintensität von 0 bis 250 für Sensor 3";

CM_ SG_ 2549088343 ACC_Abschaltstufe "Funktionseinschränkung aufgrund aktiver Abschaltstufe";
CM_ SG_ 2549088343 ACC_KD_Fehler "Bei gesetztem Bit ist mindestens ein Kundendienstfehler eingetragen";
CM_ SG_ 2549088343 ACC_KompSchutz "Signal wird gesetzt wenn Komponentenschutz (KS) im Steuergerät aktiv ist.";
CM_ SG_ 2549088343 ACC_Nachlauftyp "Abgebildet wird die von der Hardware vorgegebene Möglichkeit, die Kommunikation nach Klemme 15 = AUS aufrecht zu erhalten. Es wird ein Init-Wert gesendet.";
CM_ SG_ 2549088343 ACC_Transport_Mode "Funktionseinschränkung aufgrund aktivem Transport Mode und/oder Transport Schutz";
CM_ SG_ 2549088343 KN_ACC_BusKnockOut "Ausgabe des BusKnockout-Status";
CM_ SG_ 2549088343 KN_ACC_BusKnockOutTimer "Ausgabe des BusKnockOut-Timer";
CM_ SG_ 2549088343 KN_ACC_DiagPfad "Kennzeichnung der Diagnosefähigkeit des BusInterfaces eines Steuergerätes (Knoten) 
Umfang LAH 80127 
 
Bei Nutzung des Signal explizit pro angebundenem BusInterface zu setzen: 
MQB auf E-CAN = 0 (aktiv) 
MQB2020 auf FAS-CAN = 0 (aktiv) 
MLBevo GEN1";
CM_ SG_ 2549088343 KN_ACC_ECUKnockOut "Ausgabe des ECUKnockout-Status";
CM_ SG_ 2549088343 KN_ACC_ECUKnockOutTimer "Ausgabe des ECUKnockOut-Timer";
CM_ SG_ 2549088343 NM_ACC_Wakeup "enthält die Weckursache; stehen mehrere Weckursachen parallel an, dann muss der kleinste Wert übertragen werden";

CM_ SG_ 2549088272 Gateway_Abschaltstufe "Funktionseinschränkung aufgrund aktiver Abschaltstufe";
CM_ SG_ 2549088272 Gateway_KompSchutz "Funktionseinschränkung aufgrund Komponentenschutz aktiv";
CM_ SG_ 2549088272 Gateway_Nachlauftyp "Abgebildet wird die von der Hardware vorgegebene Möglichkeit, die Kommunikation nach Klemme 15 = AUS aufrecht zu erhalten. Es wird ein Init-Wert gesendet.";
CM_ SG_ 2549088272 Gateway_Transport_Mode "Funktionseinschränkung aufgrund aktivem Transport Mode und/oder Transport Schutz";
CM_ SG_ 2549088272 GW_KD_Fehler "Kundendienstfehlerbit Gateway zur Anzeige eines im Gateway abgelegten Fehlerspeichereintrages.";
CM_ SG_ 2549088272 KN_GW_DiagPfad "Kennzeichnung der Diagnosefähigkeit des BusInterfaces eines Steuergerätes (Knoten)
Umfang LAH 80127

Bei Nutzung des Signal explizit pro angebundenem BusInterface zu setzen:
MQB auf Diag-CAN = 0 (aktiv)
MLBevo auf Diag-CAN = 0 (aktiv)
alle weiteren ";
CM_ SG_ 2549088272 NM_Gateway_Wakeup "enthält die Weckursache; stehen mehrere Weckursachen parallel an, dann muss der kleinste Wert übertragen werden";

CM_ SG_ 2549088335 Kamera_Abschaltstufe "Funktionseinschränkung aufgrund aktiver Abschaltstufe";
CM_ SG_ 2549088335 Kamera_KD_Fehler "Bei gesetztem Bit ist mindestens ein Kundendienstfehler eingetragen";
CM_ SG_ 2549088335 Kamera_KompSchutz "Funktionseinschränkung aufgrund Komponentenschutz aktiv";
CM_ SG_ 2549088335 Kamera_Nachlauftyp "Abgebildet wird die von der Hardware vorgegebene Möglichkeit, die Kommunikation nach Klemme 15 = AUS aufrecht zu erhalten. Es wird ein Init-Wert gesendet.";
CM_ SG_ 2549088335 Kamera_Transport_Mode "Funktionseinschränkung aufgrund aktivem Transport Mode und/oder Transport Schutz";
CM_ SG_ 2549088335 KN_Kamera_BusKnockOut "Ausgabe des BusKnockout-Status";
CM_ SG_ 2549088335 KN_Kamera_BusKnockOutTimer "Ausgabe des BusKnockOut-Timer";
CM_ SG_ 2549088335 KN_Kamera_DiagPfad "Kennzeichnung der Diagnosefähigkeit des BusInterfaces eines Steuergerätes (Knoten) 
Umfang LAH 80127 
 
Bei Nutzung des Signal explizit pro angebundenem BusInterface zu setzen: 
MQB auf E-CAN = 0 (aktiv) 
MQB2020 auf FAS-CAN = 0 (aktiv) 
E3_1_1_MEB ";
CM_ SG_ 2549088335 KN_Kamera_ECUKnockOut "Ausgabe des ECUKnockout-Status";
CM_ SG_ 2549088335 KN_Kamera_ECUKnockOutTimer "Ausgabe des ECUKnockOut-Timer";
CM_ SG_ 2549088335 NM_Kamera_Wakeup "enthält die Weckursache; stehen mehrere Weckursachen parallel an, dann muss der kleinste Wert übertragen werden";

CM_ SG_ 2549088313 KN_MIK_BusKnockOut "Ausgabe des BusKnockout-Status";
CM_ SG_ 2549088313 KN_MIK_BusKnockOutTimer "Ausgabe des BusKnockOut-Timer";
CM_ SG_ 2549088313 KN_MIK_DiagPfad "Kennzeichnung der Diagnosefähigkeit des BusInterfaces eines Steuergerätes (Knoten)
Umfang LAH 80127

Bei Nutzung des Signal explizit pro angebundenem BusInterface zu setzen:
MQBw_Baseline auf VLAN-FAS = 0 (aktiv)";
CM_ SG_ 2549088313 KN_MIK_ECUKnockOut "Ausgabe des ECUKnockout-Status";
CM_ SG_ 2549088313 KN_MIK_ECUKnockOutTimer "Ausgabe des ECUKnockOut-Timer";
CM_ SG_ 2549088313 MIK_Abschaltstufe "Funktionseinschränkung aufgrund aktiver Abschaltstufe";
CM_ SG_ 2549088313 MIK_KD_Fehler "Bei gesetztem Bit ist mindestens ein Kundendienstfehler eingetragen";
CM_ SG_ 2549088313 MIK_KompSchutz "Funktionseinschränkung aufgrund Komponentenschutz aktiv";
CM_ SG_ 2549088313 MIK_Nachlauftyp "Abgebildet wird die von der Hardware vorgegebene Möglichkeit, die Kommunikation nach Klemme 15 = AUS aufrecht zu erhalten. Es wird ein Init-Wert gesendet.";
CM_ SG_ 2549088313 MIK_Transport_Mode "Funktionseinschränkung aufgrund aktivem Transport Mode und/oder Transport Schutz
";
CM_ SG_ 2549088313 NM_MIK_Wakeup "enthält die Weckursache; stehen mehrere Weckursachen parallel an, dann muss der kleinste Wert übertragen werden";

CM_ SG_ 2549088443 KN_NR_01_BusKnockOut "Ausgabe des BusKnockout-Status";
CM_ SG_ 2549088443 KN_NR_01_BusKnockOutTimer "Ausgabe des BusKnockOut-Timer";
CM_ SG_ 2549088443 KN_NR_01_DiagPfad "Kennzeichnung der Diagnosefähigkeit des BusInterfaces eines Steuergerätes (Knoten)
Umfang LAH 80127

Bei Nutzung des Signal explizit pro angebundenem BusInterface zu setzen:
MQBw_Baseline auf FAS-CANFD 1 = 0 (aktiv)
E3_1_1_UNECE auf FAS-CANFD 1 = 0 (";
CM_ SG_ 2549088443 KN_NR_01_ECUKnockOut "Ausgabe des ECUKnockout-Status";
CM_ SG_ 2549088443 KN_NR_01_ECUKnockOutTimer "Ausgabe des ECUKnockOut-Timer";
CM_ SG_ 2549088443 NM_NR_01_Wakeup "enthält die Weckursache; stehen mehrere Weckursachen parallel an, dann muss der kleinste Wert übertragen werden";
CM_ SG_ 2549088443 NR_01_Abschaltstufe "Funktionseinschraenkung aufgrund aktiver Abschaltstufe";
CM_ SG_ 2549088443 NR_01_KD_Fehler "Bei gesetztem Bit ist mindestens ein Kundendienstfehler eingetragen";
CM_ SG_ 2549088443 NR_01_KompSchutz "Signal wird gesetzt wenn Komponentenschutz (KS) im Steuergerät aktiv ist.";
CM_ SG_ 2549088443 NR_01_Nachlauftyp "Abgebildet wird die von der Hardware vorgegebene Möglichkeit, die Kommunikation nach Klemme 15 = AUS aufrecht zu erhalten. Es wird ein Init-Wert gesendet.";
CM_ SG_ 2549088443 NR_01_Transport_Mode "Funktionseinschraenkung aufgrund aktivem Transport Mode und/oder Transport Schutz";

CM_ SG_ 2549088444 KN_NR_02_BusKnockOut "Ausgabe des BusKnockout-Status";
CM_ SG_ 2549088444 KN_NR_02_BusKnockOutTimer "Ausgabe des BusKnockOut-Timer";
CM_ SG_ 2549088444 KN_NR_02_DiagPfad "Kennzeichnung der Diagnosefähigkeit des BusInterfaces eines Steuergerätes (Knoten)
Umfang LAH 80127

Bei Nutzung des Signal explizit pro angebundenem BusInterface zu setzen:
MQBw_Baseline auf FAS-CANFD 1 = 0 (aktiv)
E3_1_1_UNECE auf FAS-CANFD 1 = 0 (";
CM_ SG_ 2549088444 KN_NR_02_ECUKnockOut "Ausgabe des ECUKnockout-Status";
CM_ SG_ 2549088444 KN_NR_02_ECUKnockOutTimer "Ausgabe des ECUKnockOut-Timer";
CM_ SG_ 2549088444 NM_NR_02_Wakeup "enthält die Weckursache; stehen mehrere Weckursachen parallel an, dann muss der kleinste Wert übertragen werden";
CM_ SG_ 2549088444 NR_02_Abschaltstufe "Funktionseinschraenkung aufgrund aktiver Abschaltstufe";
CM_ SG_ 2549088444 NR_02_KD_Fehler "Bei gesetztem Bit ist mindestens ein Kundendienstfehler eingetragen";
CM_ SG_ 2549088444 NR_02_KompSchutz "Signal wird gesetzt wenn Komponentenschutz (KS) im Steuergerät aktiv ist.";
CM_ SG_ 2549088444 NR_02_Nachlauftyp "Abgebildet wird die von der Hardware vorgegebene Möglichkeit, die Kommunikation nach Klemme 15 = AUS aufrecht zu erhalten. Es wird ein Init-Wert gesendet.";
CM_ SG_ 2549088444 NR_02_Transport_Mode "Funktionseinschraenkung aufgrund aktivem Transport Mode und/oder Transport Schutz";

CM_ SG_ 2621440343 KS_ACC_Req_FD_Data "Komponentenschutz über ISO TP.";

CM_ SG_ 2621571415 KS_ACC_Resp_FD_Data "Komponentenschutz über ISO TP.";

CM_ SG_ 2621440335 KS_Kamera_Req_FD_Data "ISO-TP FD Datenkanal - FID2NA
Request Funktion 0x01 Komponentenschutz an Knoten 0x4F";

CM_ SG_ 2621571407 KS_Kamera_Resp_FD_Data "ISO-TP FD Datenkanal - FID2NA
Response Knoten 0x4F an Funktion 0x01 Komponentenschutz";

CM_ SG_ 2621440443 KS_NR_01_Req_FD_Data "ISO TP Komponentenschutz";

CM_ SG_ 2621571515 KS_NR_01_Resp_FD_Data "ISO TP Komponentenschutz";

CM_ SG_ 2621440444 KS_NR_02_Req_FD_Data "ISO TP Komponentenschutz";

CM_ SG_ 2621571516 KS_NR_02_Resp_FD_Data "ISO TP Komponentenschutz";

CM_ SG_ 919 aLDW_FoD_Status "Im CBEV wird aLDW durch FoD geschützt sein und so reicht für Kombi und HUd die PR/Zieldatencontainer basierte Codierung nicht mehr aus.

Aus diesem Grund brauch wir ein separates Signal, dass uns den Freischaltezustand mitteilt.";
CM_ SG_ 919 HC_Uss_Anforderung "Ansteuerung der vorderen PLA (VLS, VRS) und APS Sensoren (VL, VR)
0 = Ultraschallsensoren Aus
1 = Ultraschallsensoren An";
CM_ SG_ 919 LDW_DLC "distance to line, Abstand vom Fahrzeug zur Fahrbahnmarkierung
Der Wert gibt die Breite der Restspur zur Linie wieder (Abstand vom Fahrzeugäußerem zur Linie) (Wert POSITIV wenn Fahrzeug in der Spur - Wert NEGATIV wenn Fahrzeug über der Linie)";
CM_ SG_ 919 LDW_Frueh_Spaet "Im MMI eingestellter, aktiver Lenkeingriffszeitpunkt:
0: frueh, frueh aktiv
1: frueh, spaet aktiv
2: spaet, spaet aktiv
3: Fehler";
CM_ SG_ 919 LDW_Gong "Löst ein definiertes akustisches Signal aus.";
CM_ SG_ 919 LDW_Lernmodus_seitenabhaengig "Signal dient zur Ansteuerung von Funktionsanzeigen im Mitteldisplay des Kombiinstruments für die Seitenabhänige Liniendetektion (neue Funktion ab D4)";
CM_ SG_ 919 LDW_Seite_DLCTLC "Zuordnung auf welche Seite sich LDW_DLC bzw. LDW_TLC beziehen";
CM_ SG_ 919 LDW_Status_Anzeige "Signal dient zur Ansteuerung von Funktionsanzeigen im Mitteldisplay des Kombiinstruments.";
CM_ SG_ 919 LDW_Status_Grid "Im MEB-HUD angezeigtes Grid für die Anzeige im Lane- und Travel-Assist";
CM_ SG_ 919 LDW_Status_LED_gruen " ";
CM_ SG_ 919 LDW_Texte "Bei Anzeige eines Fehlertextes im Kombi ertönt ein akustisches Signal";
CM_ SG_ 919 LDW_TLC "time to line, Zeit bis das Fahrzeug die Fahrbahnmarkierung überquert";

CM_ SG_ 810 EPS_01_CRC "Für MLB:
'Berechnung siehe Lastenheft 'Kommunikationsabsicherung für FlexRay und CAN''

Ab MQB und MLBevo:
'Berechnung siehe Lastenheft 'End-to-End Kommunikationsabsicherung''

Endwerte siehe Begleitdokument 'S-PDU Kennungsfolgen'
";
CM_ SG_ 810 EPS_Akustiksignal "Ansteuerung eines Akustiksignals im Kombi";
CM_ SG_ 810 EPS_Anf_KL "Nach Überschreiten einer oberen Grenztemperatur innerhalb des Steuergerätes der Lenkhilfe fordert die EPS die Zuschaltung einer externen Kühlung durch den Kühlerlüfter an.
Es besteht kein technischer Zusammenhang mit einer Batterie_ab - Erkennung in der ";
CM_ SG_ 810 EPS_ARA_Status "Anforderung vom Anhängerrangierassistent. 
16 Statuswerte";
CM_ SG_ 810 EPS_Charisma_FahrPr "MLBevo: Aktuelles Fahrprogramm des Charisma-Teilnehmers (siehe Systemlastenheft Drive Select)
MQB: Istwert der Kennlinie (siehe Systemlastenheft MQB FPA)";
CM_ SG_ 810 EPS_Charisma_Status "Rückmeldung an den Charisma-Master

Wert 0x3 ist nur für Fahrzeuge ab MQB relevant";
CM_ SG_ 810 EPS_Endanschlag "Die EPS muss applikativ ein Lenkhubmapping umsetzen. Das Lenkhubmapping muss für jeden NR-Reglerstatus den Defaultendanschlag oder die Lenkhubaufweitung zuordnen.";
CM_ SG_ 810 EPS_Fehlerlampe "Steuert direkt die Fehlerlampe Lenkhilfe (gelb); kein Aufprüfen bei Neustart, keine Rückleseinformation in Kombi-Botschaft (nur für VW526 Hybrid)";
CM_ SG_ 810 EPS_Lenkerposition "Position des Lenkers im Fahrzeug";
CM_ SG_ 810 EPS_PLA_Abbruch "Art des Fehlers ohne Eintrag, 16 Werte möglich (siehe LH EPS/PLA)";
CM_ SG_ 810 EPS_PLA_Fehler "Art des Fehlers ohne Eintrag, 16 Werte möglich (siehe LH EPS/PLA)";
CM_ SG_ 810 EPS_PLA_Status "Zustand der Statusmaschine der EPS für die korrespondierenden Statusmaschine im PLA.";
CM_ SG_ 810 EPS_SpannungsAnf "Forderung des EPS-SG's zur Spannungsanhebung.";
CM_ SG_ 810 EPS_VZ_Zst_Offset_Geradeaus "Vorzeichen des Offset Geradeauslauf gem. Schnittstellenbeschreibung Lenkhilfe";
CM_ SG_ 810 EPS_Warnungen "Diese Bits werden verwendet, um im Kombi Texte, Lampen oder Bilder für die Lenkhilfe darzustellen
Audi MLB/RSe:
Text_1: Lenkung defekt (Prio 1)
Text_2: Lenkung Systemstörung (Prio 2)
VW526:
Text_1 (ID_TXT_1026.1): Ausfall Lenkunterstützung
Text_2 (I";
CM_ SG_ 810 EPS_Zst_Offset_Geradeaus "Lenkungsinterner Offset Geradeauslauf Nutzung gemaess Schnittstellendokumentation Lenkhilfe";
BA_DEF_REL_ BU_SG_REL_  "GenSigTimeoutTime" INT 0 65535;
BA_DEF_ BO_  "DiagRequest" ENUM "No", "Yes";
BA_DEF_ BO_  "DiagResponse" ENUM "No", "Yes";
BA_DEF_ BO_  "DiagState" ENUM "No", "Yes";
BA_DEF_ BO_  "GenMsgChkConstant" HEX 0 4095;
BA_DEF_ BO_  "GenMsgCycleTime" INT 0 65535;
BA_DEF_ BO_  "GenMsgCycleTimeFast" INT 0 65535;
BA_DEF_ BO_  "GenMsgDelayTime" INT 0 100000;
BA_DEF_ BO_  "GenMsgILSupport" ENUM "No", "Yes";
BA_DEF_ BO_  "GenMsgNrOfRepetition" INT 0 100;
BA_DEF_ BO_  "GenMsgPDUConstants" STRING;
BA_DEF_ BO_  "GenMsgSendType" ENUM "Cyclic", "not_used", "not_used", "not_used", "not_used", "not_used", "not_used", "IfActive", "NoMsgSendType";
BA_DEF_ BO_  "GenMsgStartDelayTime" INT 0 100000;
BA_DEF_ BO_  "NmMessage" ENUM "No", "Yes";
BA_DEF_ BO_  "NmhMessage" ENUM "No", "Yes";
BA_DEF_ BO_  "MsgType" ENUM "Application", "NM ", "NMH", "TP2.0", "ISO-TP ", "BAP", "EID", "KS", "XCP_PRE_CONFIGURED", "XCP_RUNTIME_CONFIGURED";
BA_DEF_ BO_  "VAGTP20_API" HEX 0 255;
BA_DEF_ BO_  "VAGTP20_DynConnection" ENUM "No", "Yes";
BA_DEF_ BO_  "VAGTP20_DynSetup" ENUM "No", "Yes";
BA_DEF_ BO_  "VAGTP20_StatConnection" ENUM "No", "Yes";
BA_DEF_ BO_  "CANFD_BRS" ENUM "0", "1";
BA_DEF_ BO_  "VFrameFormat" ENUM "StandardCAN", "ExtendedCAN", "reserved", "reserved", "reserved", "reserved", "reserved", "reserved", "reserved", "reserved", "reserved", "reserved", "reserved", "reserved", "StandardCAN_FD", "ExtendedCAN_FD";
BA_DEF_ SG_  "GenSigActiveRepetitions" INT -2147483648 2147483647;
BA_DEF_ SG_  "GenSigInactiveValue" INT -2147483648 2147483647;
BA_DEF_ SG_  "GenSigSendType" ENUM "Cyclic", "OnWrite", "OnWriteWithRepetition", "OnChange", "OnChangeWithRepetition", "IfActive", "IfActiveWithRepetition", "NoSigSendType", "OnChangeAndIfActive", "OnChangeAndIfActiveWithRepetition";
BA_DEF_ SG_  "GenSigStartValue" INT -2147483648 2147483647;
BA_DEF_ SG_  "NWM-WakeupAllowed" ENUM "No", "Yes";
BA_DEF_ SG_  "GenSigFuncType" ENUM "NoFunction", "MsgCounter", "CRC-8", "XOR", "XOR-2", "DatedBit", "SW-Kl15", "CHK", "Constant", "Protocol", "CRC-8-SAE_J1850", "CRC-32", "DataLength", "DataID", "MsgCounter16", "SOK-Signatur", "Cluster";
BA_DEF_ SG_  "GenSigSwitchedByIgnition" ENUM "No", "Yes";
BA_DEF_ SG_  "Fehlerwert" HEX 0 2147483647;
BA_DEF_ SG_  "GenSigMissingSourceValue" HEX 0 2147483647;
BA_DEF_DEF_REL_  "GenSigTimeoutTime" 0;
BA_DEF_DEF_  "DiagRequest" "No";
BA_DEF_DEF_  "DiagResponse" "No";
BA_DEF_DEF_  "DiagState" "No";
BA_DEF_DEF_  "GenMsgChkConstant" 0;
BA_DEF_DEF_  "GenMsgCycleTime" 0;
BA_DEF_DEF_  "GenMsgCycleTimeFast" 0;
BA_DEF_DEF_  "GenMsgDelayTime" 0;
BA_DEF_DEF_  "GenMsgILSupport" "No";
BA_DEF_DEF_  "GenMsgNrOfRepetition" 0;
BA_DEF_DEF_  "GenMsgPDUConstants" "";
BA_DEF_DEF_  "GenMsgSendType" "NoMsgSendType";
BA_DEF_DEF_  "GenMsgStartDelayTime" 0;
BA_DEF_DEF_  "NmMessage" "No";
BA_DEF_DEF_  "NmhMessage" "No";
BA_DEF_DEF_  "MsgType" "Application";
BA_DEF_DEF_  "VAGTP20_API" 0;
BA_DEF_DEF_  "VAGTP20_DynConnection" "No";
BA_DEF_DEF_  "VAGTP20_DynSetup" "No";
BA_DEF_DEF_  "VAGTP20_StatConnection" "No";
BA_DEF_DEF_  "CANFD_BRS" "1";
BA_DEF_DEF_  "VFrameFormat" "StandardCAN";
BA_DEF_DEF_  "GenSigActiveRepetitions" 0;
BA_DEF_DEF_  "GenSigInactiveValue" 0;
BA_DEF_DEF_  "GenSigSendType" "NoSigSendType";
BA_DEF_DEF_  "GenSigStartValue" 0;
BA_DEF_DEF_  "NWM-WakeupAllowed" "No";
BA_DEF_DEF_  "GenSigFuncType" "NoFunction";
BA_DEF_DEF_  "GenSigSwitchedByIgnition" "Yes";
BA_DEF_DEF_  "Fehlerwert" 0;
BA_DEF_DEF_  "GenSigMissingSourceValue" 0;
BA_ "GenMsgCycleTime" BO_ 588 50;
BA_ "GenMsgILSupport" BO_ 588 1;
BA_ "GenMsgSendType" BO_ 588 0;
BA_ "VFrameFormat" BO_ 588 14;
BA_ "GenMsgCycleTime" BO_ 589 50;
BA_ "GenMsgILSupport" BO_ 589 1;
BA_ "GenMsgSendType" BO_ 589 0;
BA_ "VFrameFormat" BO_ 589 14;
BA_ "GenMsgCycleTime" BO_ 2463978813 100;
BA_ "GenMsgDelayTime" BO_ 2463978813 10;
BA_ "GenMsgILSupport" BO_ 2463978813 1;
BA_ "GenMsgPDUConstants" BO_ 2463978813 "0x1d,0x82,0x7b,0x79,0xa5,0xee,0x3a,0xb9,0xb7,0xf9,0xe4,0x67,0x7f,0x97,0x11,0xad";
BA_ "GenMsgSendType" BO_ 2463978813 0;
BA_ "VFrameFormat" BO_ 2463978813 15;
BA_ "GenMsgCycleTime" BO_ 2463978891 100;
BA_ "GenMsgDelayTime" BO_ 2463978891 10;
BA_ "GenMsgILSupport" BO_ 2463978891 1;
BA_ "GenMsgSendType" BO_ 2463978891 0;
BA_ "VFrameFormat" BO_ 2463978891 15;
BA_ "GenMsgCycleTime" BO_ 1524 500;
BA_ "GenMsgDelayTime" BO_ 1524 50;
BA_ "GenMsgILSupport" BO_ 1524 1;
BA_ "GenMsgSendType" BO_ 1524 0;
BA_ "VFrameFormat" BO_ 1524 14;
BA_ "DiagRequest" BO_ 1879 1;
BA_ "MsgType" BO_ 1879 4;
BA_ "VFrameFormat" BO_ 1879 14;
BA_ "DiagResponse" BO_ 1985 1;
BA_ "MsgType" BO_ 1985 4;
BA_ "VFrameFormat" BO_ 1985 14;
BA_ "DiagState" BO_ 1792 1;
BA_ "MsgType" BO_ 1792 4;
BA_ "VFrameFormat" BO_ 1792 14;
BA_ "DiagRequest" BO_ 1871 1;
BA_ "MsgType" BO_ 1871 4;
BA_ "VFrameFormat" BO_ 1871 14;
BA_ "DiagResponse" BO_ 1977 1;
BA_ "MsgType" BO_ 1977 4;
BA_ "VFrameFormat" BO_ 1977 14;
BA_ "DiagRequest" BO_ 2621440087 1;
BA_ "MsgType" BO_ 2621440087 4;
BA_ "VFrameFormat" BO_ 2621440087 15;
BA_ "DiagResponse" BO_ 2621571159 1;
BA_ "MsgType" BO_ 2621571159 4;
BA_ "VFrameFormat" BO_ 2621571159 15;
BA_ "DiagState" BO_ 2621505536 1;
BA_ "MsgType" BO_ 2621505536 4;
BA_ "VFrameFormat" BO_ 2621505536 15;
BA_ "DiagRequest" BO_ 2621440079 1;
BA_ "MsgType" BO_ 2621440079 4;
BA_ "VFrameFormat" BO_ 2621440079 15;
BA_ "DiagResponse" BO_ 2621571151 1;
BA_ "MsgType" BO_ 2621571151 4;
BA_ "VFrameFormat" BO_ 2621571151 15;
BA_ "DiagRequest" BO_ 2549874875 1;
BA_ "MsgType" BO_ 2549874875 4;
BA_ "VFrameFormat" BO_ 2549874875 15;
BA_ "DiagRequest" BO_ 2621440187 1;
BA_ "MsgType" BO_ 2621440187 4;
BA_ "VFrameFormat" BO_ 2621440187 15;
BA_ "DiagResponse" BO_ 2550005947 1;
BA_ "MsgType" BO_ 2550005947 4;
BA_ "VFrameFormat" BO_ 2550005947 15;
BA_ "DiagResponse" BO_ 2621571259 1;
BA_ "MsgType" BO_ 2621571259 4;
BA_ "VFrameFormat" BO_ 2621571259 15;
BA_ "DiagRequest" BO_ 2549874876 1;
BA_ "MsgType" BO_ 2549874876 4;
BA_ "VFrameFormat" BO_ 2549874876 15;
BA_ "DiagRequest" BO_ 2621440188 1;
BA_ "MsgType" BO_ 2621440188 4;
BA_ "VFrameFormat" BO_ 2621440188 15;
BA_ "DiagResponse" BO_ 2550005948 1;
BA_ "MsgType" BO_ 2550005948 4;
BA_ "VFrameFormat" BO_ 2550005948 15;
BA_ "DiagResponse" BO_ 2621571260 1;
BA_ "MsgType" BO_ 2621571260 4;
BA_ "VFrameFormat" BO_ 2621571260 15;
BA_ "GenMsgCycleTime" BO_ 2527679667 1000;
BA_ "GenMsgDelayTime" BO_ 2527679667 50;
BA_ "GenMsgILSupport" BO_ 2527679667 1;
BA_ "GenMsgSendType" BO_ 2527679667 0;
BA_ "VFrameFormat" BO_ 2527679667 15;
BA_ "GenMsgCycleTime" BO_ 2527679684 2000;
BA_ "GenMsgDelayTime" BO_ 2527679684 100;
BA_ "GenMsgILSupport" BO_ 2527679684 1;
BA_ "GenMsgSendType" BO_ 2527679684 0;
BA_ "VFrameFormat" BO_ 2527679684 15;
BA_ "GenMsgCycleTime" BO_ 2589283730 1000;
BA_ "GenMsgILSupport" BO_ 2589283730 1;
BA_ "GenMsgSendType" BO_ 2589283730 0;
BA_ "VFrameFormat" BO_ 2589283730 15;
BA_ "GenMsgCycleTime" BO_ 792 80;
BA_ "GenMsgILSupport" BO_ 792 1;
BA_ "GenMsgSendType" BO_ 792 0;
BA_ "VFrameFormat" BO_ 792 14;
BA_ "GenMsgChkConstant" BO_ 960 195;
BA_ "GenMsgCycleTime" BO_ 960 100;
BA_ "GenMsgDelayTime" BO_ 960 10;
BA_ "GenMsgILSupport" BO_ 960 1;
BA_ "GenMsgPDUConstants" BO_ 960 "0xc3,0xc3,0xc3,0xc3,0xc3,0xc3,0xc3,0xc3,0xc3,0xc3,0xc3,0xc3,0xc3,0xc3,0xc3,0xc3";
BA_ "GenMsgSendType" BO_ 960 0;
BA_ "VFrameFormat" BO_ 960 14;
BA_ "GenMsgCycleTime" BO_ 2463978753 1000;
BA_ "GenMsgCycleTimeFast" BO_ 2463978753 100;
BA_ "GenMsgDelayTime" BO_ 2463978753 10;
BA_ "GenMsgILSupport" BO_ 2463978753 1;
BA_ "GenMsgNrOfRepetition" BO_ 2463978753 5;
BA_ "GenMsgPDUConstants" BO_ 2463978753 "0x80,0xf1,0xa5,0xaf,0x94,0x59,0xe8,0x8c,0x03,0xd4,0xf5,0x5e,0xec,0x73,0x81,0x50";
BA_ "GenMsgSendType" BO_ 2463978753 0;
BA_ "VFrameFormat" BO_ 2463978753 15;
BA_ "GenMsgCycleTime" BO_ 1640 200;
BA_ "GenMsgCycleTimeFast" BO_ 1640 100;
BA_ "GenMsgDelayTime" BO_ 1640 50;
BA_ "GenMsgILSupport" BO_ 1640 1;
BA_ "GenMsgNrOfRepetition" BO_ 1640 5;
BA_ "GenMsgSendType" BO_ 1640 0;
BA_ "VFrameFormat" BO_ 1640 14;
BA_ "GenMsgCycleTime" BO_ 1505 200;
BA_ "GenMsgILSupport" BO_ 1505 1;
BA_ "GenMsgSendType" BO_ 1505 0;
BA_ "VFrameFormat" BO_ 1505 14;
BA_ "GenMsgCycleTime" BO_ 605 60;
BA_ "GenMsgILSupport" BO_ 605 1;
BA_ "GenMsgPDUConstants" BO_ 605 "0xda,0x6b,0x0e,0xb2,0x78,0xbd,0x5a,0x81,0x7b,0xd6,0x41,0x39,0x76,0xb6,0xd7,0x35";
BA_ "GenMsgSendType" BO_ 605 0;
BA_ "VFrameFormat" BO_ 605 14;
BA_ "GenMsgCycleTime" BO_ 2549088343 500;
BA_ "GenMsgILSupport" BO_ 2549088343 1;
BA_ "GenMsgSendType" BO_ 2549088343 0;
BA_ "VFrameFormat" BO_ 2549088343 15;
BA_ "GenMsgCycleTime" BO_ 2549088272 500;
BA_ "GenMsgILSupport" BO_ 2549088272 1;
BA_ "GenMsgSendType" BO_ 2549088272 0;
BA_ "VFrameFormat" BO_ 2549088272 15;
BA_ "GenMsgCycleTime" BO_ 2549088335 500;
BA_ "GenMsgILSupport" BO_ 2549088335 1;
BA_ "GenMsgSendType" BO_ 2549088335 0;
BA_ "VFrameFormat" BO_ 2549088335 15;
BA_ "GenMsgCycleTime" BO_ 2549088313 500;
BA_ "GenMsgILSupport" BO_ 2549088313 1;
BA_ "GenMsgSendType" BO_ 2549088313 0;
BA_ "VFrameFormat" BO_ 2549088313 15;
BA_ "GenMsgCycleTime" BO_ 2549088443 500;
BA_ "GenMsgILSupport" BO_ 2549088443 1;
BA_ "GenMsgSendType" BO_ 2549088443 0;
BA_ "VFrameFormat" BO_ 2549088443 15;
BA_ "GenMsgCycleTime" BO_ 2549088444 500;
BA_ "GenMsgILSupport" BO_ 2549088444 1;
BA_ "GenMsgSendType" BO_ 2549088444 0;
BA_ "VFrameFormat" BO_ 2549088444 15;
BA_ "MsgType" BO_ 2621440343 4;
BA_ "VFrameFormat" BO_ 2621440343 15;
BA_ "MsgType" BO_ 2621571415 4;
BA_ "VFrameFormat" BO_ 2621571415 15;
BA_ "MsgType" BO_ 2621440335 4;
BA_ "VFrameFormat" BO_ 2621440335 15;
BA_ "MsgType" BO_ 2621571407 4;
BA_ "VFrameFormat" BO_ 2621571407 15;
BA_ "MsgType" BO_ 2621440443 4;
BA_ "VFrameFormat" BO_ 2621440443 15;
BA_ "MsgType" BO_ 2621571515 4;
BA_ "VFrameFormat" BO_ 2621571515 15;
BA_ "MsgType" BO_ 2621440444 4;
BA_ "VFrameFormat" BO_ 2621440444 15;
BA_ "MsgType" BO_ 2621571516 4;
BA_ "VFrameFormat" BO_ 2621571516 15;
BA_ "GenMsgCycleTime" BO_ 919 100;
BA_ "GenMsgDelayTime" BO_ 919 20;
BA_ "GenMsgILSupport" BO_ 919 1;
BA_ "GenMsgSendType" BO_ 919 0;
BA_ "VFrameFormat" BO_ 919 14;
BA_ "GenMsgChkConstant" BO_ 810 41;
BA_ "GenMsgCycleTime" BO_ 810 50;
BA_ "GenMsgILSupport" BO_ 810 1;
BA_ "GenMsgPDUConstants" BO_ 810 "0x29,0x29,0x29,0x29,0x29,0x29,0x29,0x29,0x29,0x29,0x29,0x29,0x29,0x29,0x29,0x29";
BA_ "GenMsgSendType" BO_ 810 0;
BA_ "VFrameFormat" BO_ 810 14;
BA_ "GenSigSendType" SG_ 588 ASW_Akustik_Einstellung 0;
BA_ "GenSigSendType" SG_ 588 ASW_Ausgabemodus_BFS 0;
BA_ "GenSigSwitchedByIgnition" SG_ 588 ASW_Ausgabemodus_BFS 0;
BA_ "GenSigSendType" SG_ 588 ASW_Ausgabemodus_FS 0;
BA_ "GenSigSwitchedByIgnition" SG_ 588 ASW_Ausgabemodus_FS 0;
BA_ "GenSigSendType" SG_ 588 ASW_Ausgabemodus_HBFS 0;
BA_ "GenSigSwitchedByIgnition" SG_ 588 ASW_Ausgabemodus_HBFS 0;
BA_ "GenSigSendType" SG_ 588 ASW_Ausgabemodus_HFS 0;
BA_ "GenSigSwitchedByIgnition" SG_ 588 ASW_Ausgabemodus_HFS 0;
BA_ "GenSigSendType" SG_ 588 ASW_Kombiausgabe 0;
BA_ "GenSigSendType" SG_ 588 ASW_Kombitexte 0;
BA_ "GenSigSwitchedByIgnition" SG_ 588 ASW_Kombitexte 0;
BA_ "GenSigSendType" SG_ 588 ASW_Modus 0;
BA_ "GenSigStartValue" SG_ 588 ASW_Modus 4;
BA_ "GenSigSendType" SG_ 588 ASW_Status 0;
BA_ "GenSigSwitchedByIgnition" SG_ 588 ASW_Status 0;
BA_ "Fehlerwert" SG_ 588 ASW_Status 2;
BA_ "GenSigSendType" SG_ 588 ASW_Ton_Richtung_HL 0;
BA_ "GenSigSwitchedByIgnition" SG_ 588 ASW_Ton_Richtung_HL 0;
BA_ "GenSigSendType" SG_ 588 ASW_Ton_Richtung_HR 0;
BA_ "GenSigSwitchedByIgnition" SG_ 588 ASW_Ton_Richtung_HR 0;
BA_ "GenSigSendType" SG_ 588 ASW_Ton_Richtung_VL 0;
BA_ "GenSigSwitchedByIgnition" SG_ 588 ASW_Ton_Richtung_VL 0;
BA_ "GenSigSendType" SG_ 588 ASW_Ton_Richtung_VR 0;
BA_ "GenSigSwitchedByIgnition" SG_ 588 ASW_Ton_Richtung_VR 0;
BA_ "GenSigSendType" SG_ 588 ASW_Warnung_BFS 0;
BA_ "GenSigSwitchedByIgnition" SG_ 588 ASW_Warnung_BFS 0;
BA_ "GenSigSendType" SG_ 588 ASW_Warnung_FS 0;
BA_ "GenSigSwitchedByIgnition" SG_ 588 ASW_Warnung_FS 0;
BA_ "GenSigSendType" SG_ 588 Heckradar_Kombitexte 0;
BA_ "GenSigSwitchedByIgnition" SG_ 588 Heckradar_Kombitexte 0;
BA_ "GenSigSendType" SG_ 588 HRE_Anzeigetexte 0;
BA_ "GenSigSwitchedByIgnition" SG_ 588 HRE_Anzeigetexte 0;
BA_ "GenSigSendType" SG_ 588 RCTA_Kombitexte 0;
BA_ "GenSigSwitchedByIgnition" SG_ 588 RCTA_Kombitexte 0;
BA_ "GenSigSendType" SG_ 588 SWA_Anzeigen 0;
BA_ "GenSigSwitchedByIgnition" SG_ 588 SWA_Anzeigen 0;
BA_ "GenSigSendType" SG_ 588 SWA_Blindheit_erkannt 0;
BA_ "GenSigSendType" SG_ 588 SWA_Blindheitsverdacht 0;
BA_ "GenSigSwitchedByIgnition" SG_ 588 SWA_Blindheitsverdacht 0;
BA_ "GenSigSendType" SG_ 588 SWA_Brightness_Mode_FPM 0;
BA_ "GenSigSwitchedByIgnition" SG_ 588 SWA_Brightness_Mode_FPM 0;
BA_ "Fehlerwert" SG_ 588 SWA_Brightness_Mode_FPM 15;
BA_ "GenSigSendType" SG_ 588 SWA_FT_RueckLED 0;
BA_ "GenSigSwitchedByIgnition" SG_ 588 SWA_FT_RueckLED 0;
BA_ "GenSigSendType" SG_ 588 SWA_Gischtzaehler 0;
BA_ "GenSigSendType" SG_ 588 SWA_Infostufe_Assist_li 0;
BA_ "GenSigSendType" SG_ 588 SWA_Infostufe_Assist_re 0;
BA_ "GenSigSendType" SG_ 588 SWA_Kombiausgabe 0;
BA_ "GenSigSendType" SG_ 588 SWA_LED_Ausgabemodus_BFS 0;
BA_ "GenSigSendType" SG_ 588 SWA_LED_Ausgabemodus_FS 0;
BA_ "GenSigSendType" SG_ 588 SWA_LED_Hell_BFS 0;
BA_ "GenSigStartValue" SG_ 588 SWA_LED_Hell_BFS 126;
BA_ "Fehlerwert" SG_ 588 SWA_LED_Hell_BFS 127;
BA_ "GenSigSendType" SG_ 588 SWA_LED_Hell_FS 0;
BA_ "GenSigStartValue" SG_ 588 SWA_LED_Hell_FS 126;
BA_ "Fehlerwert" SG_ 588 SWA_LED_Hell_FS 127;
BA_ "GenSigSendType" SG_ 588 SWA_Modus 0;
BA_ "GenSigSendType" SG_ 588 SWA_Modus_System 0;
BA_ "GenSigSendType" SG_ 588 SWA_rel_Fehler 0;
BA_ "Fehlerwert" SG_ 588 SWA_rel_Fehler 1;
BA_ "GenSigSendType" SG_ 588 SWA_rel_Nichtverf 0;
BA_ "GenSigSendType" SG_ 588 SWA_Sta_aktiv 0;
BA_ "GenSigSendType" SG_ 588 SWA_Sta_passiv 0;
BA_ "GenSigSendType" SG_ 588 SWA_Standziele_li 0;
BA_ "GenSigSendType" SG_ 588 SWA_Standziele_re 0;
BA_ "GenSigSendType" SG_ 588 SWA_Status 0;
BA_ "Fehlerwert" SG_ 588 SWA_Status 3;
BA_ "GenSigSendType" SG_ 588 SWA_Status_KuFu 0;
BA_ "Fehlerwert" SG_ 588 SWA_Status_KuFu 3;
BA_ "GenSigSendType" SG_ 588 SWA_Status_System 0;
BA_ "Fehlerwert" SG_ 588 SWA_Status_System 3;
BA_ "GenSigSendType" SG_ 588 SWA_Warnstufe_Assist_li 0;
BA_ "GenSigSendType" SG_ 588 SWA_Warnstufe_Assist_re 0;
BA_ "GenSigSendType" SG_ 589 SWA_Infostufe_SWA_li 0;
BA_ "GenSigSendType" SG_ 589 SWA_Infostufe_SWA_re 0;
BA_ "GenSigSendType" SG_ 589 SWA_Kolonne_li 0;
BA_ "GenSigSendType" SG_ 589 SWA_Kolonne_mi 0;
BA_ "GenSigSendType" SG_ 589 SWA_Kolonne_re 0;
BA_ "GenSigSendType" SG_ 589 SWA_Obj_01_Breite 0;
BA_ "GenSigStartValue" SG_ 589 SWA_Obj_01_Breite 127;
BA_ "GenSigSendType" SG_ 589 SWA_Obj_01_Existenzwahrsch 0;
BA_ "GenSigStartValue" SG_ 589 SWA_Obj_01_Existenzwahrsch 127;
BA_ "GenSigSendType" SG_ 589 SWA_Obj_01_Gemessen 0;
BA_ "GenSigSendType" SG_ 589 SWA_Obj_01_GeschwRelX 0;
BA_ "GenSigStartValue" SG_ 589 SWA_Obj_01_GeschwRelX 511;
BA_ "GenSigSendType" SG_ 589 SWA_Obj_01_GeschwRelY 0;
BA_ "GenSigStartValue" SG_ 589 SWA_Obj_01_GeschwRelY 511;
BA_ "GenSigSendType" SG_ 589 SWA_Obj_01_ID 0;
BA_ "GenSigStartValue" SG_ 589 SWA_Obj_01_ID 31;
BA_ "GenSigSwitchedByIgnition" SG_ 589 SWA_Obj_01_ID 0;
BA_ "GenSigSendType" SG_ 589 SWA_Obj_01_Laenge 0;
BA_ "GenSigStartValue" SG_ 589 SWA_Obj_01_Laenge 127;
BA_ "GenSigSendType" SG_ 589 SWA_Obj_01_Objektklasse 0;
BA_ "GenSigStartValue" SG_ 589 SWA_Obj_01_Objektklasse 15;
BA_ "GenSigSendType" SG_ 589 SWA_Obj_01_PositionX 0;
BA_ "GenSigStartValue" SG_ 589 SWA_Obj_01_PositionX 511;
BA_ "GenSigSendType" SG_ 589 SWA_Obj_01_PositionY 0;
BA_ "GenSigStartValue" SG_ 589 SWA_Obj_01_PositionY 255;
BA_ "GenSigSendType" SG_ 589 SWA_Obj_01_ReferenzPkt 0;
BA_ "GenSigStartValue" SG_ 589 SWA_Obj_01_ReferenzPkt 15;
BA_ "GenSigSendType" SG_ 589 SWA_Obj_02_Breite 0;
BA_ "GenSigStartValue" SG_ 589 SWA_Obj_02_Breite 127;
BA_ "GenSigSendType" SG_ 589 SWA_Obj_02_Existenzwahrsch 0;
BA_ "GenSigStartValue" SG_ 589 SWA_Obj_02_Existenzwahrsch 127;
BA_ "GenSigSendType" SG_ 589 SWA_Obj_02_Gemessen 0;
BA_ "GenSigSendType" SG_ 589 SWA_Obj_02_GeschwRelX 0;
BA_ "GenSigStartValue" SG_ 589 SWA_Obj_02_GeschwRelX 511;
BA_ "GenSigSendType" SG_ 589 SWA_Obj_02_GeschwRelY 0;
BA_ "GenSigStartValue" SG_ 589 SWA_Obj_02_GeschwRelY 511;
BA_ "GenSigSendType" SG_ 589 SWA_Obj_02_ID 0;
BA_ "GenSigStartValue" SG_ 589 SWA_Obj_02_ID 31;
BA_ "GenSigSwitchedByIgnition" SG_ 589 SWA_Obj_02_ID 0;
BA_ "GenSigSendType" SG_ 589 SWA_Obj_02_Laenge 0;
BA_ "GenSigStartValue" SG_ 589 SWA_Obj_02_Laenge 127;
BA_ "GenSigSendType" SG_ 589 SWA_Obj_02_Objektklasse 0;
BA_ "GenSigStartValue" SG_ 589 SWA_Obj_02_Objektklasse 15;
BA_ "GenSigSendType" SG_ 589 SWA_Obj_02_PositionX 0;
BA_ "GenSigStartValue" SG_ 589 SWA_Obj_02_PositionX 511;
BA_ "GenSigSendType" SG_ 589 SWA_Obj_02_PositionY 0;
BA_ "GenSigStartValue" SG_ 589 SWA_Obj_02_PositionY 255;
BA_ "GenSigSendType" SG_ 589 SWA_Obj_02_ReferenzPkt 0;
BA_ "GenSigStartValue" SG_ 589 SWA_Obj_02_ReferenzPkt 15;
BA_ "GenSigSendType" SG_ 589 SWA_Obj_03_Breite 0;
BA_ "GenSigStartValue" SG_ 589 SWA_Obj_03_Breite 127;
BA_ "GenSigSendType" SG_ 589 SWA_Obj_03_Existenzwahrsch 0;
BA_ "GenSigStartValue" SG_ 589 SWA_Obj_03_Existenzwahrsch 127;
BA_ "GenSigSendType" SG_ 589 SWA_Obj_03_Gemessen 0;
BA_ "GenSigSendType" SG_ 589 SWA_Obj_03_GeschwRelX 0;
BA_ "GenSigStartValue" SG_ 589 SWA_Obj_03_GeschwRelX 511;
BA_ "GenSigSendType" SG_ 589 SWA_Obj_03_GeschwRelY 0;
BA_ "GenSigStartValue" SG_ 589 SWA_Obj_03_GeschwRelY 511;
BA_ "GenSigSendType" SG_ 589 SWA_Obj_03_ID 0;
BA_ "GenSigStartValue" SG_ 589 SWA_Obj_03_ID 31;
BA_ "GenSigSwitchedByIgnition" SG_ 589 SWA_Obj_03_ID 0;
BA_ "GenSigSendType" SG_ 589 SWA_Obj_03_Laenge 0;
BA_ "GenSigStartValue" SG_ 589 SWA_Obj_03_Laenge 127;
BA_ "GenSigSendType" SG_ 589 SWA_Obj_03_Objektklasse 0;
BA_ "GenSigStartValue" SG_ 589 SWA_Obj_03_Objektklasse 15;
BA_ "GenSigSendType" SG_ 589 SWA_Obj_03_PositionX 0;
BA_ "GenSigStartValue" SG_ 589 SWA_Obj_03_PositionX 511;
BA_ "GenSigSendType" SG_ 589 SWA_Obj_03_PositionY 0;
BA_ "GenSigStartValue" SG_ 589 SWA_Obj_03_PositionY 255;
BA_ "GenSigSendType" SG_ 589 SWA_Obj_03_ReferenzPkt 0;
BA_ "GenSigStartValue" SG_ 589 SWA_Obj_03_ReferenzPkt 15;
BA_ "GenSigSendType" SG_ 589 SWA_Obj_04_Breite 0;
BA_ "GenSigStartValue" SG_ 589 SWA_Obj_04_Breite 127;
BA_ "GenSigSendType" SG_ 589 SWA_Obj_04_Existenzwahrsch 0;
BA_ "GenSigStartValue" SG_ 589 SWA_Obj_04_Existenzwahrsch 127;
BA_ "GenSigSendType" SG_ 589 SWA_Obj_04_Gemessen 0;
BA_ "GenSigSendType" SG_ 589 SWA_Obj_04_GeschwRelX 0;
BA_ "GenSigStartValue" SG_ 589 SWA_Obj_04_GeschwRelX 511;
BA_ "GenSigSendType" SG_ 589 SWA_Obj_04_GeschwRelY 0;
BA_ "GenSigStartValue" SG_ 589 SWA_Obj_04_GeschwRelY 511;
BA_ "GenSigSendType" SG_ 589 SWA_Obj_04_ID 0;
BA_ "GenSigStartValue" SG_ 589 SWA_Obj_04_ID 31;
BA_ "GenSigSwitchedByIgnition" SG_ 589 SWA_Obj_04_ID 0;
BA_ "GenSigSendType" SG_ 589 SWA_Obj_04_Laenge 0;
BA_ "GenSigStartValue" SG_ 589 SWA_Obj_04_Laenge 127;
BA_ "GenSigSendType" SG_ 589 SWA_Obj_04_Objektklasse 0;
BA_ "GenSigStartValue" SG_ 589 SWA_Obj_04_Objektklasse 15;
BA_ "GenSigSendType" SG_ 589 SWA_Obj_04_PositionX 0;
BA_ "GenSigStartValue" SG_ 589 SWA_Obj_04_PositionX 511;
BA_ "GenSigSendType" SG_ 589 SWA_Obj_04_PositionY 0;
BA_ "GenSigStartValue" SG_ 589 SWA_Obj_04_PositionY 255;
BA_ "GenSigSendType" SG_ 589 SWA_Obj_04_ReferenzPkt 0;
BA_ "GenSigStartValue" SG_ 589 SWA_Obj_04_ReferenzPkt 15;
BA_ "GenSigSendType" SG_ 589 SWA_Obj_05_Breite 0;
BA_ "GenSigStartValue" SG_ 589 SWA_Obj_05_Breite 127;
BA_ "GenSigSendType" SG_ 589 SWA_Obj_05_Existenzwahrsch 0;
BA_ "GenSigStartValue" SG_ 589 SWA_Obj_05_Existenzwahrsch 127;
BA_ "GenSigSendType" SG_ 589 SWA_Obj_05_Gemessen 0;
BA_ "GenSigSendType" SG_ 589 SWA_Obj_05_GeschwRelX 0;
BA_ "GenSigStartValue" SG_ 589 SWA_Obj_05_GeschwRelX 511;
BA_ "GenSigSendType" SG_ 589 SWA_Obj_05_GeschwRelY 0;
BA_ "GenSigStartValue" SG_ 589 SWA_Obj_05_GeschwRelY 511;
BA_ "GenSigSendType" SG_ 589 SWA_Obj_05_ID 0;
BA_ "GenSigStartValue" SG_ 589 SWA_Obj_05_ID 31;
BA_ "GenSigSwitchedByIgnition" SG_ 589 SWA_Obj_05_ID 0;
BA_ "GenSigSendType" SG_ 589 SWA_Obj_05_Laenge 0;
BA_ "GenSigStartValue" SG_ 589 SWA_Obj_05_Laenge 127;
BA_ "GenSigSendType" SG_ 589 SWA_Obj_05_Objektklasse 0;
BA_ "GenSigStartValue" SG_ 589 SWA_Obj_05_Objektklasse 15;
BA_ "GenSigSendType" SG_ 589 SWA_Obj_05_PositionX 0;
BA_ "GenSigStartValue" SG_ 589 SWA_Obj_05_PositionX 511;
BA_ "GenSigSendType" SG_ 589 SWA_Obj_05_PositionY 0;
BA_ "GenSigStartValue" SG_ 589 SWA_Obj_05_PositionY 255;
BA_ "GenSigSendType" SG_ 589 SWA_Obj_05_ReferenzPkt 0;
BA_ "GenSigStartValue" SG_ 589 SWA_Obj_05_ReferenzPkt 15;
BA_ "GenSigSendType" SG_ 589 SWA_Obj_06_Breite 0;
BA_ "GenSigStartValue" SG_ 589 SWA_Obj_06_Breite 127;
BA_ "GenSigSendType" SG_ 589 SWA_Obj_06_Existenzwahrsch 0;
BA_ "GenSigStartValue" SG_ 589 SWA_Obj_06_Existenzwahrsch 127;
BA_ "GenSigSendType" SG_ 589 SWA_Obj_06_Gemessen 0;
BA_ "GenSigSendType" SG_ 589 SWA_Obj_06_GeschwRelX 0;
BA_ "GenSigStartValue" SG_ 589 SWA_Obj_06_GeschwRelX 511;
BA_ "GenSigSendType" SG_ 589 SWA_Obj_06_GeschwRelY 0;
BA_ "GenSigStartValue" SG_ 589 SWA_Obj_06_GeschwRelY 511;
BA_ "GenSigSendType" SG_ 589 SWA_Obj_06_ID 0;
BA_ "GenSigStartValue" SG_ 589 SWA_Obj_06_ID 31;
BA_ "GenSigSwitchedByIgnition" SG_ 589 SWA_Obj_06_ID 0;
BA_ "GenSigSendType" SG_ 589 SWA_Obj_06_Laenge 0;
BA_ "GenSigStartValue" SG_ 589 SWA_Obj_06_Laenge 127;
BA_ "GenSigSendType" SG_ 589 SWA_Obj_06_Objektklasse 0;
BA_ "GenSigStartValue" SG_ 589 SWA_Obj_06_Objektklasse 15;
BA_ "GenSigSendType" SG_ 589 SWA_Obj_06_PositionX 0;
BA_ "GenSigStartValue" SG_ 589 SWA_Obj_06_PositionX 511;
BA_ "GenSigSendType" SG_ 589 SWA_Obj_06_PositionY 0;
BA_ "GenSigStartValue" SG_ 589 SWA_Obj_06_PositionY 255;
BA_ "GenSigSendType" SG_ 589 SWA_Obj_06_ReferenzPkt 0;
BA_ "GenSigStartValue" SG_ 589 SWA_Obj_06_ReferenzPkt 15;
BA_ "GenSigSendType" SG_ 589 SWA_Obj_Kurvenradius 0;
BA_ "GenSigStartValue" SG_ 589 SWA_Obj_Kurvenradius 65535;
BA_ "GenSigSendType" SG_ 589 SWA_StrukturLinks_querAbstand 0;
BA_ "GenSigStartValue" SG_ 589 SWA_StrukturLinks_querAbstand 511;
BA_ "GenSigSendType" SG_ 589 SWA_StrukturLinks_Typ 0;
BA_ "GenSigSendType" SG_ 589 SWA_StrukturRechts_querAbstand 0;
BA_ "GenSigStartValue" SG_ 589 SWA_StrukturRechts_querAbstand 511;
BA_ "GenSigSendType" SG_ 589 SWA_StrukturRechts_Typ 0;
BA_ "GenSigSendType" SG_ 589 SWA_Umfeld_Zeitstempel 0;
BA_ "GenSigStartValue" SG_ 589 SWA_Umfeld_Zeitstempel 65535;
BA_ "GenSigSendType" SG_ 589 SWA_Umfeld_Zeitstempel_Status 0;
BA_ "GenSigStartValue" SG_ 589 SWA_Umfeld_Zeitstempel_Status 7;
BA_ "GenSigSendType" SG_ 589 SWA_Warnung_SWA_li 0;
BA_ "GenSigSendType" SG_ 589 SWA_Warnung_SWA_re 0;
BA_ "GenSigSendType" SG_ 2463978813 HVL_01_BZ 0;
BA_ "GenSigFuncType" SG_ 2463978813 HVL_01_BZ 1;
BA_ "GenSigSwitchedByIgnition" SG_ 2463978813 HVL_01_BZ 0;
BA_ "GenSigSendType" SG_ 2463978813 HVL_01_CRC 0;
BA_ "GenSigFuncType" SG_ 2463978813 HVL_01_CRC 2;
BA_ "GenSigSwitchedByIgnition" SG_ 2463978813 HVL_01_CRC 0;
BA_ "GenSigSendType" SG_ 2463978813 HVL_HVK_Fehler_DCAbschaltung 0;
BA_ "GenSigSwitchedByIgnition" SG_ 2463978813 HVL_HVK_Fehler_DCAbschaltung 0;
BA_ "GenSigSendType" SG_ 2463978813 HVL_Kuehltemperatur 0;
BA_ "GenSigStartValue" SG_ 2463978813 HVL_Kuehltemperatur 254;
BA_ "GenSigSwitchedByIgnition" SG_ 2463978813 HVL_Kuehltemperatur 0;
BA_ "Fehlerwert" SG_ 2463978813 HVL_Kuehltemperatur 255;
BA_ "GenSigSendType" SG_ 2463978813 HVL_LadeAnforderung 3;
BA_ "GenSigSwitchedByIgnition" SG_ 2463978813 HVL_LadeAnforderung 0;
BA_ "GenSigSendType" SG_ 2463978813 HVL_OCC_IstModus 0;
BA_ "GenSigStartValue" SG_ 2463978813 HVL_OCC_IstModus 6;
BA_ "GenSigSwitchedByIgnition" SG_ 2463978813 HVL_OCC_IstModus 0;
BA_ "Fehlerwert" SG_ 2463978813 HVL_OCC_IstModus 7;
BA_ "GenSigSendType" SG_ 2463978813 HVL_Status_EoHVL 0;
BA_ "GenSigSwitchedByIgnition" SG_ 2463978813 HVL_Status_EoHVL 0;
BA_ "Fehlerwert" SG_ 2463978813 HVL_Status_EoHVL 3;
BA_ "GenSigSendType" SG_ 2463978813 HVL_Status_Spgfreiheit 0;
BA_ "GenSigSwitchedByIgnition" SG_ 2463978813 HVL_Status_Spgfreiheit 0;
BA_ "Fehlerwert" SG_ 2463978813 HVL_Status_Spgfreiheit 3;
BA_ "GenSigSendType" SG_ 2463978813 HVL_Steckerstatus 0;
BA_ "GenSigSwitchedByIgnition" SG_ 2463978813 HVL_Steckerstatus 0;
BA_ "Fehlerwert" SG_ 2463978813 HVL_Steckerstatus 3;
BA_ "GenSigSendType" SG_ 2463978891 CabinCare_Enable 3;
BA_ "GenSigSwitchedByIgnition" SG_ 2463978891 CabinCare_Enable 0;
BA_ "GenSigSendType" SG_ 2463978891 ICV_Switch_AspectRatio 3;
BA_ "GenSigSwitchedByIgnition" SG_ 2463978891 ICV_Switch_AspectRatio 0;
BA_ "GenSigSendType" SG_ 2463978891 ICV_Switch_Brightness 3;
BA_ "GenSigStartValue" SG_ 2463978891 ICV_Switch_Brightness 50;
BA_ "GenSigSwitchedByIgnition" SG_ 2463978891 ICV_Switch_Brightness 0;
BA_ "GenSigSendType" SG_ 2463978891 ICV_Switch_ColorMode 3;
BA_ "GenSigSwitchedByIgnition" SG_ 2463978891 ICV_Switch_ColorMode 0;
BA_ "GenSigSendType" SG_ 2463978891 ICV_Switch_Contrast 3;
BA_ "GenSigSwitchedByIgnition" SG_ 2463978891 ICV_Switch_Contrast 0;
BA_ "GenSigSendType" SG_ 2463978891 ICV_Switch_FieldOfView 3;
BA_ "GenSigSwitchedByIgnition" SG_ 2463978891 ICV_Switch_FieldOfView 0;
BA_ "GenSigSendType" SG_ 2463978891 ICV_Switch_FrameRate 3;
BA_ "GenSigStartValue" SG_ 2463978891 ICV_Switch_FrameRate 30;
BA_ "GenSigSwitchedByIgnition" SG_ 2463978891 ICV_Switch_FrameRate 0;
BA_ "GenSigSendType" SG_ 2463978891 ICV_Switch_FunctionState 3;
BA_ "GenSigSwitchedByIgnition" SG_ 2463978891 ICV_Switch_FunctionState 0;
BA_ "GenSigSendType" SG_ 2463978891 ICV_Switch_HDR 3;
BA_ "GenSigSwitchedByIgnition" SG_ 2463978891 ICV_Switch_HDR 0;
BA_ "GenSigSendType" SG_ 2463978891 ICV_Switch_Resolution 3;
BA_ "GenSigStartValue" SG_ 2463978891 ICV_Switch_Resolution 4;
BA_ "GenSigSwitchedByIgnition" SG_ 2463978891 ICV_Switch_Resolution 0;
BA_ "GenSigSendType" SG_ 2463978891 ICV_Switch_VideoLength 3;
BA_ "GenSigSwitchedByIgnition" SG_ 2463978891 ICV_Switch_VideoLength 0;
BA_ "GenSigSendType" SG_ 2463978891 PetsMode_Enable 3;
BA_ "GenSigSwitchedByIgnition" SG_ 2463978891 PetsMode_Enable 0;
BA_ "GenSigSendType" SG_ 2463978891 Selfie_Switch_FunctionState 3;
BA_ "GenSigSwitchedByIgnition" SG_ 2463978891 Selfie_Switch_FunctionState 0;
BA_ "GenSigSendType" SG_ 2463978891 Selfie_Switch_Resolution 3;
BA_ "GenSigSwitchedByIgnition" SG_ 2463978891 Selfie_Switch_Resolution 0;
BA_ "GenSigSendType" SG_ 1524 AMB_Charisma_FahrPr 3;
BA_ "GenSigSwitchedByIgnition" SG_ 1524 AMB_Charisma_FahrPr 0;
BA_ "GenSigSendType" SG_ 1524 AMB_Charisma_Status 3;
BA_ "GenSigSwitchedByIgnition" SG_ 1524 AMB_Charisma_Status 0;
BA_ "GenSigSendType" SG_ 1524 BCM1_DI_Rampe_Innenlicht 3;
BA_ "GenSigSwitchedByIgnition" SG_ 1524 BCM1_DI_Rampe_Innenlicht 0;
BA_ "GenSigSendType" SG_ 1524 BCM1_DI_Rampe_Leselicht 3;
BA_ "GenSigSwitchedByIgnition" SG_ 1524 BCM1_DI_Rampe_Leselicht 0;
BA_ "GenSigSendType" SG_ 1524 BCM1_Innenlicht_gedimmt_H 3;
BA_ "GenSigSwitchedByIgnition" SG_ 1524 BCM1_Innenlicht_gedimmt_H 0;
BA_ "GenSigSendType" SG_ 1524 BCM1_Innenlicht_gedimmt_V 3;
BA_ "GenSigSwitchedByIgnition" SG_ 1524 BCM1_Innenlicht_gedimmt_V 0;
BA_ "GenSigSendType" SG_ 1524 BCM1_Innenlicht_H 3;
BA_ "GenSigSwitchedByIgnition" SG_ 1524 BCM1_Innenlicht_H 0;
BA_ "GenSigSendType" SG_ 1524 BCM1_Innenlicht_V 3;
BA_ "GenSigSwitchedByIgnition" SG_ 1524 BCM1_Innenlicht_V 0;
BA_ "GenSigSendType" SG_ 1524 BCM1_Leselicht_Anf_hl 3;
BA_ "GenSigSwitchedByIgnition" SG_ 1524 BCM1_Leselicht_Anf_hl 0;
BA_ "GenSigSendType" SG_ 1524 BCM1_Leselicht_Anf_hr 3;
BA_ "GenSigSwitchedByIgnition" SG_ 1524 BCM1_Leselicht_Anf_hr 0;
BA_ "GenSigSendType" SG_ 1524 BCM1_Leselicht_Anf_vl 3;
BA_ "GenSigSwitchedByIgnition" SG_ 1524 BCM1_Leselicht_Anf_vl 0;
BA_ "GenSigSendType" SG_ 1524 BCM1_Leselicht_Anf_vr 3;
BA_ "GenSigSwitchedByIgnition" SG_ 1524 BCM1_Leselicht_Anf_vr 0;
BA_ "GenSigSendType" SG_ 1524 BCM1_Leuchten_Aus 3;
BA_ "GenSigSwitchedByIgnition" SG_ 1524 BCM1_Leuchten_Aus 0;
BA_ "GenSigSendType" SG_ 1524 IL_Bel_BFS_Ausstieg 3;
BA_ "GenSigSwitchedByIgnition" SG_ 1524 IL_Bel_BFS_Ausstieg 0;
BA_ "GenSigSendType" SG_ 1524 IL_Bel_FS_Ausstieg 3;
BA_ "GenSigSwitchedByIgnition" SG_ 1524 IL_Bel_FS_Ausstieg 0;
BA_ "GenSigSendType" SG_ 1524 IL_Bel_HBFS_Ausstieg 3;
BA_ "GenSigSwitchedByIgnition" SG_ 1524 IL_Bel_HBFS_Ausstieg 0;
BA_ "GenSigSendType" SG_ 1524 IL_Bel_HFS_Ausstieg 3;
BA_ "GenSigSwitchedByIgnition" SG_ 1524 IL_Bel_HFS_Ausstieg 0;
BA_ "GenSigSendType" SG_ 1524 IL_Dimmung_H_Tuerkontur 3;
BA_ "GenSigSwitchedByIgnition" SG_ 1524 IL_Dimmung_H_Tuerkontur 0;
BA_ "GenSigSendType" SG_ 1524 IL_Dimmung_Lautspr 3;
BA_ "GenSigSwitchedByIgnition" SG_ 1524 IL_Dimmung_Lautspr 0;
BA_ "GenSigSendType" SG_ 1524 IL_Dimmung_Tuerinnengriff 3;
BA_ "GenSigSwitchedByIgnition" SG_ 1524 IL_Dimmung_Tuerinnengriff 0;
BA_ "GenSigSendType" SG_ 1524 IL_Dimmung_Umfeldbel 3;
BA_ "GenSigSwitchedByIgnition" SG_ 1524 IL_Dimmung_Umfeldbel 0;
BA_ "GenSigSendType" SG_ 1524 IL_Dimmung_V_Tuerkontur 3;
BA_ "GenSigSwitchedByIgnition" SG_ 1524 IL_Dimmung_V_Tuerkontur 0;
BA_ "GenSigSendType" SG_ 1524 IL_Innenlicht_aktiv 3;
BA_ "GenSigStartValue" SG_ 1524 IL_Innenlicht_aktiv 1;
BA_ "GenSigSwitchedByIgnition" SG_ 1524 IL_Innenlicht_aktiv 0;
BA_ "GenSigSendType" SG_ 1524 IL_Klemme_30G_aktiv 3;
BA_ "GenSigSwitchedByIgnition" SG_ 1524 IL_Klemme_30G_aktiv 0;
BA_ "GenSigSendType" SG_ 1524 IL_Tuerkontakt_Taster 3;
BA_ "GenSigSwitchedByIgnition" SG_ 1524 IL_Tuerkontakt_Taster 0;
BA_ "GenSigSendType" SG_ 1879 ISO_ACC_Req_Data 3;
BA_ "GenSigFuncType" SG_ 1879 ISO_ACC_Req_Data 9;
BA_ "GenSigSwitchedByIgnition" SG_ 1879 ISO_ACC_Req_Data 0;
BA_ "GenSigSendType" SG_ 1985 ISO_ACC_Resp_Data 3;
BA_ "GenSigFuncType" SG_ 1985 ISO_ACC_Resp_Data 9;
BA_ "GenSigSwitchedByIgnition" SG_ 1985 ISO_ACC_Resp_Data 0;
BA_ "GenSigSendType" SG_ 1792 ISO_ALL_01_Req_Data 3;
BA_ "GenSigFuncType" SG_ 1792 ISO_ALL_01_Req_Data 9;
BA_ "GenSigSwitchedByIgnition" SG_ 1792 ISO_ALL_01_Req_Data 0;
BA_ "GenSigSendType" SG_ 1871 ISO_Kamera_Req_Data 3;
BA_ "GenSigFuncType" SG_ 1871 ISO_Kamera_Req_Data 9;
BA_ "GenSigSwitchedByIgnition" SG_ 1871 ISO_Kamera_Req_Data 0;
BA_ "GenSigSendType" SG_ 1977 ISO_Kamera_Resp_Data 3;
BA_ "GenSigFuncType" SG_ 1977 ISO_Kamera_Resp_Data 9;
BA_ "GenSigSwitchedByIgnition" SG_ 1977 ISO_Kamera_Resp_Data 0;
BA_ "GenSigSendType" SG_ 2621440087 ISOx_ACC_Req_FD_Data 3;
BA_ "GenSigFuncType" SG_ 2621440087 ISOx_ACC_Req_FD_Data 9;
BA_ "GenSigSwitchedByIgnition" SG_ 2621440087 ISOx_ACC_Req_FD_Data 0;
BA_ "GenSigSendType" SG_ 2621571159 ISOx_ACC_Resp_FD_Data 3;
BA_ "GenSigFuncType" SG_ 2621571159 ISOx_ACC_Resp_FD_Data 9;
BA_ "GenSigSwitchedByIgnition" SG_ 2621571159 ISOx_ACC_Resp_FD_Data 0;
BA_ "GenSigSendType" SG_ 2621505536 ISOx_Funkt_Req_All_FD_Data 3;
BA_ "GenSigFuncType" SG_ 2621505536 ISOx_Funkt_Req_All_FD_Data 9;
BA_ "GenSigSwitchedByIgnition" SG_ 2621505536 ISOx_Funkt_Req_All_FD_Data 0;
BA_ "GenSigSendType" SG_ 2621440079 ISOx_Kamera_Req_FD_Data 3;
BA_ "GenSigFuncType" SG_ 2621440079 ISOx_Kamera_Req_FD_Data 9;
BA_ "GenSigSwitchedByIgnition" SG_ 2621440079 ISOx_Kamera_Req_FD_Data 0;
BA_ "GenSigSendType" SG_ 2621571151 ISOx_Kamera_Resp_FD_Data 3;
BA_ "GenSigFuncType" SG_ 2621571151 ISOx_Kamera_Resp_FD_Data 9;
BA_ "GenSigSwitchedByIgnition" SG_ 2621571151 ISOx_Kamera_Resp_FD_Data 0;
BA_ "GenSigSendType" SG_ 2549874875 ISOx_NR_01_Req_Data 3;
BA_ "GenSigFuncType" SG_ 2549874875 ISOx_NR_01_Req_Data 9;
BA_ "GenSigSwitchedByIgnition" SG_ 2549874875 ISOx_NR_01_Req_Data 0;
BA_ "GenSigSendType" SG_ 2621440187 ISOx_NR_01_Req_FD_Data 3;
BA_ "GenSigFuncType" SG_ 2621440187 ISOx_NR_01_Req_FD_Data 9;
BA_ "GenSigSwitchedByIgnition" SG_ 2621440187 ISOx_NR_01_Req_FD_Data 0;
BA_ "GenSigSendType" SG_ 2550005947 ISOx_NR_01_Resp_Data 3;
BA_ "GenSigFuncType" SG_ 2550005947 ISOx_NR_01_Resp_Data 9;
BA_ "GenSigSwitchedByIgnition" SG_ 2550005947 ISOx_NR_01_Resp_Data 0;
BA_ "GenSigSendType" SG_ 2621571259 ISOx_NR_01_Resp_FD_Data 3;
BA_ "GenSigFuncType" SG_ 2621571259 ISOx_NR_01_Resp_FD_Data 9;
BA_ "GenSigSwitchedByIgnition" SG_ 2621571259 ISOx_NR_01_Resp_FD_Data 0;
BA_ "GenSigSendType" SG_ 2549874876 ISOx_NR_02_Req_Data 3;
BA_ "GenSigFuncType" SG_ 2549874876 ISOx_NR_02_Req_Data 9;
BA_ "GenSigSwitchedByIgnition" SG_ 2549874876 ISOx_NR_02_Req_Data 0;
BA_ "GenSigSendType" SG_ 2621440188 ISOx_NR_02_Req_FD_Data 3;
BA_ "GenSigFuncType" SG_ 2621440188 ISOx_NR_02_Req_FD_Data 9;
BA_ "GenSigSwitchedByIgnition" SG_ 2621440188 ISOx_NR_02_Req_FD_Data 0;
BA_ "GenSigSendType" SG_ 2550005948 ISOx_NR_02_Resp_Data 3;
BA_ "GenSigFuncType" SG_ 2550005948 ISOx_NR_02_Resp_Data 9;
BA_ "GenSigSwitchedByIgnition" SG_ 2550005948 ISOx_NR_02_Resp_Data 0;
BA_ "GenSigSendType" SG_ 2621571260 ISOx_NR_02_Resp_FD_Data 3;
BA_ "GenSigFuncType" SG_ 2621571260 ISOx_NR_02_Resp_FD_Data 9;
BA_ "GenSigSwitchedByIgnition" SG_ 2621571260 ISOx_NR_02_Resp_FD_Data 0;
BA_ "GenSigSendType" SG_ 2527679667 Kamera_AHC_L_Funktionsstatus 3;
BA_ "GenSigStartValue" SG_ 2527679667 Kamera_AHC_L_Funktionsstatus 15;
BA_ "GenSigSendType" SG_ 2527679667 Kamera_AHC_L_Gierwinkel 3;
BA_ "GenSigStartValue" SG_ 2527679667 Kamera_AHC_L_Gierwinkel 8191;
BA_ "GenSigSendType" SG_ 2527679667 Kamera_AHC_L_Nickwinkel 3;
BA_ "GenSigStartValue" SG_ 2527679667 Kamera_AHC_L_Nickwinkel 8191;
BA_ "GenSigSendType" SG_ 2527679667 Kamera_AHC_L_Qualitaet 3;
BA_ "GenSigStartValue" SG_ 2527679667 Kamera_AHC_L_Qualitaet 31;
BA_ "GenSigSendType" SG_ 2527679667 Kamera_AHC_L_ROI_ID 3;
BA_ "GenSigStartValue" SG_ 2527679667 Kamera_AHC_L_ROI_ID 15;
BA_ "GenSigSendType" SG_ 2527679667 Kamera_AHC_R_Funktionsstatus 3;
BA_ "GenSigStartValue" SG_ 2527679667 Kamera_AHC_R_Funktionsstatus 15;
BA_ "GenSigSendType" SG_ 2527679667 Kamera_AHC_R_Gierwinkel 3;
BA_ "GenSigStartValue" SG_ 2527679667 Kamera_AHC_R_Gierwinkel 8191;
BA_ "GenSigSendType" SG_ 2527679667 Kamera_AHC_R_Nickwinkel 3;
BA_ "GenSigStartValue" SG_ 2527679667 Kamera_AHC_R_Nickwinkel 8191;
BA_ "GenSigSendType" SG_ 2527679667 Kamera_AHC_R_Qualitaet 3;
BA_ "GenSigStartValue" SG_ 2527679667 Kamera_AHC_R_Qualitaet 31;
BA_ "GenSigSendType" SG_ 2527679667 Kamera_AHC_R_ROI_ID 3;
BA_ "GenSigStartValue" SG_ 2527679667 Kamera_AHC_R_ROI_ID 15;
BA_ "GenSigSendType" SG_ 2527679684 Kamera_ASM_Data_1 0;
BA_ "GenSigSendType" SG_ 2527679684 Kamera_ASM_Data_2 0;
BA_ "GenSigSendType" SG_ 2527679684 Kamera_ASM_Data_3 0;
BA_ "GenSigSendType" SG_ 2527679684 Kamera_ASM_Data_4 0;
BA_ "GenSigSendType" SG_ 2527679684 Kamera_ASM_Data_5 0;
BA_ "GenSigSendType" SG_ 2527679684 Kamera_ASM_Data_6 0;
BA_ "GenSigSendType" SG_ 2527679684 Kamera_ASM_Ereignis 3;
BA_ "GenSigSendType" SG_ 2527679684 Kamera_ASM_Zeitstempel_02 3;
BA_ "GenSigStartValue" SG_ 2527679684 Kamera_ASM_Zeitstempel_02 255;
BA_ "GenSigSwitchedByIgnition" SG_ 2527679684 Kamera_ASM_Zeitstempel_02 0;
BA_ "GenSigSendType" SG_ 2589283730 Kamera_SDA_Abstand_Spur_E1 0;
BA_ "GenSigStartValue" SG_ 2589283730 Kamera_SDA_Abstand_Spur_E1 63;
BA_ "GenSigSwitchedByIgnition" SG_ 2589283730 Kamera_SDA_Abstand_Spur_E1 0;
BA_ "GenSigSendType" SG_ 2589283730 Kamera_SDA_Abstand_Spur_E2 0;
BA_ "GenSigStartValue" SG_ 2589283730 Kamera_SDA_Abstand_Spur_E2 63;
BA_ "GenSigSwitchedByIgnition" SG_ 2589283730 Kamera_SDA_Abstand_Spur_E2 0;
BA_ "GenSigSendType" SG_ 2589283730 Kamera_SDA_Abstand_Spur_L1 0;
BA_ "GenSigStartValue" SG_ 2589283730 Kamera_SDA_Abstand_Spur_L1 63;
BA_ "GenSigSwitchedByIgnition" SG_ 2589283730 Kamera_SDA_Abstand_Spur_L1 0;
BA_ "GenSigSendType" SG_ 2589283730 Kamera_SDA_Abstand_Spur_L2 0;
BA_ "GenSigStartValue" SG_ 2589283730 Kamera_SDA_Abstand_Spur_L2 63;
BA_ "GenSigSwitchedByIgnition" SG_ 2589283730 Kamera_SDA_Abstand_Spur_L2 0;
BA_ "GenSigSendType" SG_ 2589283730 Kamera_SDA_Abstand_Spur_R1 0;
BA_ "GenSigStartValue" SG_ 2589283730 Kamera_SDA_Abstand_Spur_R1 63;
BA_ "GenSigSwitchedByIgnition" SG_ 2589283730 Kamera_SDA_Abstand_Spur_R1 0;
BA_ "GenSigSendType" SG_ 2589283730 Kamera_SDA_Abstand_Spur_R2 0;
BA_ "GenSigStartValue" SG_ 2589283730 Kamera_SDA_Abstand_Spur_R2 63;
BA_ "GenSigSwitchedByIgnition" SG_ 2589283730 Kamera_SDA_Abstand_Spur_R2 0;
BA_ "GenSigSendType" SG_ 2589283730 Kamera_SDA_Eigenblendung 0;
BA_ "GenSigSwitchedByIgnition" SG_ 2589283730 Kamera_SDA_Eigenblendung 0;
BA_ "GenSigSendType" SG_ 2589283730 Kamera_SDA_Geschw_Spur_E 0;
BA_ "GenSigStartValue" SG_ 2589283730 Kamera_SDA_Geschw_Spur_E 63;
BA_ "GenSigSwitchedByIgnition" SG_ 2589283730 Kamera_SDA_Geschw_Spur_E 0;
BA_ "GenSigSendType" SG_ 2589283730 Kamera_SDA_Geschw_Spur_L 0;
BA_ "GenSigStartValue" SG_ 2589283730 Kamera_SDA_Geschw_Spur_L 63;
BA_ "GenSigSwitchedByIgnition" SG_ 2589283730 Kamera_SDA_Geschw_Spur_L 0;
BA_ "GenSigSendType" SG_ 2589283730 Kamera_SDA_Geschw_Spur_R 0;
BA_ "GenSigStartValue" SG_ 2589283730 Kamera_SDA_Geschw_Spur_R 63;
BA_ "GenSigSwitchedByIgnition" SG_ 2589283730 Kamera_SDA_Geschw_Spur_R 0;
BA_ "GenSigSendType" SG_ 2589283730 Kamera_SDA_Sichtweite 0;
BA_ "GenSigSwitchedByIgnition" SG_ 2589283730 Kamera_SDA_Sichtweite 0;
BA_ "GenSigSendType" SG_ 2589283730 Kamera_SDA_Status_allg 0;
BA_ "GenSigSwitchedByIgnition" SG_ 2589283730 Kamera_SDA_Status_allg 0;
BA_ "Fehlerwert" SG_ 2589283730 Kamera_SDA_Status_allg 3;
BA_ "GenSigSendType" SG_ 2589283730 Kamera_SDA_Status_Beleuchtung 0;
BA_ "GenSigSwitchedByIgnition" SG_ 2589283730 Kamera_SDA_Status_Beleuchtung 0;
BA_ "GenSigSendType" SG_ 792 Kamera_FDD_Anz_Strassenleuchten 0;
BA_ "GenSigStartValue" SG_ 792 Kamera_FDD_Anz_Strassenleuchten 15;
BA_ "GenSigSendType" SG_ 792 Kamera_FDD_Eigenblend 0;
BA_ "GenSigSendType" SG_ 792 Kamera_FDD_Eigenblend_Guete 0;
BA_ "GenSigStartValue" SG_ 792 Kamera_FDD_Eigenblend_Guete 14;
BA_ "Fehlerwert" SG_ 792 Kamera_FDD_Eigenblend_Guete 15;
BA_ "GenSigSendType" SG_ 792 Kamera_FDD_Funktionsstatus 0;
BA_ "GenSigStartValue" SG_ 792 Kamera_FDD_Funktionsstatus 6;
BA_ "GenSigSendType" SG_ 792 Kamera_FDD_Strassenbeleuchung 0;
BA_ "GenSigSendType" SG_ 792 Kamera_FDD_Verkehrsrichtung 0;
BA_ "GenSigStartValue" SG_ 792 Kamera_FDD_Verkehrsrichtung 2;
BA_ "GenSigSendType" SG_ 792 Kamera_FSH_aktiv 0;
BA_ "GenSigSendType" SG_ 792 Kamera_Helligkeit 0;
BA_ "GenSigStartValue" SG_ 792 Kamera_Helligkeit 1022;
BA_ "Fehlerwert" SG_ 792 Kamera_Helligkeit 1023;
BA_ "GenSigSendType" SG_ 792 Kamera_Systemzustand 0;
BA_ "GenSigStartValue" SG_ 792 Kamera_Systemzustand 1;
BA_ "GenSigSendType" SG_ 792 VZE_Status_EDR 0;
BA_ "GenSigSendType" SG_ 960 BCM_Ausparken_Betrieb 3;
BA_ "GenSigSwitchedByIgnition" SG_ 960 BCM_Ausparken_Betrieb 0;
BA_ "GenSigSendType" SG_ 960 Klemmen_Status_01_BZ 0;
BA_ "GenSigFuncType" SG_ 960 Klemmen_Status_01_BZ 1;
BA_ "GenSigSwitchedByIgnition" SG_ 960 Klemmen_Status_01_BZ 0;
BA_ "GenSigSendType" SG_ 960 Klemmen_Status_01_CRC 0;
BA_ "GenSigFuncType" SG_ 960 Klemmen_Status_01_CRC 2;
BA_ "GenSigSwitchedByIgnition" SG_ 960 Klemmen_Status_01_CRC 0;
BA_ "GenSigSendType" SG_ 960 KST_Fahrerhinweis_1 3;
BA_ "GenSigSwitchedByIgnition" SG_ 960 KST_Fahrerhinweis_1 0;
BA_ "GenSigSendType" SG_ 960 KST_Fahrerhinweis_2 3;
BA_ "GenSigSwitchedByIgnition" SG_ 960 KST_Fahrerhinweis_2 0;
BA_ "GenSigSendType" SG_ 960 KST_Fahrerhinweis_4 3;
BA_ "GenSigSwitchedByIgnition" SG_ 960 KST_Fahrerhinweis_4 0;
BA_ "GenSigSendType" SG_ 960 KST_Fahrerhinweis_5 3;
BA_ "GenSigSwitchedByIgnition" SG_ 960 KST_Fahrerhinweis_5 0;
BA_ "GenSigSendType" SG_ 960 KST_Fahrerhinweis_6 3;
BA_ "GenSigSwitchedByIgnition" SG_ 960 KST_Fahrerhinweis_6 0;
BA_ "GenSigSendType" SG_ 960 KST_Warn_P1_ZST_def 3;
BA_ "GenSigSwitchedByIgnition" SG_ 960 KST_Warn_P1_ZST_def 0;
BA_ "GenSigSendType" SG_ 960 KST_Warn_P2_ZST_def 3;
BA_ "GenSigSwitchedByIgnition" SG_ 960 KST_Warn_P2_ZST_def 0;
BA_ "GenSigSendType" SG_ 960 RSt_Fahrerhinweise 3;
BA_ "GenSigSwitchedByIgnition" SG_ 960 RSt_Fahrerhinweise 0;
BA_ "GenSigSendType" SG_ 960 ZAS_Kl_15 3;
BA_ "NWM-WakeupAllowed" SG_ 960 ZAS_Kl_15 1;
BA_ "GenSigFuncType" SG_ 960 ZAS_Kl_15 6;
BA_ "GenSigSwitchedByIgnition" SG_ 960 ZAS_Kl_15 0;
BA_ "GenSigSendType" SG_ 960 ZAS_Kl_50_Startanforderung 3;
BA_ "GenSigSwitchedByIgnition" SG_ 960 ZAS_Kl_50_Startanforderung 0;
BA_ "GenSigSendType" SG_ 960 ZAS_Kl_Infotainment 3;
BA_ "GenSigSwitchedByIgnition" SG_ 960 ZAS_Kl_Infotainment 0;
BA_ "GenSigSendType" SG_ 960 ZAS_Kl_S 3;
BA_ "GenSigSwitchedByIgnition" SG_ 960 ZAS_Kl_S 0;
BA_ "GenSigSendType" SG_ 960 ZAS_Kl_X 3;
BA_ "GenSigSwitchedByIgnition" SG_ 960 ZAS_Kl_X 0;
BA_ "GenSigSendType" SG_ 2463978753 Klemmen_Status_02_BZ 0;
BA_ "GenSigFuncType" SG_ 2463978753 Klemmen_Status_02_BZ 1;
BA_ "GenSigSwitchedByIgnition" SG_ 2463978753 Klemmen_Status_02_BZ 0;
BA_ "GenSigSendType" SG_ 2463978753 Klemmen_Status_02_CRC 0;
BA_ "GenSigFuncType" SG_ 2463978753 Klemmen_Status_02_CRC 2;
BA_ "GenSigSwitchedByIgnition" SG_ 2463978753 Klemmen_Status_02_CRC 0;
BA_ "GenSigSendType" SG_ 2463978753 KST_ComfortReadyStatus 4;
BA_ "GenSigSwitchedByIgnition" SG_ 2463978753 KST_ComfortReadyStatus 0;
BA_ "GenSigSendType" SG_ 2463978753 KST_Sonderzustand_Anforderung 4;
BA_ "GenSigSwitchedByIgnition" SG_ 2463978753 KST_Sonderzustand_Anforderung 0;
BA_ "Fehlerwert" SG_ 2463978753 KST_Sonderzustand_Anforderung 31;
BA_ "GenSigSendType" SG_ 2463978753 KST_Sonderzustand_Status 4;
BA_ "GenSigSwitchedByIgnition" SG_ 2463978753 KST_Sonderzustand_Status 0;
BA_ "Fehlerwert" SG_ 2463978753 KST_Sonderzustand_Status 3;
BA_ "GenSigSendType" SG_ 2463978753 KST_WFS_Fahrfreigabe_Anforderung 4;
BA_ "GenSigSwitchedByIgnition" SG_ 2463978753 KST_WFS_Fahrfreigabe_Anforderung 0;
BA_ "GenSigActiveRepetitions" SG_ 1640 FSH_Taster 5;
BA_ "GenSigSendType" SG_ 1640 FSH_Taster 4;
BA_ "GenSigSwitchedByIgnition" SG_ 1640 FSH_Taster 0;
BA_ "GenSigActiveRepetitions" SG_ 1640 HSH_Taster 5;
BA_ "GenSigSendType" SG_ 1640 HSH_Taster 4;
BA_ "GenSigSwitchedByIgnition" SG_ 1640 HSH_Taster 0;
BA_ "GenSigSendType" SG_ 1640 KL_Beschlagsgefahr 3;
BA_ "GenSigSwitchedByIgnition" SG_ 1640 KL_Beschlagsgefahr 0;
BA_ "GenSigSendType" SG_ 1640 KL_Geblspng_Fond_Soll 0;
BA_ "GenSigSwitchedByIgnition" SG_ 1640 KL_Geblspng_Fond_Soll 0;
BA_ "Fehlerwert" SG_ 1640 KL_Geblspng_Fond_Soll 255;
BA_ "GenSigSendType" SG_ 1640 KL_Geblspng_Soll 0;
BA_ "GenSigSwitchedByIgnition" SG_ 1640 KL_Geblspng_Soll 0;
BA_ "Fehlerwert" SG_ 1640 KL_Geblspng_Soll 255;
BA_ "GenSigSendType" SG_ 1640 KL_I_Geblaese 0;
BA_ "GenSigSwitchedByIgnition" SG_ 1640 KL_I_Geblaese 0;
BA_ "Fehlerwert" SG_ 1640 KL_I_Geblaese 255;
BA_ "GenSigSendType" SG_ 1640 KL_Kompressorstrom_soll 0;
BA_ "GenSigStartValue" SG_ 1640 KL_Kompressorstrom_soll 1022;
BA_ "GenSigSwitchedByIgnition" SG_ 1640 KL_Kompressorstrom_soll 0;
BA_ "Fehlerwert" SG_ 1640 KL_Kompressorstrom_soll 1023;
BA_ "GenSigSendType" SG_ 1640 KL_LRH_Stufe 3;
BA_ "GenSigStartValue" SG_ 1640 KL_LRH_Stufe 1;
BA_ "GenSigSwitchedByIgnition" SG_ 1640 KL_LRH_Stufe 0;
BA_ "GenSigActiveRepetitions" SG_ 1640 KL_LRH_Taster 5;
BA_ "GenSigSendType" SG_ 1640 KL_LRH_Taster 4;
BA_ "GenSigSwitchedByIgnition" SG_ 1640 KL_LRH_Taster 0;
BA_ "GenSigSendType" SG_ 1640 KL_PTC_Verbauinfo 0;
BA_ "GenSigSwitchedByIgnition" SG_ 1640 KL_PTC_Verbauinfo 0;
BA_ "GenSigSendType" SG_ 1640 KL_SIH_Soll_li 3;
BA_ "GenSigSwitchedByIgnition" SG_ 1640 KL_SIH_Soll_li 0;
BA_ "GenSigSendType" SG_ 1640 KL_SIH_Soll_re 3;
BA_ "GenSigSwitchedByIgnition" SG_ 1640 KL_SIH_Soll_re 0;
BA_ "GenSigSendType" SG_ 1640 KL_SIL_Soll_li 3;
BA_ "GenSigSwitchedByIgnition" SG_ 1640 KL_SIL_Soll_li 0;
BA_ "GenSigSendType" SG_ 1640 KL_SIL_Soll_re 3;
BA_ "GenSigSwitchedByIgnition" SG_ 1640 KL_SIL_Soll_re 0;
BA_ "GenSigSendType" SG_ 1640 KL_Umluftklappe_Status 0;
BA_ "GenSigStartValue" SG_ 1640 KL_Umluftklappe_Status 14;
BA_ "GenSigSwitchedByIgnition" SG_ 1640 KL_Umluftklappe_Status 0;
BA_ "Fehlerwert" SG_ 1640 KL_Umluftklappe_Status 15;
BA_ "GenSigSendType" SG_ 1640 KL_Zuheizer_Freigabe 3;
BA_ "GenSigSwitchedByIgnition" SG_ 1640 KL_Zuheizer_Freigabe 0;
BA_ "GenSigSendType" SG_ 1640 KRH_Soll_li 3;
BA_ "GenSigSwitchedByIgnition" SG_ 1640 KRH_Soll_li 0;
BA_ "GenSigSendType" SG_ 1640 KRH_Soll_re 3;
BA_ "GenSigSwitchedByIgnition" SG_ 1640 KRH_Soll_re 0;
BA_ "GenSigSendType" SG_ 1505 BCM1_Aussen_Temp_ungef 0;
BA_ "GenSigStartValue" SG_ 1505 BCM1_Aussen_Temp_ungef 254;
BA_ "GenSigSwitchedByIgnition" SG_ 1505 BCM1_Aussen_Temp_ungef 0;
BA_ "Fehlerwert" SG_ 1505 BCM1_Aussen_Temp_ungef 255;
BA_ "GenSigSendType" SG_ 1505 BCM1_FStatus_Aussentemp_ungef 0;
BA_ "GenSigStartValue" SG_ 1505 BCM1_FStatus_Aussentemp_ungef 1;
BA_ "GenSigSwitchedByIgnition" SG_ 1505 BCM1_FStatus_Aussentemp_ungef 0;
BA_ "GenSigSendType" SG_ 1505 BCM1_Kompressorstrom_ist 0;
BA_ "GenSigStartValue" SG_ 1505 BCM1_Kompressorstrom_ist 254;
BA_ "GenSigSwitchedByIgnition" SG_ 1505 BCM1_Kompressorstrom_ist 0;
BA_ "Fehlerwert" SG_ 1505 BCM1_Kompressorstrom_ist 255;
BA_ "GenSigSendType" SG_ 1505 BCM1_OBD_FStatus_ATemp 0;
BA_ "GenSigSwitchedByIgnition" SG_ 1505 BCM1_OBD_FStatus_ATemp 0;
BA_ "GenSigSendType" SG_ 1505 BCM1_PTC_stufig_Status 0;
BA_ "GenSigStartValue" SG_ 1505 BCM1_PTC_stufig_Status 6;
BA_ "GenSigSwitchedByIgnition" SG_ 1505 BCM1_PTC_stufig_Status 0;
BA_ "Fehlerwert" SG_ 1505 BCM1_PTC_stufig_Status 7;
BA_ "GenSigSendType" SG_ 1505 BCM_Heizungsabsperrventil_Status 0;
BA_ "GenSigStartValue" SG_ 1505 BCM_Heizungsabsperrventil_Status 2;
BA_ "GenSigSwitchedByIgnition" SG_ 1505 BCM_Heizungsabsperrventil_Status 0;
BA_ "Fehlerwert" SG_ 1505 BCM_Heizungsabsperrventil_Status 3;
BA_ "GenSigSendType" SG_ 1505 BCM_Heizungspumpe_Status 0;
BA_ "GenSigStartValue" SG_ 1505 BCM_Heizungspumpe_Status 2;
BA_ "GenSigSwitchedByIgnition" SG_ 1505 BCM_Heizungspumpe_Status 0;
BA_ "Fehlerwert" SG_ 1505 BCM_Heizungspumpe_Status 3;
BA_ "GenSigSendType" SG_ 1505 BCM_Kompressorkupplung_Status 0;
BA_ "GenSigStartValue" SG_ 1505 BCM_Kompressorkupplung_Status 2;
BA_ "GenSigSwitchedByIgnition" SG_ 1505 BCM_Kompressorkupplung_Status 0;
BA_ "Fehlerwert" SG_ 1505 BCM_Kompressorkupplung_Status 3;
BA_ "GenSigSendType" SG_ 605 KLR_01_BZ 0;
BA_ "GenSigFuncType" SG_ 605 KLR_01_BZ 1;
BA_ "GenSigSwitchedByIgnition" SG_ 605 KLR_01_BZ 0;
BA_ "GenSigSendType" SG_ 605 KLR_01_CRC 0;
BA_ "GenSigFuncType" SG_ 605 KLR_01_CRC 2;
BA_ "GenSigSwitchedByIgnition" SG_ 605 KLR_01_CRC 0;
BA_ "GenSigSendType" SG_ 605 KLR_Fehler 0;
BA_ "GenSigSwitchedByIgnition" SG_ 605 KLR_Fehler 0;
BA_ "Fehlerwert" SG_ 605 KLR_Fehler 1;
BA_ "GenSigSendType" SG_ 605 KLR_Fehler_Codierung 0;
BA_ "GenSigSwitchedByIgnition" SG_ 605 KLR_Fehler_Codierung 0;
BA_ "Fehlerwert" SG_ 605 KLR_Fehler_Codierung 1;
BA_ "GenSigSendType" SG_ 605 KLR_reserveByte2_6 0;
BA_ "GenSigSendType" SG_ 605 KLR_reserveByte6_4 0;
BA_ "GenSigSendType" SG_ 605 KLR_reserveByte7 0;
BA_ "GenSigSendType" SG_ 605 KLR_reserveByte8 0;
BA_ "GenSigSendType" SG_ 605 KLR_ResponseError 0;
BA_ "GenSigSwitchedByIgnition" SG_ 605 KLR_ResponseError 0;
BA_ "Fehlerwert" SG_ 605 KLR_ResponseError 1;
BA_ "GenSigSendType" SG_ 605 KLR_Touchauswertung 0;
BA_ "GenSigStartValue" SG_ 605 KLR_Touchauswertung 14;
BA_ "GenSigSwitchedByIgnition" SG_ 605 KLR_Touchauswertung 0;
BA_ "GenSigSendType" SG_ 605 KLR_Touchintensitaet_1 0;
BA_ "GenSigStartValue" SG_ 605 KLR_Touchintensitaet_1 254;
BA_ "GenSigSwitchedByIgnition" SG_ 605 KLR_Touchintensitaet_1 0;
BA_ "Fehlerwert" SG_ 605 KLR_Touchintensitaet_1 255;
BA_ "GenSigSendType" SG_ 605 KLR_Touchintensitaet_2 0;
BA_ "GenSigStartValue" SG_ 605 KLR_Touchintensitaet_2 254;
BA_ "GenSigSwitchedByIgnition" SG_ 605 KLR_Touchintensitaet_2 0;
BA_ "Fehlerwert" SG_ 605 KLR_Touchintensitaet_2 255;
BA_ "GenSigSendType" SG_ 605 KLR_Touchintensitaet_3 0;
BA_ "GenSigStartValue" SG_ 605 KLR_Touchintensitaet_3 254;
BA_ "GenSigSwitchedByIgnition" SG_ 605 KLR_Touchintensitaet_3 0;
BA_ "Fehlerwert" SG_ 605 KLR_Touchintensitaet_3 255;
BA_ "GenSigSendType" SG_ 2549088343 ACC_Abschaltstufe 0;
BA_ "GenSigSendType" SG_ 2549088343 ACC_KD_Fehler 0;
BA_ "GenSigSendType" SG_ 2549088343 ACC_KompSchutz 0;
BA_ "GenSigSendType" SG_ 2549088343 ACC_Nachlauftyp 0;
BA_ "GenSigSendType" SG_ 2549088343 ACC_Transport_Mode 0;
BA_ "GenSigSendType" SG_ 2549088343 KN_ACC_BusKnockOut 0;
BA_ "GenSigSwitchedByIgnition" SG_ 2549088343 KN_ACC_BusKnockOut 0;
BA_ "GenSigSendType" SG_ 2549088343 KN_ACC_BusKnockOutTimer 0;
BA_ "GenSigSwitchedByIgnition" SG_ 2549088343 KN_ACC_BusKnockOutTimer 0;
BA_ "GenSigSendType" SG_ 2549088343 KN_ACC_DiagPfad 0;
BA_ "GenSigSwitchedByIgnition" SG_ 2549088343 KN_ACC_DiagPfad 0;
BA_ "GenSigSendType" SG_ 2549088343 KN_ACC_ECUKnockOut 0;
BA_ "GenSigSwitchedByIgnition" SG_ 2549088343 KN_ACC_ECUKnockOut 0;
BA_ "GenSigSendType" SG_ 2549088343 KN_ACC_ECUKnockOutTimer 0;
BA_ "GenSigSwitchedByIgnition" SG_ 2549088343 KN_ACC_ECUKnockOutTimer 0;
BA_ "GenSigSendType" SG_ 2549088343 NM_ACC_Wakeup 0;
BA_ "GenSigStartValue" SG_ 2549088343 NM_ACC_Wakeup 2;
BA_ "NWM-WakeupAllowed" SG_ 2549088343 NM_ACC_Wakeup 1;
BA_ "GenSigSwitchedByIgnition" SG_ 2549088343 NM_ACC_Wakeup 0;
BA_ "GenSigSendType" SG_ 2549088272 Gateway_Abschaltstufe 0;
BA_ "GenSigSwitchedByIgnition" SG_ 2549088272 Gateway_Abschaltstufe 0;
BA_ "GenSigSendType" SG_ 2549088272 Gateway_KompSchutz 0;
BA_ "GenSigSwitchedByIgnition" SG_ 2549088272 Gateway_KompSchutz 0;
BA_ "GenSigSendType" SG_ 2549088272 Gateway_Nachlauftyp 0;
BA_ "GenSigStartValue" SG_ 2549088272 Gateway_Nachlauftyp 2;
BA_ "GenSigSwitchedByIgnition" SG_ 2549088272 Gateway_Nachlauftyp 0;
BA_ "GenSigSendType" SG_ 2549088272 Gateway_Transport_Mode 0;
BA_ "GenSigSwitchedByIgnition" SG_ 2549088272 Gateway_Transport_Mode 0;
BA_ "GenSigSendType" SG_ 2549088272 GW_KD_Fehler 0;
BA_ "GenSigSendType" SG_ 2549088272 KN_GW_DiagPfad 0;
BA_ "GenSigSwitchedByIgnition" SG_ 2549088272 KN_GW_DiagPfad 0;
BA_ "GenSigSendType" SG_ 2549088272 NM_Gateway_Wakeup 0;
BA_ "NWM-WakeupAllowed" SG_ 2549088272 NM_Gateway_Wakeup 1;
BA_ "GenSigSwitchedByIgnition" SG_ 2549088272 NM_Gateway_Wakeup 0;
BA_ "GenSigSendType" SG_ 2549088335 Kamera_Abschaltstufe 0;
BA_ "GenSigSendType" SG_ 2549088335 Kamera_KD_Fehler 0;
BA_ "GenSigSendType" SG_ 2549088335 Kamera_KompSchutz 0;
BA_ "GenSigSendType" SG_ 2549088335 Kamera_Nachlauftyp 0;
BA_ "GenSigSendType" SG_ 2549088335 Kamera_Transport_Mode 0;
BA_ "GenSigSendType" SG_ 2549088335 KN_Kamera_BusKnockOut 0;
BA_ "GenSigSwitchedByIgnition" SG_ 2549088335 KN_Kamera_BusKnockOut 0;
BA_ "GenSigSendType" SG_ 2549088335 KN_Kamera_BusKnockOutTimer 0;
BA_ "GenSigSwitchedByIgnition" SG_ 2549088335 KN_Kamera_BusKnockOutTimer 0;
BA_ "GenSigSendType" SG_ 2549088335 KN_Kamera_DiagPfad 0;
BA_ "GenSigSwitchedByIgnition" SG_ 2549088335 KN_Kamera_DiagPfad 0;
BA_ "GenSigSendType" SG_ 2549088335 KN_Kamera_ECUKnockOut 0;
BA_ "GenSigSwitchedByIgnition" SG_ 2549088335 KN_Kamera_ECUKnockOut 0;
BA_ "GenSigSendType" SG_ 2549088335 KN_Kamera_ECUKnockOutTimer 0;
BA_ "GenSigSwitchedByIgnition" SG_ 2549088335 KN_Kamera_ECUKnockOutTimer 0;
BA_ "GenSigSendType" SG_ 2549088335 NM_Kamera_Wakeup 0;
BA_ "GenSigSwitchedByIgnition" SG_ 2549088335 NM_Kamera_Wakeup 0;
BA_ "GenSigSendType" SG_ 2549088313 KN_MIK_BusKnockOut 0;
BA_ "GenSigSwitchedByIgnition" SG_ 2549088313 KN_MIK_BusKnockOut 0;
BA_ "GenSigSendType" SG_ 2549088313 KN_MIK_BusKnockOutTimer 0;
BA_ "GenSigSwitchedByIgnition" SG_ 2549088313 KN_MIK_BusKnockOutTimer 0;
BA_ "GenSigSendType" SG_ 2549088313 KN_MIK_DiagPfad 0;
BA_ "GenSigSwitchedByIgnition" SG_ 2549088313 KN_MIK_DiagPfad 0;
BA_ "GenSigSendType" SG_ 2549088313 KN_MIK_ECUKnockOut 0;
BA_ "GenSigSwitchedByIgnition" SG_ 2549088313 KN_MIK_ECUKnockOut 0;
BA_ "GenSigSendType" SG_ 2549088313 KN_MIK_ECUKnockOutTimer 0;
BA_ "GenSigSwitchedByIgnition" SG_ 2549088313 KN_MIK_ECUKnockOutTimer 0;
BA_ "GenSigSendType" SG_ 2549088313 MIK_Abschaltstufe 0;
BA_ "GenSigSwitchedByIgnition" SG_ 2549088313 MIK_Abschaltstufe 0;
BA_ "GenSigSendType" SG_ 2549088313 MIK_KD_Fehler 0;
BA_ "GenSigSwitchedByIgnition" SG_ 2549088313 MIK_KD_Fehler 0;
BA_ "GenSigSendType" SG_ 2549088313 MIK_KompSchutz 0;
BA_ "GenSigSwitchedByIgnition" SG_ 2549088313 MIK_KompSchutz 0;
BA_ "GenSigSendType" SG_ 2549088313 MIK_Nachlauftyp 0;
BA_ "GenSigStartValue" SG_ 2549088313 MIK_Nachlauftyp 2;
BA_ "GenSigSwitchedByIgnition" SG_ 2549088313 MIK_Nachlauftyp 0;
BA_ "GenSigSendType" SG_ 2549088313 MIK_Transport_Mode 0;
BA_ "GenSigSwitchedByIgnition" SG_ 2549088313 MIK_Transport_Mode 0;
BA_ "GenSigSendType" SG_ 2549088313 NM_MIK_Wakeup 0;
BA_ "NWM-WakeupAllowed" SG_ 2549088313 NM_MIK_Wakeup 1;
BA_ "GenSigSwitchedByIgnition" SG_ 2549088313 NM_MIK_Wakeup 0;
BA_ "GenSigSendType" SG_ 2549088443 KN_NR_01_BusKnockOut 0;
BA_ "GenSigSwitchedByIgnition" SG_ 2549088443 KN_NR_01_BusKnockOut 0;
BA_ "GenSigSendType" SG_ 2549088443 KN_NR_01_BusKnockOutTimer 0;
BA_ "GenSigSwitchedByIgnition" SG_ 2549088443 KN_NR_01_BusKnockOutTimer 0;
BA_ "GenSigSendType" SG_ 2549088443 KN_NR_01_DiagPfad 0;
BA_ "GenSigSwitchedByIgnition" SG_ 2549088443 KN_NR_01_DiagPfad 0;
BA_ "GenSigSendType" SG_ 2549088443 KN_NR_01_ECUKnockOut 0;
BA_ "GenSigSwitchedByIgnition" SG_ 2549088443 KN_NR_01_ECUKnockOut 0;
BA_ "GenSigSendType" SG_ 2549088443 KN_NR_01_ECUKnockOutTimer 0;
BA_ "GenSigSwitchedByIgnition" SG_ 2549088443 KN_NR_01_ECUKnockOutTimer 0;
BA_ "GenSigSendType" SG_ 2549088443 NM_NR_01_Wakeup 0;
BA_ "GenSigSwitchedByIgnition" SG_ 2549088443 NM_NR_01_Wakeup 0;
BA_ "GenSigSendType" SG_ 2549088443 NR_01_Abschaltstufe 0;
BA_ "GenSigSwitchedByIgnition" SG_ 2549088443 NR_01_Abschaltstufe 0;
BA_ "GenSigSendType" SG_ 2549088443 NR_01_KD_Fehler 0;
BA_ "GenSigSwitchedByIgnition" SG_ 2549088443 NR_01_KD_Fehler 0;
BA_ "GenSigSendType" SG_ 2549088443 NR_01_KompSchutz 0;
BA_ "GenSigSwitchedByIgnition" SG_ 2549088443 NR_01_KompSchutz 0;
BA_ "GenSigSendType" SG_ 2549088443 NR_01_Nachlauftyp 0;
BA_ "GenSigStartValue" SG_ 2549088443 NR_01_Nachlauftyp 2;
BA_ "GenSigSwitchedByIgnition" SG_ 2549088443 NR_01_Nachlauftyp 0;
BA_ "GenSigSendType" SG_ 2549088443 NR_01_Transport_Mode 0;
BA_ "GenSigSwitchedByIgnition" SG_ 2549088443 NR_01_Transport_Mode 0;
BA_ "GenSigSendType" SG_ 2549088444 KN_NR_02_BusKnockOut 0;
BA_ "GenSigSwitchedByIgnition" SG_ 2549088444 KN_NR_02_BusKnockOut 0;
BA_ "GenSigSendType" SG_ 2549088444 KN_NR_02_BusKnockOutTimer 0;
BA_ "GenSigSwitchedByIgnition" SG_ 2549088444 KN_NR_02_BusKnockOutTimer 0;
BA_ "GenSigSendType" SG_ 2549088444 KN_NR_02_DiagPfad 0;
BA_ "GenSigSwitchedByIgnition" SG_ 2549088444 KN_NR_02_DiagPfad 0;
BA_ "GenSigSendType" SG_ 2549088444 KN_NR_02_ECUKnockOut 0;
BA_ "GenSigSwitchedByIgnition" SG_ 2549088444 KN_NR_02_ECUKnockOut 0;
BA_ "GenSigSendType" SG_ 2549088444 KN_NR_02_ECUKnockOutTimer 0;
BA_ "GenSigSwitchedByIgnition" SG_ 2549088444 KN_NR_02_ECUKnockOutTimer 0;
BA_ "GenSigSendType" SG_ 2549088444 NM_NR_02_Wakeup 0;
BA_ "GenSigSwitchedByIgnition" SG_ 2549088444 NM_NR_02_Wakeup 0;
BA_ "GenSigSendType" SG_ 2549088444 NR_02_Abschaltstufe 0;
BA_ "GenSigSwitchedByIgnition" SG_ 2549088444 NR_02_Abschaltstufe 0;
BA_ "GenSigSendType" SG_ 2549088444 NR_02_KD_Fehler 0;
BA_ "GenSigSwitchedByIgnition" SG_ 2549088444 NR_02_KD_Fehler 0;
BA_ "GenSigSendType" SG_ 2549088444 NR_02_KompSchutz 0;
BA_ "GenSigSwitchedByIgnition" SG_ 2549088444 NR_02_KompSchutz 0;
BA_ "GenSigSendType" SG_ 2549088444 NR_02_Nachlauftyp 0;
BA_ "GenSigStartValue" SG_ 2549088444 NR_02_Nachlauftyp 2;
BA_ "GenSigSwitchedByIgnition" SG_ 2549088444 NR_02_Nachlauftyp 0;
BA_ "GenSigSendType" SG_ 2549088444 NR_02_Transport_Mode 0;
BA_ "GenSigSwitchedByIgnition" SG_ 2549088444 NR_02_Transport_Mode 0;
BA_ "GenSigSendType" SG_ 2621440343 KS_ACC_Req_FD_Data 1;
BA_ "GenSigFuncType" SG_ 2621440343 KS_ACC_Req_FD_Data 9;
BA_ "GenSigSwitchedByIgnition" SG_ 2621440343 KS_ACC_Req_FD_Data 0;
BA_ "GenSigSendType" SG_ 2621571415 KS_ACC_Resp_FD_Data 1;
BA_ "GenSigFuncType" SG_ 2621571415 KS_ACC_Resp_FD_Data 9;
BA_ "GenSigSwitchedByIgnition" SG_ 2621571415 KS_ACC_Resp_FD_Data 0;
BA_ "GenSigSendType" SG_ 2621440335 KS_Kamera_Req_FD_Data 1;
BA_ "GenSigFuncType" SG_ 2621440335 KS_Kamera_Req_FD_Data 9;
BA_ "GenSigSwitchedByIgnition" SG_ 2621440335 KS_Kamera_Req_FD_Data 0;
BA_ "GenSigSendType" SG_ 2621571407 KS_Kamera_Resp_FD_Data 1;
BA_ "GenSigFuncType" SG_ 2621571407 KS_Kamera_Resp_FD_Data 9;
BA_ "GenSigSwitchedByIgnition" SG_ 2621571407 KS_Kamera_Resp_FD_Data 0;
BA_ "GenSigSendType" SG_ 2621440443 KS_NR_01_Req_FD_Data 3;
BA_ "GenSigFuncType" SG_ 2621440443 KS_NR_01_Req_FD_Data 9;
BA_ "GenSigSwitchedByIgnition" SG_ 2621440443 KS_NR_01_Req_FD_Data 0;
BA_ "GenSigSendType" SG_ 2621571515 KS_NR_01_Resp_FD_Data 3;
BA_ "GenSigFuncType" SG_ 2621571515 KS_NR_01_Resp_FD_Data 9;
BA_ "GenSigSwitchedByIgnition" SG_ 2621571515 KS_NR_01_Resp_FD_Data 0;
BA_ "GenSigSendType" SG_ 2621440444 KS_NR_02_Req_FD_Data 3;
BA_ "GenSigFuncType" SG_ 2621440444 KS_NR_02_Req_FD_Data 9;
BA_ "GenSigSwitchedByIgnition" SG_ 2621440444 KS_NR_02_Req_FD_Data 0;
BA_ "GenSigSendType" SG_ 2621571516 KS_NR_02_Resp_FD_Data 3;
BA_ "GenSigFuncType" SG_ 2621571516 KS_NR_02_Resp_FD_Data 9;
BA_ "GenSigSwitchedByIgnition" SG_ 2621571516 KS_NR_02_Resp_FD_Data 0;
BA_ "GenSigSendType" SG_ 919 aLDW_FoD_Status 0;
BA_ "GenSigSwitchedByIgnition" SG_ 919 aLDW_FoD_Status 0;
BA_ "GenSigSendType" SG_ 919 HC_Uss_Anforderung 3;
BA_ "GenSigSwitchedByIgnition" SG_ 919 HC_Uss_Anforderung 0;
BA_ "GenSigSendType" SG_ 919 LDW_DLC 0;
BA_ "GenSigStartValue" SG_ 919 LDW_DLC 250;
BA_ "GenSigSendType" SG_ 919 LDW_Frueh_Spaet 0;
BA_ "GenSigStartValue" SG_ 919 LDW_Frueh_Spaet 2;
BA_ "Fehlerwert" SG_ 919 LDW_Frueh_Spaet 3;
BA_ "GenSigSendType" SG_ 919 LDW_Gong 0;
BA_ "GenSigSendType" SG_ 919 LDW_Lernmodus_seitenabhaengig 3;
BA_ "GenSigSendType" SG_ 919 LDW_Seite_DLCTLC 0;
BA_ "GenSigSendType" SG_ 919 LDW_Status_Anzeige 0;
BA_ "GenSigSwitchedByIgnition" SG_ 919 LDW_Status_Anzeige 0;
BA_ "GenSigSendType" SG_ 919 LDW_Status_Grid 0;
BA_ "GenSigSendType" SG_ 919 LDW_Status_LED_gelb 0;
BA_ "GenSigSendType" SG_ 919 LDW_Status_LED_gruen 0;
BA_ "GenSigSendType" SG_ 919 LDW_Texte 0;
BA_ "GenSigSendType" SG_ 919 LDW_TLC 0;
BA_ "GenSigStartValue" SG_ 919 LDW_TLC 31;
BA_ "GenSigSendType" SG_ 810 EPS_01_BZ 0;
BA_ "GenSigFuncType" SG_ 810 EPS_01_BZ 1;
BA_ "GenSigSwitchedByIgnition" SG_ 810 EPS_01_BZ 0;
BA_ "GenSigSendType" SG_ 810 EPS_01_CRC 0;
BA_ "GenSigFuncType" SG_ 810 EPS_01_CRC 2;
BA_ "GenSigSwitchedByIgnition" SG_ 810 EPS_01_CRC 0;
BA_ "GenSigSendType" SG_ 810 EPS_Akustiksignal 0;
BA_ "GenSigSwitchedByIgnition" SG_ 810 EPS_Akustiksignal 0;
BA_ "GenSigSendType" SG_ 810 EPS_Anf_KL 0;
BA_ "GenSigSwitchedByIgnition" SG_ 810 EPS_Anf_KL 0;
BA_ "GenSigSendType" SG_ 810 EPS_ARA_Status 0;
BA_ "GenSigSwitchedByIgnition" SG_ 810 EPS_ARA_Status 0;
BA_ "GenSigSendType" SG_ 810 EPS_Charisma_FahrPr 0;
BA_ "GenSigSwitchedByIgnition" SG_ 810 EPS_Charisma_FahrPr 0;
BA_ "GenSigSendType" SG_ 810 EPS_Charisma_Status 0;
BA_ "GenSigSwitchedByIgnition" SG_ 810 EPS_Charisma_Status 0;
BA_ "GenSigSendType" SG_ 810 EPS_Endanschlag 0;
BA_ "Fehlerwert" SG_ 810 EPS_Endanschlag 3;
BA_ "GenSigSendType" SG_ 810 EPS_Fehlerlampe 0;
BA_ "GenSigSwitchedByIgnition" SG_ 810 EPS_Fehlerlampe 0;
BA_ "GenSigSendType" SG_ 810 EPS_Lenkerposition 0;
BA_ "GenSigFuncType" SG_ 810 EPS_Lenkerposition 8;
BA_ "GenSigSwitchedByIgnition" SG_ 810 EPS_Lenkerposition 0;
BA_ "GenSigSendType" SG_ 810 EPS_PLA_Abbruch 0;
BA_ "GenSigSwitchedByIgnition" SG_ 810 EPS_PLA_Abbruch 0;
BA_ "GenSigSendType" SG_ 810 EPS_PLA_Fehler 0;
BA_ "GenSigSwitchedByIgnition" SG_ 810 EPS_PLA_Fehler 0;
BA_ "GenSigSendType" SG_ 810 EPS_PLA_Status 0;
BA_ "GenSigSwitchedByIgnition" SG_ 810 EPS_PLA_Status 0;
BA_ "GenSigSendType" SG_ 810 EPS_SpannungsAnf 0;
BA_ "GenSigSwitchedByIgnition" SG_ 810 EPS_SpannungsAnf 0;
BA_ "GenSigSendType" SG_ 810 EPS_VZ_Zst_Offset_Geradeaus 0;
BA_ "GenSigSwitchedByIgnition" SG_ 810 EPS_VZ_Zst_Offset_Geradeaus 0;
BA_ "GenSigSendType" SG_ 810 EPS_Warnungen 0;
BA_ "GenSigSwitchedByIgnition" SG_ 810 EPS_Warnungen 0;
BA_ "GenSigSendType" SG_ 810 EPS_Zst_Offset_Geradeaus 0;
BA_ "GenSigStartValue" SG_ 810 EPS_Zst_Offset_Geradeaus 510;
BA_ "GenSigSwitchedByIgnition" SG_ 810 EPS_Zst_Offset_Geradeaus 0;
BA_ "Fehlerwert" SG_ 810 EPS_Zst_Offset_Geradeaus 511;
BA_REL_ "GenSigTimeoutTime" BU_SG_REL_ FASFrontradar SG_ 588 SWA_Blindheit_erkannt 500;
BA_REL_ "GenSigTimeoutTime" BU_SG_REL_ FASFrontradar SG_ 588 SWA_rel_Nichtverf 500;
BA_REL_ "GenSigTimeoutTime" BU_SG_REL_ FASFrontradar SG_ 588 SWA_rel_Fehler 500;
BA_REL_ "GenSigTimeoutTime" BU_SG_REL_ FASFrontradar SG_ 588 SWA_Blindheitsverdacht 500;
BA_REL_ "GenSigTimeoutTime" BU_SG_REL_ FASFrontradar SG_ 589 SWA_Infostufe_SWA_li 500;
BA_REL_ "GenSigTimeoutTime" BU_SG_REL_ FASFrontradar SG_ 589 SWA_Infostufe_SWA_re 500;
BA_REL_ "GenSigTimeoutTime" BU_SG_REL_ FASFrontradar SG_ 589 SWA_Warnung_SWA_li 500;
BA_REL_ "GenSigTimeoutTime" BU_SG_REL_ FASFrontradar SG_ 589 SWA_Warnung_SWA_re 500;
BA_REL_ "GenSigTimeoutTime" BU_SG_REL_ FASFrontradar SG_ 589 SWA_Obj_01_Gemessen 500;
BA_REL_ "GenSigTimeoutTime" BU_SG_REL_ FASFrontradar SG_ 589 SWA_Obj_01_ID 500;
BA_REL_ "GenSigTimeoutTime" BU_SG_REL_ FASFrontradar SG_ 589 SWA_Obj_02_Gemessen 500;
BA_REL_ "GenSigTimeoutTime" BU_SG_REL_ FASFrontradar SG_ 589 SWA_Obj_02_ID 500;
BA_REL_ "GenSigTimeoutTime" BU_SG_REL_ FASFrontradar SG_ 589 SWA_Obj_03_Gemessen 500;
BA_REL_ "GenSigTimeoutTime" BU_SG_REL_ FASFrontradar SG_ 589 SWA_Obj_03_ID 500;
BA_REL_ "GenSigTimeoutTime" BU_SG_REL_ FASFrontradar SG_ 589 SWA_Obj_04_Gemessen 500;
BA_REL_ "GenSigTimeoutTime" BU_SG_REL_ FASFrontradar SG_ 589 SWA_Obj_04_ID 500;
BA_REL_ "GenSigTimeoutTime" BU_SG_REL_ FASFrontradar SG_ 589 SWA_Obj_05_Gemessen 500;
BA_REL_ "GenSigTimeoutTime" BU_SG_REL_ FASFrontradar SG_ 589 SWA_Obj_05_ID 500;
BA_REL_ "GenSigTimeoutTime" BU_SG_REL_ FASFrontradar SG_ 589 SWA_Obj_06_Gemessen 500;
BA_REL_ "GenSigTimeoutTime" BU_SG_REL_ FASFrontradar SG_ 589 SWA_Obj_06_ID 500;
BA_REL_ "GenSigTimeoutTime" BU_SG_REL_ FASFrontradar SG_ 589 SWA_Obj_01_GeschwRelX 500;
BA_REL_ "GenSigTimeoutTime" BU_SG_REL_ FASFrontradar SG_ 589 SWA_Obj_01_PositionX 500;
BA_REL_ "GenSigTimeoutTime" BU_SG_REL_ FASFrontradar SG_ 589 SWA_Obj_01_PositionY 500;
BA_REL_ "GenSigTimeoutTime" BU_SG_REL_ FASFrontradar SG_ 589 SWA_Obj_02_GeschwRelX 500;
BA_REL_ "GenSigTimeoutTime" BU_SG_REL_ FASFrontradar SG_ 589 SWA_Obj_02_PositionX 500;
BA_REL_ "GenSigTimeoutTime" BU_SG_REL_ FASFrontradar SG_ 589 SWA_Obj_02_PositionY 500;
BA_REL_ "GenSigTimeoutTime" BU_SG_REL_ FASFrontradar SG_ 589 SWA_Obj_03_GeschwRelX 500;
BA_REL_ "GenSigTimeoutTime" BU_SG_REL_ FASFrontradar SG_ 589 SWA_Obj_03_PositionX 500;
BA_REL_ "GenSigTimeoutTime" BU_SG_REL_ FASFrontradar SG_ 589 SWA_Obj_03_PositionY 500;
BA_REL_ "GenSigTimeoutTime" BU_SG_REL_ FASFrontradar SG_ 589 SWA_Obj_04_GeschwRelX 500;
BA_REL_ "GenSigTimeoutTime" BU_SG_REL_ FASFrontradar SG_ 589 SWA_Obj_04_PositionX 500;
BA_REL_ "GenSigTimeoutTime" BU_SG_REL_ FASFrontradar SG_ 589 SWA_Obj_04_PositionY 500;
BA_REL_ "GenSigTimeoutTime" BU_SG_REL_ FASFrontradar SG_ 589 SWA_Obj_05_GeschwRelX 500;
BA_REL_ "GenSigTimeoutTime" BU_SG_REL_ FASFrontradar SG_ 589 SWA_Obj_05_PositionX 500;
BA_REL_ "GenSigTimeoutTime" BU_SG_REL_ FASFrontradar SG_ 589 SWA_Obj_05_PositionY 500;
BA_REL_ "GenSigTimeoutTime" BU_SG_REL_ FASFrontradar SG_ 589 SWA_Obj_06_GeschwRelX 500;
BA_REL_ "GenSigTimeoutTime" BU_SG_REL_ FASFrontradar SG_ 589 SWA_Obj_06_PositionX 500;
BA_REL_ "GenSigTimeoutTime" BU_SG_REL_ FASFrontradar SG_ 589 SWA_Obj_06_PositionY 500;
BA_REL_ "GenSigTimeoutTime" BU_SG_REL_ FASFrontradar SG_ 792 Kamera_Systemzustand 800;
BA_REL_ "GenSigTimeoutTime" BU_SG_REL_ FASFrontradar SG_ 960 Klemmen_Status_01_CRC 1000;
BA_REL_ "GenSigTimeoutTime" BU_SG_REL_ FASFrontradar SG_ 960 Klemmen_Status_01_BZ 1000;
BA_REL_ "GenSigTimeoutTime" BU_SG_REL_ FASFrontradar SG_ 960 ZAS_Kl_15 1000;
BA_REL_ "GenSigTimeoutTime" BU_SG_REL_ FASFrontradar SG_ 605 KLR_01_CRC 600;
BA_REL_ "GenSigTimeoutTime" BU_SG_REL_ FASFrontradar SG_ 605 KLR_01_BZ 600;
BA_REL_ "GenSigTimeoutTime" BU_SG_REL_ FASFrontradar SG_ 605 KLR_Touchintensitaet_1 600;
BA_REL_ "GenSigTimeoutTime" BU_SG_REL_ FASFrontradar SG_ 605 KLR_Touchauswertung 600;
BA_REL_ "GenSigTimeoutTime" BU_SG_REL_ ICAS1_X_Gateway SG_ 2589283730 Kamera_SDA_Geschw_Spur_R 5000;
BA_REL_ "GenSigTimeoutTime" BU_SG_REL_ ICAS1_X_Gateway SG_ 2589283730 Kamera_SDA_Geschw_Spur_L 5000;
BA_REL_ "GenSigTimeoutTime" BU_SG_REL_ ICAS1_X_Gateway SG_ 2589283730 Kamera_SDA_Geschw_Spur_E 5000;
BA_REL_ "GenSigTimeoutTime" BU_SG_REL_ ICAS1_X_Gateway SG_ 2589283730 Kamera_SDA_Abstand_Spur_E1 5000;
BA_REL_ "GenSigTimeoutTime" BU_SG_REL_ ICAS1_X_Gateway SG_ 2589283730 Kamera_SDA_Abstand_Spur_E2 5000;
BA_REL_ "GenSigTimeoutTime" BU_SG_REL_ ICAS1_X_Gateway SG_ 2589283730 Kamera_SDA_Abstand_Spur_L1 5000;
BA_REL_ "GenSigTimeoutTime" BU_SG_REL_ ICAS1_X_Gateway SG_ 2589283730 Kamera_SDA_Abstand_Spur_L2 5000;
BA_REL_ "GenSigTimeoutTime" BU_SG_REL_ ICAS1_X_Gateway SG_ 2589283730 Kamera_SDA_Abstand_Spur_R1 5000;
BA_REL_ "GenSigTimeoutTime" BU_SG_REL_ ICAS1_X_Gateway SG_ 2589283730 Kamera_SDA_Abstand_Spur_R2 5000;
BA_REL_ "GenSigTimeoutTime" BU_SG_REL_ ICAS1_X_Gateway SG_ 2589283730 Kamera_SDA_Eigenblendung 5000;
BA_REL_ "GenSigTimeoutTime" BU_SG_REL_ ICAS1_X_Gateway SG_ 2589283730 Kamera_SDA_Sichtweite 5000;
BA_REL_ "GenSigTimeoutTime" BU_SG_REL_ ICAS1_X_Gateway SG_ 2589283730 Kamera_SDA_Status_allg 5000;
BA_REL_ "GenSigTimeoutTime" BU_SG_REL_ ICAS1_X_Gateway SG_ 2589283730 Kamera_SDA_Status_Beleuchtung 5000;
BA_REL_ "GenSigTimeoutTime" BU_SG_REL_ ICAS1_X_Gateway SG_ 2549088343 ACC_Nachlauftyp 5000;
BA_REL_ "GenSigTimeoutTime" BU_SG_REL_ ICAS1_X_Gateway SG_ 2549088343 KN_ACC_DiagPfad 5000;
BA_REL_ "GenSigTimeoutTime" BU_SG_REL_ ICAS1_X_Gateway SG_ 2549088343 ACC_KD_Fehler 2500;
BA_REL_ "GenSigTimeoutTime" BU_SG_REL_ ICAS1_X_Gateway SG_ 2549088335 Kamera_Nachlauftyp 5000;
BA_REL_ "GenSigTimeoutTime" BU_SG_REL_ ICAS1_X_Gateway SG_ 2549088335 KN_Kamera_DiagPfad 5000;
BA_REL_ "GenSigTimeoutTime" BU_SG_REL_ ICAS1_X_Gateway SG_ 2549088335 Kamera_KD_Fehler 2500;
BA_REL_ "GenSigTimeoutTime" BU_SG_REL_ ICAS1_X_Gateway SG_ 2549088313 MIK_Nachlauftyp 5000;
BA_REL_ "GenSigTimeoutTime" BU_SG_REL_ ICAS1_X_Gateway SG_ 2549088313 KN_MIK_DiagPfad 5000;
BA_REL_ "GenSigTimeoutTime" BU_SG_REL_ ICAS1_X_Gateway SG_ 2549088313 MIK_KD_Fehler 2500;
BA_REL_ "GenSigTimeoutTime" BU_SG_REL_ ICAS1_X_Gateway SG_ 2549088443 NR_01_Nachlauftyp 5000;
BA_REL_ "GenSigTimeoutTime" BU_SG_REL_ ICAS1_X_Gateway SG_ 2549088443 NR_01_KD_Fehler 2500;
BA_REL_ "GenSigTimeoutTime" BU_SG_REL_ ICAS1_X_Gateway SG_ 2549088444 NR_02_Nachlauftyp 5000;
BA_REL_ "GenSigTimeoutTime" BU_SG_REL_ ICAS1_X_Gateway SG_ 2549088444 KN_NR_02_DiagPfad 5000;
BA_REL_ "GenSigTimeoutTime" BU_SG_REL_ ICAS1_X_Gateway SG_ 2549088444 NR_02_KD_Fehler 2500;
BA_REL_ "GenSigTimeoutTime" BU_SG_REL_ ICAS1_X_Gateway SG_ 919 LDW_Gong 1000;
BA_REL_ "GenSigTimeoutTime" BU_SG_REL_ ICAS1_X_Gateway SG_ 919 LDW_Texte 1000;
BA_REL_ "GenSigTimeoutTime" BU_SG_REL_ ICAS1_X_Gateway SG_ 919 LDW_Seite_DLCTLC 1000;
BA_REL_ "GenSigTimeoutTime" BU_SG_REL_ ICAS1_X_Gateway SG_ 919 LDW_Lernmodus_seitenabhaengig 1000;
BA_REL_ "GenSigTimeoutTime" BU_SG_REL_ ICAS1_X_Gateway SG_ 919 LDW_TLC 1000;
BA_REL_ "GenSigTimeoutTime" BU_SG_REL_ ICAS1_X_Gateway SG_ 919 LDW_Status_Grid 1000;
BA_REL_ "GenSigTimeoutTime" BU_SG_REL_ ICAS1_X_Gateway SG_ 919 LDW_Status_LED_gelb 1000;
BA_REL_ "GenSigTimeoutTime" BU_SG_REL_ ICAS1_X_Gateway SG_ 919 LDW_Status_LED_gruen 1000;
BA_REL_ "GenSigTimeoutTime" BU_SG_REL_ MFK SG_ 588 SWA_Status 500;
BA_REL_ "GenSigTimeoutTime" BU_SG_REL_ MFK SG_ 588 SWA_Blindheit_erkannt 500;
BA_REL_ "GenSigTimeoutTime" BU_SG_REL_ MFK SG_ 588 SWA_rel_Nichtverf 500;
BA_REL_ "GenSigTimeoutTime" BU_SG_REL_ MFK SG_ 588 SWA_rel_Fehler 500;
BA_REL_ "GenSigTimeoutTime" BU_SG_REL_ MFK SG_ 588 SWA_Sta_aktiv 500;
BA_REL_ "GenSigTimeoutTime" BU_SG_REL_ MFK SG_ 588 SWA_Sta_passiv 500;
BA_REL_ "GenSigTimeoutTime" BU_SG_REL_ MFK SG_ 588 SWA_Modus 500;
BA_REL_ "GenSigTimeoutTime" BU_SG_REL_ MFK SG_ 588 SWA_Gischtzaehler 500;
BA_REL_ "GenSigTimeoutTime" BU_SG_REL_ MFK SG_ 588 SWA_Blindheitsverdacht 500;
BA_REL_ "GenSigTimeoutTime" BU_SG_REL_ MFK SG_ 589 SWA_StrukturLinks_querAbstand 500;
BA_REL_ "GenSigTimeoutTime" BU_SG_REL_ MFK SG_ 589 SWA_StrukturLinks_Typ 500;
BA_REL_ "GenSigTimeoutTime" BU_SG_REL_ MFK SG_ 589 SWA_Umfeld_Zeitstempel 500;
BA_REL_ "GenSigTimeoutTime" BU_SG_REL_ MFK SG_ 589 SWA_Umfeld_Zeitstempel_Status 500;
BA_REL_ "GenSigTimeoutTime" BU_SG_REL_ MFK SG_ 589 SWA_Kolonne_li 500;
BA_REL_ "GenSigTimeoutTime" BU_SG_REL_ MFK SG_ 589 SWA_Kolonne_mi 500;
BA_REL_ "GenSigTimeoutTime" BU_SG_REL_ MFK SG_ 589 SWA_Kolonne_re 500;
BA_REL_ "GenSigTimeoutTime" BU_SG_REL_ MFK SG_ 589 SWA_Infostufe_SWA_li 500;
BA_REL_ "GenSigTimeoutTime" BU_SG_REL_ MFK SG_ 589 SWA_Infostufe_SWA_re 500;
BA_REL_ "GenSigTimeoutTime" BU_SG_REL_ MFK SG_ 589 SWA_Warnung_SWA_li 500;
BA_REL_ "GenSigTimeoutTime" BU_SG_REL_ MFK SG_ 589 SWA_Warnung_SWA_re 500;
BA_REL_ "GenSigTimeoutTime" BU_SG_REL_ MFK SG_ 589 SWA_Obj_Kurvenradius 500;
BA_REL_ "GenSigTimeoutTime" BU_SG_REL_ MFK SG_ 589 SWA_StrukturRechts_querAbstand 500;
BA_REL_ "GenSigTimeoutTime" BU_SG_REL_ MFK SG_ 589 SWA_StrukturRechts_Typ 500;
BA_REL_ "GenSigTimeoutTime" BU_SG_REL_ MFK SG_ 589 SWA_Obj_01_Gemessen 500;
BA_REL_ "GenSigTimeoutTime" BU_SG_REL_ MFK SG_ 589 SWA_Obj_01_ID 500;
BA_REL_ "GenSigTimeoutTime" BU_SG_REL_ MFK SG_ 589 SWA_Obj_02_Gemessen 500;
BA_REL_ "GenSigTimeoutTime" BU_SG_REL_ MFK SG_ 589 SWA_Obj_02_ID 500;
BA_REL_ "GenSigTimeoutTime" BU_SG_REL_ MFK SG_ 589 SWA_Obj_03_Gemessen 500;
BA_REL_ "GenSigTimeoutTime" BU_SG_REL_ MFK SG_ 589 SWA_Obj_03_ID 500;
BA_REL_ "GenSigTimeoutTime" BU_SG_REL_ MFK SG_ 589 SWA_Obj_04_Gemessen 500;
BA_REL_ "GenSigTimeoutTime" BU_SG_REL_ MFK SG_ 589 SWA_Obj_04_ID 500;
BA_REL_ "GenSigTimeoutTime" BU_SG_REL_ MFK SG_ 589 SWA_Obj_05_Gemessen 500;
BA_REL_ "GenSigTimeoutTime" BU_SG_REL_ MFK SG_ 589 SWA_Obj_05_ID 500;
BA_REL_ "GenSigTimeoutTime" BU_SG_REL_ MFK SG_ 589 SWA_Obj_06_Gemessen 500;
BA_REL_ "GenSigTimeoutTime" BU_SG_REL_ MFK SG_ 589 SWA_Obj_06_ID 500;
BA_REL_ "GenSigTimeoutTime" BU_SG_REL_ MFK SG_ 589 SWA_Obj_01_GeschwRelX 500;
BA_REL_ "GenSigTimeoutTime" BU_SG_REL_ MFK SG_ 589 SWA_Obj_01_Breite 500;
BA_REL_ "GenSigTimeoutTime" BU_SG_REL_ MFK SG_ 589 SWA_Obj_01_GeschwRelY 500;
BA_REL_ "GenSigTimeoutTime" BU_SG_REL_ MFK SG_ 589 SWA_Obj_01_Existenzwahrsch 500;
BA_REL_ "GenSigTimeoutTime" BU_SG_REL_ MFK SG_ 589 SWA_Obj_01_Objektklasse 500;
BA_REL_ "GenSigTimeoutTime" BU_SG_REL_ MFK SG_ 589 SWA_Obj_01_ReferenzPkt 500;
BA_REL_ "GenSigTimeoutTime" BU_SG_REL_ MFK SG_ 589 SWA_Obj_01_PositionX 500;
BA_REL_ "GenSigTimeoutTime" BU_SG_REL_ MFK SG_ 589 SWA_Obj_01_Laenge 500;
BA_REL_ "GenSigTimeoutTime" BU_SG_REL_ MFK SG_ 589 SWA_Obj_01_PositionY 500;
BA_REL_ "GenSigTimeoutTime" BU_SG_REL_ MFK SG_ 589 SWA_Obj_02_GeschwRelX 500;
BA_REL_ "GenSigTimeoutTime" BU_SG_REL_ MFK SG_ 589 SWA_Obj_02_Breite 500;
BA_REL_ "GenSigTimeoutTime" BU_SG_REL_ MFK SG_ 589 SWA_Obj_02_GeschwRelY 500;
BA_REL_ "GenSigTimeoutTime" BU_SG_REL_ MFK SG_ 589 SWA_Obj_02_Existenzwahrsch 500;
BA_REL_ "GenSigTimeoutTime" BU_SG_REL_ MFK SG_ 589 SWA_Obj_02_Objektklasse 500;
BA_REL_ "GenSigTimeoutTime" BU_SG_REL_ MFK SG_ 589 SWA_Obj_02_ReferenzPkt 500;
BA_REL_ "GenSigTimeoutTime" BU_SG_REL_ MFK SG_ 589 SWA_Obj_02_PositionX 500;
BA_REL_ "GenSigTimeoutTime" BU_SG_REL_ MFK SG_ 589 SWA_Obj_02_Laenge 500;
BA_REL_ "GenSigTimeoutTime" BU_SG_REL_ MFK SG_ 589 SWA_Obj_02_PositionY 500;
BA_REL_ "GenSigTimeoutTime" BU_SG_REL_ MFK SG_ 589 SWA_Obj_03_GeschwRelX 500;
BA_REL_ "GenSigTimeoutTime" BU_SG_REL_ MFK SG_ 589 SWA_Obj_03_Breite 500;
BA_REL_ "GenSigTimeoutTime" BU_SG_REL_ MFK SG_ 589 SWA_Obj_03_GeschwRelY 500;
BA_REL_ "GenSigTimeoutTime" BU_SG_REL_ MFK SG_ 589 SWA_Obj_03_Existenzwahrsch 500;
BA_REL_ "GenSigTimeoutTime" BU_SG_REL_ MFK SG_ 589 SWA_Obj_03_Objektklasse 500;
BA_REL_ "GenSigTimeoutTime" BU_SG_REL_ MFK SG_ 589 SWA_Obj_03_ReferenzPkt 500;
BA_REL_ "GenSigTimeoutTime" BU_SG_REL_ MFK SG_ 589 SWA_Obj_03_PositionX 500;
BA_REL_ "GenSigTimeoutTime" BU_SG_REL_ MFK SG_ 589 SWA_Obj_03_Laenge 500;
BA_REL_ "GenSigTimeoutTime" BU_SG_REL_ MFK SG_ 589 SWA_Obj_03_PositionY 500;
BA_REL_ "GenSigTimeoutTime" BU_SG_REL_ MFK SG_ 589 SWA_Obj_04_GeschwRelX 500;
BA_REL_ "GenSigTimeoutTime" BU_SG_REL_ MFK SG_ 589 SWA_Obj_04_Breite 500;
BA_REL_ "GenSigTimeoutTime" BU_SG_REL_ MFK SG_ 589 SWA_Obj_04_GeschwRelY 500;
BA_REL_ "GenSigTimeoutTime" BU_SG_REL_ MFK SG_ 589 SWA_Obj_04_Existenzwahrsch 500;
BA_REL_ "GenSigTimeoutTime" BU_SG_REL_ MFK SG_ 589 SWA_Obj_04_Objektklasse 500;
BA_REL_ "GenSigTimeoutTime" BU_SG_REL_ MFK SG_ 589 SWA_Obj_04_ReferenzPkt 500;
BA_REL_ "GenSigTimeoutTime" BU_SG_REL_ MFK SG_ 589 SWA_Obj_04_PositionX 500;
BA_REL_ "GenSigTimeoutTime" BU_SG_REL_ MFK SG_ 589 SWA_Obj_04_Laenge 500;
BA_REL_ "GenSigTimeoutTime" BU_SG_REL_ MFK SG_ 589 SWA_Obj_04_PositionY 500;
BA_REL_ "GenSigTimeoutTime" BU_SG_REL_ MFK SG_ 589 SWA_Obj_05_GeschwRelX 500;
BA_REL_ "GenSigTimeoutTime" BU_SG_REL_ MFK SG_ 589 SWA_Obj_05_Breite 500;
BA_REL_ "GenSigTimeoutTime" BU_SG_REL_ MFK SG_ 589 SWA_Obj_05_GeschwRelY 500;
BA_REL_ "GenSigTimeoutTime" BU_SG_REL_ MFK SG_ 589 SWA_Obj_05_Existenzwahrsch 500;
BA_REL_ "GenSigTimeoutTime" BU_SG_REL_ MFK SG_ 589 SWA_Obj_05_Objektklasse 500;
BA_REL_ "GenSigTimeoutTime" BU_SG_REL_ MFK SG_ 589 SWA_Obj_05_ReferenzPkt 500;
BA_REL_ "GenSigTimeoutTime" BU_SG_REL_ MFK SG_ 589 SWA_Obj_05_PositionX 500;
BA_REL_ "GenSigTimeoutTime" BU_SG_REL_ MFK SG_ 589 SWA_Obj_05_Laenge 500;
BA_REL_ "GenSigTimeoutTime" BU_SG_REL_ MFK SG_ 589 SWA_Obj_05_PositionY 500;
BA_REL_ "GenSigTimeoutTime" BU_SG_REL_ MFK SG_ 589 SWA_Obj_06_GeschwRelX 500;
BA_REL_ "GenSigTimeoutTime" BU_SG_REL_ MFK SG_ 589 SWA_Obj_06_Breite 500;
BA_REL_ "GenSigTimeoutTime" BU_SG_REL_ MFK SG_ 589 SWA_Obj_06_GeschwRelY 500;
BA_REL_ "GenSigTimeoutTime" BU_SG_REL_ MFK SG_ 589 SWA_Obj_06_Existenzwahrsch 500;
BA_REL_ "GenSigTimeoutTime" BU_SG_REL_ MFK SG_ 589 SWA_Obj_06_Objektklasse 500;
BA_REL_ "GenSigTimeoutTime" BU_SG_REL_ MFK SG_ 589 SWA_Obj_06_ReferenzPkt 500;
BA_REL_ "GenSigTimeoutTime" BU_SG_REL_ MFK SG_ 589 SWA_Obj_06_PositionX 500;
BA_REL_ "GenSigTimeoutTime" BU_SG_REL_ MFK SG_ 589 SWA_Obj_06_Laenge 500;
BA_REL_ "GenSigTimeoutTime" BU_SG_REL_ MFK SG_ 589 SWA_Obj_06_PositionY 500;
BA_REL_ "GenSigTimeoutTime" BU_SG_REL_ MFK SG_ 2463978813 HVL_Steckerstatus 1000;
BA_REL_ "GenSigTimeoutTime" BU_SG_REL_ MFK SG_ 1524 IL_Innenlicht_aktiv 5000;
BA_REL_ "GenSigTimeoutTime" BU_SG_REL_ MFK SG_ 960 Klemmen_Status_01_CRC 1000;
BA_REL_ "GenSigTimeoutTime" BU_SG_REL_ MFK SG_ 960 Klemmen_Status_01_BZ 1000;
BA_REL_ "GenSigTimeoutTime" BU_SG_REL_ MFK SG_ 960 ZAS_Kl_S 1000;
BA_REL_ "GenSigTimeoutTime" BU_SG_REL_ MFK SG_ 960 ZAS_Kl_15 1000;
BA_REL_ "GenSigTimeoutTime" BU_SG_REL_ MFK SG_ 960 ZAS_Kl_50_Startanforderung 1000;
BA_REL_ "GenSigTimeoutTime" BU_SG_REL_ MFK SG_ 1640 KL_Beschlagsgefahr 2000;
BA_REL_ "GenSigTimeoutTime" BU_SG_REL_ MFK SG_ 605 KLR_Fehler 600;
BA_REL_ "GenSigTimeoutTime" BU_SG_REL_ MFK SG_ 605 KLR_ResponseError 600;
BA_REL_ "GenSigTimeoutTime" BU_SG_REL_ MFK SG_ 605 KLR_Touchintensitaet_1 600;
BA_REL_ "GenSigTimeoutTime" BU_SG_REL_ MFK SG_ 605 KLR_Touchintensitaet_2 600;
BA_REL_ "GenSigTimeoutTime" BU_SG_REL_ MFK SG_ 605 KLR_Touchintensitaet_3 600;
BA_REL_ "GenSigTimeoutTime" BU_SG_REL_ MFK SG_ 605 KLR_Touchauswertung 600;
BA_REL_ "GenSigTimeoutTime" BU_SG_REL_ MFK SG_ 810 EPS_VZ_Zst_Offset_Geradeaus 500;
BA_REL_ "GenSigTimeoutTime" BU_SG_REL_ MFK SG_ 810 EPS_Zst_Offset_Geradeaus 500;
BA_REL_ "GenSigTimeoutTime" BU_SG_REL_ MFK120 SG_ 588 SWA_Status_System 500;
BA_REL_ "GenSigTimeoutTime" BU_SG_REL_ MFK120 SG_ 588 SWA_Status_KuFu 500;
BA_REL_ "GenSigTimeoutTime" BU_SG_REL_ MFK120 SG_ 589 SWA_Infostufe_SWA_li 500;
BA_REL_ "GenSigTimeoutTime" BU_SG_REL_ MFK120 SG_ 589 SWA_Infostufe_SWA_re 500;
BA_REL_ "GenSigTimeoutTime" BU_SG_REL_ MFK120 SG_ 589 SWA_Warnung_SWA_li 500;
BA_REL_ "GenSigTimeoutTime" BU_SG_REL_ MFK120 SG_ 589 SWA_Warnung_SWA_re 500;
BA_REL_ "GenSigTimeoutTime" BU_SG_REL_ MFK120 SG_ 2463978813 HVL_Steckerstatus 1000;
BA_REL_ "GenSigTimeoutTime" BU_SG_REL_ MFK120 SG_ 960 Klemmen_Status_01_CRC 1000;
BA_REL_ "GenSigTimeoutTime" BU_SG_REL_ MFK120 SG_ 960 Klemmen_Status_01_BZ 1000;
BA_REL_ "GenSigTimeoutTime" BU_SG_REL_ MFK120 SG_ 960 ZAS_Kl_S 1000;
BA_REL_ "GenSigTimeoutTime" BU_SG_REL_ MFK120 SG_ 960 ZAS_Kl_15 1000;
BA_REL_ "GenSigTimeoutTime" BU_SG_REL_ MFK120 SG_ 960 ZAS_Kl_50_Startanforderung 1000;
BA_REL_ "GenSigTimeoutTime" BU_SG_REL_ MFK120 SG_ 1640 KL_Beschlagsgefahr 2000;
BA_REL_ "GenSigTimeoutTime" BU_SG_REL_ MFK120 SG_ 1505 BCM1_FStatus_Aussentemp_ungef 2000;
BA_REL_ "GenSigTimeoutTime" BU_SG_REL_ MFK120 SG_ 605 KLR_Fehler 600;
BA_REL_ "GenSigTimeoutTime" BU_SG_REL_ MFK120 SG_ 605 KLR_Touchintensitaet_1 600;
BA_REL_ "GenSigTimeoutTime" BU_SG_REL_ MFK120 SG_ 605 KLR_Touchintensitaet_2 600;
BA_REL_ "GenSigTimeoutTime" BU_SG_REL_ MFK120 SG_ 605 KLR_Touchintensitaet_3 600;
BA_REL_ "GenSigTimeoutTime" BU_SG_REL_ MFK120 SG_ 605 KLR_Touchauswertung 600;
BA_REL_ "GenSigTimeoutTime" BU_SG_REL_ MFK120 SG_ 810 EPS_VZ_Zst_Offset_Geradeaus 500;
BA_REL_ "GenSigTimeoutTime" BU_SG_REL_ MFK120 SG_ 810 EPS_Zst_Offset_Geradeaus 500;
BA_REL_ "GenSigTimeoutTime" BU_SG_REL_ MIK SG_ 2463978891 ICV_Switch_FieldOfView 1000;
BA_REL_ "GenSigTimeoutTime" BU_SG_REL_ MIK SG_ 2463978891 ICV_Switch_FunctionState 1000;
BA_REL_ "GenSigTimeoutTime" BU_SG_REL_ MIK SG_ 2463978891 ICV_Switch_Brightness 1000;
BA_REL_ "GenSigTimeoutTime" BU_SG_REL_ MIK SG_ 2463978891 PetsMode_Enable 1000;
BA_REL_ "GenSigTimeoutTime" BU_SG_REL_ MIK SG_ 2463978891 ICV_Switch_Resolution 1000;
BA_REL_ "GenSigTimeoutTime" BU_SG_REL_ MIK SG_ 2463978891 ICV_Switch_FrameRate 1000;
BA_REL_ "GenSigTimeoutTime" BU_SG_REL_ MIK SG_ 2463978891 ICV_Switch_ColorMode 1000;
BA_REL_ "GenSigTimeoutTime" BU_SG_REL_ MIK SG_ 2463978891 ICV_Switch_HDR 1000;
BA_REL_ "GenSigTimeoutTime" BU_SG_REL_ MIK SG_ 2463978891 ICV_Switch_Contrast 1000;
BA_REL_ "GenSigTimeoutTime" BU_SG_REL_ MIK SG_ 2463978891 Selfie_Switch_FunctionState 1000;
BA_REL_ "GenSigTimeoutTime" BU_SG_REL_ MIK SG_ 2463978891 Selfie_Switch_Resolution 1000;
BA_REL_ "GenSigTimeoutTime" BU_SG_REL_ MIK SG_ 2463978891 ICV_Switch_AspectRatio 1000;
BA_REL_ "GenSigTimeoutTime" BU_SG_REL_ MIK SG_ 2463978891 ICV_Switch_VideoLength 1000;
BA_REL_ "GenSigTimeoutTime" BU_SG_REL_ MIK SG_ 2463978891 CabinCare_Enable 1000;
BA_REL_ "GenSigTimeoutTime" BU_SG_REL_ MIK SG_ 1524 IL_Innenlicht_aktiv 5000;
BA_REL_ "GenSigTimeoutTime" BU_SG_REL_ MIK SG_ 960 ZAS_Kl_15 1000;
BA_REL_ "GenSigTimeoutTime" BU_SG_REL_ MRR2023 SG_ 588 SWA_Modus_System 500;
BA_REL_ "GenSigTimeoutTime" BU_SG_REL_ MRR2023 SG_ 589 SWA_Obj_04_ID 500;
BA_REL_ "GenSigTimeoutTime" BU_SG_REL_ MRR2023 SG_ 792 Kamera_Systemzustand 800;
BA_REL_ "GenSigTimeoutTime" BU_SG_REL_ MRR2023 SG_ 960 Klemmen_Status_01_CRC 1000;
BA_REL_ "GenSigTimeoutTime" BU_SG_REL_ MRR2023 SG_ 960 Klemmen_Status_01_BZ 1000;
BA_REL_ "GenSigTimeoutTime" BU_SG_REL_ MRR2023 SG_ 960 ZAS_Kl_15 1000;
BA_REL_ "GenSigTimeoutTime" BU_SG_REL_ MRR2023 SG_ 605 KLR_01_CRC 600;
BA_REL_ "GenSigTimeoutTime" BU_SG_REL_ MRR2023 SG_ 605 KLR_01_BZ 600;
BA_REL_ "GenSigTimeoutTime" BU_SG_REL_ MRR2023 SG_ 605 KLR_Touchintensitaet_1 600;
BA_REL_ "GenSigTimeoutTime" BU_SG_REL_ MRR2023 SG_ 605 KLR_Touchauswertung 600;
VAL_ 588 SWA_LED_Hell_BFS 126 "Init" 127 "Fehler" ;
VAL_ 588 SWA_LED_Hell_FS 126 "Init" 127 "Fehler" ;
VAL_ 588 SWA_LED_Ausgabemodus_BFS 0 "LED_aus" 1 "Infostufe" 2 "Warnstufe" 3 "Aufpruefen_SWAABAHeck_ASW" 4 "Aufpruefen_SWAABAHeck" 5 "Demolauf" ;
VAL_ 588 SWA_LED_Ausgabemodus_FS 0 "LED_aus" 1 "Infostufe" 2 "Warnstufe" 3 "Aufpruefen_SWAABAHeck_ASW" 4 "Aufpruefen_SWAABAHeck" 5 "Demolauf" ;
VAL_ 588 SWA_Status 0 "aus" 1 "passiv" 2 "aktiv" 3 "Fehler" ;
VAL_ 588 ASW_Ton_Richtung_VL 0 "kein_Warnton" 1 "Warnton" ;
VAL_ 588 ASW_Ton_Richtung_VR 0 "kein_Warnton" 1 "Warnton" ;
VAL_ 588 ASW_Ton_Richtung_HL 0 "kein_Warnton" 1 "Warnton" ;
VAL_ 588 ASW_Ton_Richtung_HR 0 "kein_Warnton" 1 "Warnton" ;
VAL_ 588 SWA_Status_System 0 "aus" 1 "passiv" 2 "aktiv" 3 "Fehler" ;
VAL_ 588 SWA_Brightness_Mode_FPM 0 "Init" 1 "No_error" 2 "Trailer_active" 3 "Muted_by_driver" 4 "Blind" 5 "not_selectable" 6 "not_available" 7 "Privacy_Mode" 8 "No_License" 9 "License_expired" 14 "Temporary_error" 15 "Fehler" ;
VAL_ 588 SWA_Status_KuFu 0 "aus" 1 "passiv" 2 "aktiv" 3 "Fehler" ;
VAL_ 588 SWA_Infostufe_Assist_li 0 "keine_Infostufe" 1 "Infostufe_aktiv" ;
VAL_ 588 SWA_Infostufe_Assist_re 0 "keine_Infostufe" 1 "Infostufe_aktiv" ;
VAL_ 588 SWA_Warnstufe_Assist_li 0 "keine_Warnstufe" 1 "Warnstufe_aktiv" ;
VAL_ 588 SWA_Warnstufe_Assist_re 0 "keine_Warnstufe" 1 "Warnstufe_aktiv" ;
VAL_ 588 SWA_Modus_System 0 "nicht_verfuegbar" 1 "verfuegbar" 2 "Anhaengerbetrieb" 3 "eingeschraenkte_Sensorsicht" 4 "keine_Sensorsicht" 5 "reserved" 6 "temporaerer_Fehler" 7 "dauerhafter_Fehler" ;
VAL_ 588 SWA_Kombiausgabe 0 "Keine_Anzeige" 1 "zur_Zeit_nicht_verfuegbar" 2 "Systemfehler" 3 "Sensor_blockiert" 4 "Anhaengerbetrb_nicht_verfuegbar" 5 "Sensor_teilweise_blockiert" ;
VAL_ 588 ASW_Kombiausgabe 0 "Keine_Anzeige" 1 "zur_Zeit_nicht_verfuegbar" 2 "Systemfehler" 3 "Sensor_blockiert" 4 "Anhaengerbetrb_nicht_verfuegbar" ;
VAL_ 588 ASW_Ausgabemodus_HBFS 0 "keine_Ausgabe" 1 "Infostufe" 2 "Infostufe_ohne_Tueraktion" 3 "Warnstufe_ohne_Ton" 4 "Warnstufe_mit_Ton" 5 "Aufpruefen" ;
VAL_ 588 ASW_Ausgabemodus_HFS 0 "keine_Ausgabe" 1 "Infostufe" 2 "Infostufe_ohne_Tueraktion" 3 "Warnstufe_ohne_Ton" 4 "Warnstufe_mit_Ton" 5 "Aufpruefen" ;
VAL_ 588 ASW_Akustik_Einstellung 0 "Aus" 1 "Ein" ;
VAL_ 588 SWA_Anzeigen 0 "keine_Anzeige" 1 "Text_1_SWA_zurzeit_nicht_verfuegbar" 2 "Text_2_SWA_Systemstoerung" 3 "Text_3_SWA_zurzeit_nicht_verfuegbar_Keine_Sensorsicht" 4 "Text_4_SWA_zurzeit_nicht_verfuegbar_Anhaengerbetrieb" 5 "Text_5_SWA_Eskalation" 6 "Text_6_SWA_eingeschränkt" ;
VAL_ 588 SWA_Blindheit_erkannt 0 "nicht erkannt" 1 "erkannt" ;
VAL_ 588 SWA_rel_Nichtverf 0 "verfuegbar" 1 "nicht verfuegbar" ;
VAL_ 588 SWA_rel_Fehler 0 "kein Fehler" 1 "Fehler" ;
VAL_ 588 SWA_Sta_aktiv 0 "Aus" 1 "Ein" ;
VAL_ 588 SWA_Sta_passiv 0 "Aus" 1 "Ein" ;
VAL_ 588 SWA_FT_RueckLED 0 "inaktiv" 1 "aktiv" ;
VAL_ 588 ASW_Status 0 "Passiv" 1 "Aktiv" 2 "Fehler" 3 "AUS" ;
VAL_ 588 SWA_Standziele_li 0 "Abstand i.O." 1 "Abstand zu gering" ;
VAL_ 588 ASW_Ausgabemodus_BFS 0 "keine_Ausgabe" 1 "Infostufe" 2 "Infostufe_ohne_Tueraktion" 3 "Warnstufe_ohne_Ton" 4 "Warnstufe_mit_Ton" 5 "Aufpruefen" ;
VAL_ 588 ASW_Warnung_FS 0 "inaktiv" 1 "aktiv" ;
VAL_ 588 ASW_Warnung_BFS 0 "inaktiv" 1 "aktiv" ;
VAL_ 588 ASW_Kombitexte 0 "keine Anzeige.    //    Prio 5" 1 "Text_1_ASW_zur_Zeit_nicht_verfuegbar_und_Akustik    //    Prio 2" 2 "Text_2_ASW_Systemfehler_und_Akustik    //    Prio 1" 3 "Text_3_ASW_Sensor_blockiert_und_Akustik    //    Prio 3" 4 "Text_4_ASW_im_Anhaengerbetrieb_nicht_verfuegbar_und_Akustik    //    Prio 4" 5 "Text_5_ASW_Warnung_FS_und_Akustik" 6 "Text_6_ASW_Warnung_BFS_und_Akustik" 7 "Text_7_ASW_aus" ;
VAL_ 588 ASW_Modus 0 "kein_Fehler_KL15" 1 "kein_Fehler_KL30" 2 "reserve" 3 "Anhaengerbetrieb" 4 "Init_nicht_codiert" 5 "keine_Sensorsicht_blindheit" 6 "Zur_zeit_nicht_verfuegbar_temp_Fehler" 7 "Systemstoerung_dauer_fehler" ;
VAL_ 588 SWA_Modus 0 "kein_Fehler_verfuegbar" 1 "kein_Fehler_eingeschr_Reichweite" 2 "reserve" 3 "Anhaengerbetrieb" 4 "Init_nicht_codiert" 5 "keine_Sensorsicht_blindheit" 6 "Zur_zeit_nicht_verfuegbar_temp_Fehler" 7 "Systemstoerung_dauer_fehler" ;
VAL_ 588 SWA_Standziele_re 0 "Abstand i.O." 1 "Abstand zu gering" ;
VAL_ 588 ASW_Ausgabemodus_FS 0 "keine_Ausgabe" 1 "Infostufe" 2 "Infostufe_ohne_Tueraktion" 3 "Warnstufe_ohne_Ton" 4 "Warnstufe_mit_Ton" 5 "Aufpruefen" ;
VAL_ 588 HRE_Anzeigetexte 0 "keine_Anzeige" 1 "BSD_RTA_zZt_nicht_verfuegbar" 2 "BSD_RTA_Systemfehler" 3 "BSD_RTA_Sensor_blockiert" 4 "BSD_RTA_Anhaengerbetrieb" 5 "RTA_Warnung" 6 "BSD_Warnung" 7 "Fahreruebernahme_Notbremsung" 8 "RTA_nicht_verfuegbar" 9 "BSD_RTA_ASW_zZt_nicht_verfuegbar" 10 "BSD_RTA_ASW_Systemfehler" 11 "BSD_RTA_ASW_Sensor_blockiert" 12 "BSD_RTA_ASW_Anhaengerbetrieb" ;
VAL_ 588 SWA_Blindheitsverdacht 0 "kein_Blindheitsverdacht_erkannt" 1 "Blindheitsverdacht_erkannt" ;
VAL_ 588 Heckradar_Kombitexte 0 "keine Anzeige.    //    Prio 5" 1 "Text_1_SWA_und_ASW_zur_Zeit_nicht_verfuegbar_und_Akustik    //    Prio 2" 2 "Text_2_SWA_und_ASW_Systemfehler_und_Akustik    //    Prio 1" 3 "Text_3_SWA_und_ASW_Sensor_blockiert_und_Akustik    //    Prio 3" 4 "Text_4_SWA_und_ASW_im_Anhaengerbetrieb_nicht_verfuegbar_und_Akustik    //    Prio 4" 5 "Text_1_SWA_und_RCTA_zur_Zeit_nicht_verfuegbar_und_Akustik // Prio 2" 6 "Text_2_SWA_und_RCTA_Systemfehler_und_Akustik // Prio 1" 7 "		Text_3_SWA_und_RCTA_Sensor_blockiert_und_Akustik // Prio 3" 8 "Text_4_SWA_und_RCTA_im_Anhaengerbetrieb_nicht_verfuegbar_und_Akustik // Prio 4" 9 "Text_1_ASW_und_RCTA_zur_Zeit_nicht_verfuegbar_und_Akustik // Prio 2" 10 "Text_2_ASW_und_RCTA_Systemfehler_und_Akustik // Prio 1" 11 "Text_3_ASW_und_RCTA_Sensor_blockiert_und_Akustik // Prio 3" 12 "Text_4_ASW_und_RCTA_im_Anhaengerbetrieb_nicht_verfuegbar_und_Akustik // Prio 4" 13 "Text_1_SWA_und_ASW_und_RCTA_zur_Zeit_nicht_verfuegbar_und_Akustik // Prio 2" 14 "Text_2_SWA_und_ASW_und_RCTA_Systemfehler_und_Akustik // Prio 1" 15 "Text_3_SWA_und_ASW_und_RCTA_Sensor_blockiert_und_Akustik // Prio 3" 16 "Text_4_SWA_und_ASW_und_RCTA_im_Anhaengerbetrieb_nicht_verfuegbar_und_Akustik // Prio 4" 17 "reserviert" 18 "reserviert" 19 "reserviert" 20 "reserviert" 21 "reserviert" 22 "reserviert" 23 "reserviert" 24 "reserviert" 25 "reserviert" 26 "reserviert" 27 "reserviert" 28 "reserviert" 29 "reserviert" ;
VAL_ 588 RCTA_Kombitexte 0 "keine_Anzeige" 1 "RCTA_zur_Zeit_nicht_verfuegbar" 2 "RCTA_Systemfehler" 3 "RCTA_Sensor_blockiert" 4 "RCTA_im_Anhaengerbetrieb" 5 "RTA_Warnung" 6 "Fahreruebernahme_Notbremsung" 7 "Eingeschraenkt_verfuegbar_ESCaus" ;
VAL_ 589 SWA_StrukturLinks_querAbstand 511 "Init" ;
VAL_ 589 SWA_StrukturLinks_Typ 0 "inaktiv" 1 "durchgehend_baulich" 2 "verkettet_baulich" 3 "unregelmaessig_oder_unbekannt" 4 "punktfoermig" 5 "verdeckt" 6 "frei" ;
VAL_ 589 SWA_Umfeld_Zeitstempel_Status 0 "reserved" 1 "Zeitstempel_PLT_synchro" 2 "Zeitstempel_Datenalter" 3 "reserved" 4 "Fehler_Sync_fehlerhaft" 5 "reserved" 6 "reserved" 7 "init" ;
VAL_ 589 SWA_Kolonne_li 0 "zwei_oder_weniger_Fahrzeuge_auf_der_Spur" 1 "mehr_als_zwei_Fahrzeuge_auf_der_Spur" ;
VAL_ 589 SWA_Kolonne_mi 0 "zwei_oder_weniger_Fahrzeuge_auf_der_Spur" 1 "mehr_als_zwei_Fahrzeuge_auf_der_Spur" ;
VAL_ 589 SWA_Kolonne_re 0 "zwei_oder_weniger_Fahrzeuge_auf_der_Spur" 1 "mehr_als_zwei_Fahrzeuge_auf_der_Spur" ;
VAL_ 589 SWA_Infostufe_SWA_li 0 "keine_Aktion" 1 "Aktion" ;
VAL_ 589 SWA_Infostufe_SWA_re 0 "keine_Aktion" 1 "Aktion" ;
VAL_ 589 SWA_Warnung_SWA_li 0 "keine Warnung" 1 "Warnung aktiv" ;
VAL_ 589 SWA_Warnung_SWA_re 0 "keine Warnung" 1 "Warnung aktiv" ;
VAL_ 589 SWA_Obj_Kurvenradius 65535 "Init" ;
VAL_ 589 SWA_StrukturRechts_querAbstand 511 "Init" ;
VAL_ 589 SWA_StrukturRechts_Typ 0 "inaktiv" 1 "durchgehend_baulich" 2 "verkettet_baulich" 3 "unregelmaessig_oder_unbekannt" 4 "punktfoermig" 5 "verdeckt" 6 "frei" ;
VAL_ 589 SWA_Obj_01_Gemessen 0 "ObjektpositionY_geschaetzt" 1 "ObjektpositionY_bestaetigt" ;
VAL_ 589 SWA_Obj_01_ID 0 "kein_Objekt_enthalten" 31 "Init" ;
VAL_ 589 SWA_Obj_02_Gemessen 0 "ObjektpositionY_geschaetzt" 1 "ObjektpositionY_bestaetigt" ;
VAL_ 589 SWA_Obj_02_ID 0 "kein_Objekt_enthalten" 31 "Init" ;
VAL_ 589 SWA_Obj_03_Gemessen 0 "ObjektpositionY_geschaetzt" 1 "ObjektpositionY_bestaetigt" ;
VAL_ 589 SWA_Obj_03_ID 0 "kein_Objekt_enthalten" 31 "Init" ;
VAL_ 589 SWA_Obj_04_Gemessen 0 "ObjektpositionY_geschaetzt" 1 "ObjektpositionY_bestaetigt" ;
VAL_ 589 SWA_Obj_04_ID 0 "kein_Objekt_enthalten" 31 "Init" ;
VAL_ 589 SWA_Obj_05_Gemessen 0 "ObjektpositionY_geschaetzt" 1 "ObjektpositionY_bestaetigt" ;
VAL_ 589 SWA_Obj_05_ID 0 "kein_Objekt_enthalten" 31 "Init" ;
VAL_ 589 SWA_Obj_06_Gemessen 0 "ObjektpositionY_geschaetzt" 1 "ObjektpositionY_bestaetigt" ;
VAL_ 589 SWA_Obj_06_ID 0 "kein_Objekt_enthalten" 31 "Init" ;
VAL_ 589 SWA_Obj_01_GeschwRelX 511 "Init" ;
VAL_ 589 SWA_Obj_01_Breite 127 "Init" ;
VAL_ 589 SWA_Obj_01_GeschwRelY 511 "Init" ;
VAL_ 589 SWA_Obj_01_Existenzwahrsch 127 "Init" ;
VAL_ 589 SWA_Obj_01_Objektklasse 0 "unbekannt" 1 "dynamisch" 2 "VRU" 3 "Fussgaenger" 4 "Fussgaengergruppe" 5 "Radfahrer" 6 "Motorrad" 7 "PKW" 8 "mindestens_Vierrad" 9 "LKW" 10 "Zweirad" 11 "Tier" 12 "mindestens_Zweirad" 13 "Objektcluster" 15 "Init" ;
VAL_ 589 SWA_Obj_01_ReferenzPkt 0 "unbekannt" 1 "vorne_links" 2 "vorne_mitte" 3 "vorne_rechts" 4 "mitte_rechts" 5 "hinten_rechts" 6 "hinten_mitte" 7 "hinten_links" 8 "mitte_links" 9 "objekt_mitte" 15 "Init" ;
VAL_ 589 SWA_Obj_01_PositionX 511 "Init" ;
VAL_ 589 SWA_Obj_01_Laenge 127 "Init" ;
VAL_ 589 SWA_Obj_01_PositionY 255 "Init" ;
VAL_ 589 SWA_Obj_02_GeschwRelX 511 "Init" ;
VAL_ 589 SWA_Obj_02_Breite 127 "Init" ;
VAL_ 589 SWA_Obj_02_GeschwRelY 511 "Init" ;
VAL_ 589 SWA_Obj_02_Existenzwahrsch 127 "Init" ;
VAL_ 589 SWA_Obj_02_Objektklasse 0 "unbekannt" 1 "dynamisch" 2 "VRU" 3 "Fussgaenger" 4 "Fussgaengergruppe" 5 "Radfahrer" 6 "Motorrad" 7 "PKW" 8 "mindestens_Vierrad" 9 "LKW" 10 "Zweirad" 11 "Tier" 12 "mindestens_Zweirad" 13 "Objektcluster" 15 "Init" ;
VAL_ 589 SWA_Obj_02_ReferenzPkt 0 "unbekannt" 1 "vorne_links" 2 "vorne_mitte" 3 "vorne_rechts" 4 "mitte_rechts" 5 "hinten_rechts" 6 "hinten_mitte" 7 "hinten_links" 8 "mitte_links" 9 "objekt_mitte" 15 "Init" ;
VAL_ 589 SWA_Obj_02_PositionX 511 "Init" ;
VAL_ 589 SWA_Obj_02_Laenge 127 "Init" ;
VAL_ 589 SWA_Obj_02_PositionY 255 "Init" ;
VAL_ 589 SWA_Obj_03_GeschwRelX 511 "Init" ;
VAL_ 589 SWA_Obj_03_Breite 127 "Init" ;
VAL_ 589 SWA_Obj_03_GeschwRelY 511 "Init" ;
VAL_ 589 SWA_Obj_03_Existenzwahrsch 127 "Init" ;
VAL_ 589 SWA_Obj_03_Objektklasse 0 "unbekannt" 1 "dynamisch" 2 "VRU" 3 "Fussgaenger" 4 "Fussgaengergruppe" 5 "Radfahrer" 6 "Motorrad" 7 "PKW" 8 "mindestens_Vierrad" 9 "LKW" 10 "Zweirad" 11 "Tier" 12 "mindestens_Zweirad" 13 "Objektcluster" 15 "Init" ;
VAL_ 589 SWA_Obj_03_ReferenzPkt 0 "unbekannt" 1 "vorne_links" 2 "vorne_mitte" 3 "vorne_rechts" 4 "mitte_rechts" 5 "hinten_rechts" 6 "hinten_mitte" 7 "hinten_links" 8 "mitte_links" 9 "objekt_mitte" 15 "Init" ;
VAL_ 589 SWA_Obj_03_PositionX 511 "Init" ;
VAL_ 589 SWA_Obj_03_Laenge 127 "Init" ;
VAL_ 589 SWA_Obj_03_PositionY 255 "Init" ;
VAL_ 589 SWA_Obj_04_GeschwRelX 511 "Init" ;
VAL_ 589 SWA_Obj_04_Breite 127 "Init" ;
VAL_ 589 SWA_Obj_04_GeschwRelY 511 "Init" ;
VAL_ 589 SWA_Obj_04_Existenzwahrsch 127 "Init" ;
VAL_ 589 SWA_Obj_04_Objektklasse 0 "unbekannt" 1 "dynamisch" 2 "VRU" 3 "Fussgaenger" 4 "Fussgaengergruppe" 5 "Radfahrer" 6 "Motorrad" 7 "PKW" 8 "mindestens_Vierrad" 9 "LKW" 10 "Zweirad" 11 "Tier" 12 "mindestens_Zweirad" 13 "Objektcluster" 15 "Init" ;
VAL_ 589 SWA_Obj_04_ReferenzPkt 0 "unbekannt" 1 "vorne_links" 2 "vorne_mitte" 3 "vorne_rechts" 4 "mitte_rechts" 5 "hinten_rechts" 6 "hinten_mitte" 7 "hinten_links" 8 "mitte_links" 9 "objekt_mitte" 15 "Init" ;
VAL_ 589 SWA_Obj_04_PositionX 511 "Init" ;
VAL_ 589 SWA_Obj_04_Laenge 127 "Init" ;
VAL_ 589 SWA_Obj_04_PositionY 255 "Init" ;
VAL_ 589 SWA_Obj_05_GeschwRelX 511 "Init" ;
VAL_ 589 SWA_Obj_05_Breite 127 "Init" ;
VAL_ 589 SWA_Obj_05_GeschwRelY 511 "Init" ;
VAL_ 589 SWA_Obj_05_Existenzwahrsch 127 "Init" ;
VAL_ 589 SWA_Obj_05_Objektklasse 0 "unbekannt" 1 "dynamisch" 2 "VRU" 3 "Fussgaenger" 4 "Fussgaengergruppe" 5 "Radfahrer" 6 "Motorrad" 7 "PKW" 8 "mindestens_Vierrad" 9 "LKW" 10 "Zweirad" 11 "Tier" 12 "mindestens_Zweirad" 13 "Objektcluster" 15 "Init" ;
VAL_ 589 SWA_Obj_05_ReferenzPkt 0 "unbekannt" 1 "vorne_links" 2 "vorne_mitte" 3 "vorne_rechts" 4 "mitte_rechts" 5 "hinten_rechts" 6 "hinten_mitte" 7 "hinten_links" 8 "mitte_links" 9 "objekt_mitte" 15 "Init" ;
VAL_ 589 SWA_Obj_05_PositionX 511 "Init" ;
VAL_ 589 SWA_Obj_05_Laenge 127 "Init" ;
VAL_ 589 SWA_Obj_05_PositionY 255 "Init" ;
VAL_ 589 SWA_Obj_06_GeschwRelX 511 "Init" ;
VAL_ 589 SWA_Obj_06_Breite 127 "Init" ;
VAL_ 589 SWA_Obj_06_GeschwRelY 511 "Init" ;
VAL_ 589 SWA_Obj_06_Existenzwahrsch 127 "Init" ;
VAL_ 589 SWA_Obj_06_Objektklasse 0 "unbekannt" 1 "dynamisch" 2 "VRU" 3 "Fussgaenger" 4 "Fussgaengergruppe" 5 "Radfahrer" 6 "Motorrad" 7 "PKW" 8 "mindestens_Vierrad" 9 "LKW" 10 "Zweirad" 11 "Tier" 12 "mindestens_Zweirad" 13 "Objektcluster" 15 "Init" ;
VAL_ 589 SWA_Obj_06_ReferenzPkt 0 "unbekannt" 1 "vorne_links" 2 "vorne_mitte" 3 "vorne_rechts" 4 "mitte_rechts" 5 "hinten_rechts" 6 "hinten_mitte" 7 "hinten_links" 8 "mitte_links" 9 "objekt_mitte" 15 "Init" ;
VAL_ 589 SWA_Obj_06_PositionX 511 "Init" ;
VAL_ 589 SWA_Obj_06_Laenge 127 "Init" ;
VAL_ 589 SWA_Obj_06_PositionY 255 "Init" ;
VAL_ 2463978813 HVL_Steckerstatus 0 "Init" 1 "kein_Stecker_erkannt" 2 "Stecker_erkannt" 3 "Fehler" ;
VAL_ 2463978813 HVL_Status_EoHVL 0 "Init" 1 "Keine_offene_HV_Leitung_erkannt" 2 "offene_HV_Leitung_erkannt" 3 "Fehler" ;
VAL_ 2463978813 HVL_Kuehltemperatur 254 "Init" 255 "Fehler" ;
VAL_ 2463978813 HVL_LadeAnforderung 0 "Laden_nicht_angefordert" 1 "AC_Laden_Angefordert" 2 "DC_Laden_Angefordert" 3 "AC_und_DC_Angefordert" 4 "Induktiv_Laden_Angef" 5 "AC_und_Induktiv_Angef" 6 "DC_und_Induktiv_Angef" 7 "AC_DC_und_Induktiv_Angef" ;
VAL_ 2463978813 HVL_HVK_Fehler_DCAbschaltung 0 "keine_Anforderung_Init" 1 "Anforderung_DC_Notabschaltung" ;
VAL_ 2463978813 HVL_Status_Spgfreiheit 0 "Init__ohne_Funktion" 1 "HV_Komponente_Spannungsfrei" 2 "HV_Komponente_nichtSpannungsfrei" 3 "Fehler" ;
VAL_ 2463978813 HVL_OCC_IstModus 0 "Standby" 1 "Netzladung_aktiv" 2 "Rueckspeisung_aktiv" 3 "reserve" 4 "reserve" 5 "reserve" 6 "Init" 7 "Fehler" ;
VAL_ 2463978891 ICV_Switch_FieldOfView 0 "Init" 1 "Show_Driver" 2 "Show_CoDriver" 3 "Show_FullCabin" ;
VAL_ 2463978891 ICV_Switch_FunctionState 0 "Init" 1 "Cancel" 2 "Start" 3 "Freeze" ;
VAL_ 2463978891 ICV_Switch_Brightness 126 "init" ;
VAL_ 2463978891 PetsMode_Enable 0 "Function_disabled" 1 "Function_enabled" ;
VAL_ 2463978891 ICV_Switch_Resolution 0 "Init" 1 "Aufloesung_160x120" 2 "Aufloesung_320x240" 3 "Aufloesung_640x480" 4 "Aufloesung_1280x720" 5 "Aufloesung_1920x1080" ;
VAL_ 2463978891 ICV_Switch_FrameRate 31 "init" ;
VAL_ 2463978891 ICV_Switch_ColorMode 0 "init" 1 "RGB" 2 "IR" ;
VAL_ 2463978891 ICV_Switch_HDR 0 "init" 1 "on" 2 "off" ;
VAL_ 2463978891 ICV_Switch_Contrast 126 "init" ;
VAL_ 2463978891 Selfie_Switch_FunctionState 0 "init" 1 "VideoShot_Start" 2 "VideoShot_Stop" 3 "PhotoShot_Single" 4 "PhotoShot_Continuous" 5 "Cancel" ;
VAL_ 2463978891 Selfie_Switch_Resolution 0 "init" 1 "Res_5M_pixels" 2 "Res_2M_pixels" ;
VAL_ 2463978891 ICV_Switch_AspectRatio 0 "init" 1 "AspectRatio_4_3" 2 "AspectRatio_16_9" 3 "AspectRatio_3_4" 4 "AspectRatio_9_16" ;
VAL_ 2463978891 ICV_Switch_VideoLength 0 "init" 1 "Lenght_15s" 2 "Lenght_30s" 3 "Lenght_60s" 4 "customized" ;
VAL_ 2463978891 CabinCare_Enable 0 "Function_disabled" 1 "Function_enabled" ;
VAL_ 1524 IL_Bel_FS_Ausstieg 0 "inaktiv" 1 "aktiv" ;
VAL_ 1524 IL_Bel_BFS_Ausstieg 0 "inaktiv" 1 "aktiv" ;
VAL_ 1524 IL_Bel_HFS_Ausstieg 0 "inaktiv" 1 "aktiv" ;
VAL_ 1524 IL_Bel_HBFS_Ausstieg 0 "inaktiv" 1 "aktiv" ;
VAL_ 1524 BCM1_Innenlicht_gedimmt_V 0 "100% Innenlicht" 1 "gedimmtes Innenlicht" ;
VAL_ 1524 BCM1_Innenlicht_gedimmt_H 0 "100% Innenlicht" 1 "gedimmtes Innenlicht" ;
VAL_ 1524 IL_Innenlicht_aktiv 0 "Innenlicht inaktiv" 1 "Innenlicht aktiv" ;
VAL_ 1524 IL_Klemme_30G_aktiv 0 "Kl_30G_abgeschaltet" 1 "eingeschaltet" ;
VAL_ 1524 BCM1_DI_Rampe_Innenlicht 0 "Dimmrampe 0" 1 "Dimmrampe 1" ;
VAL_ 1524 BCM1_DI_Rampe_Leselicht 0 "Dimmrampe 0" 1 "Dimmrampe 1" ;
VAL_ 1524 BCM1_Innenlicht_H 0 "Aus" 1 "Ein" ;
VAL_ 1524 BCM1_Innenlicht_V 0 "Aus" 1 "Ein" ;
VAL_ 1524 BCM1_Leselicht_Anf_hl 0 "Aus" 1 "Ein" ;
VAL_ 1524 BCM1_Leselicht_Anf_hr 0 "Aus" 1 "Ein" ;
VAL_ 1524 BCM1_Leselicht_Anf_vl 0 "Aus" 1 "Ein" ;
VAL_ 1524 BCM1_Leselicht_Anf_vr 0 "Aus" 1 "Ein" ;
VAL_ 1524 BCM1_Leuchten_Aus 0 "keine Aenderung" 1 "Aus" ;
VAL_ 1524 AMB_Charisma_FahrPr 0 "keine_Funktion" 1 "Programm_1" 2 "Programm_2" 3 "Programm_3" 4 "Programm_4" 5 "Programm_5" 6 "Programm_6" 7 "Programm_7" 8 "Programm_8" 9 "Programm_9" 10 "Programm_10" 11 "Programm_11" 12 "Programm_12" 13 "Programm_13" 14 "Programm_14" 15 "Programm_15" ;
VAL_ 1524 AMB_Charisma_Status 0 "Init" 1 "verfuegbar" 2 "nicht_verfuegbar" 3 "asynchron_durch_Fahrerwunsch" ;
VAL_ 1524 IL_Tuerkontakt_Taster 0 "nicht_betaetigt" 1 "betaetigt" ;
VAL_ 2527679667 Kamera_AHC_L_Funktionsstatus 0 "AHC_aktiv" 1 "AHC_nicht_angefordert" 2 "Kamera_temp_nicht_verfuegbar" 3 "Kamera_nicht_kalib_oder_Fehler" 15 "Init" ;
VAL_ 2527679667 Kamera_AHC_L_Gierwinkel 8191 "Init" ;
VAL_ 2527679667 Kamera_AHC_L_Nickwinkel 8191 "Init" ;
VAL_ 2527679667 Kamera_AHC_L_ROI_ID 15 "Init" ;
VAL_ 2527679667 Kamera_AHC_L_Qualitaet 31 "Init" ;
VAL_ 2527679667 Kamera_AHC_R_Funktionsstatus 0 "AHC_aktiv" 1 "AHC_nicht_angefordert" 2 "Kamera_temp_nicht_verfuegbar" 3 "Kamera_nicht_kalib_oder_Fehler" 15 "Init" ;
VAL_ 2527679667 Kamera_AHC_R_Gierwinkel 8191 "Init" ;
VAL_ 2527679667 Kamera_AHC_R_Nickwinkel 8191 "Init" ;
VAL_ 2527679667 Kamera_AHC_R_ROI_ID 15 "Init" ;
VAL_ 2527679667 Kamera_AHC_R_Qualitaet 31 "Init" ;
VAL_ 2527679684 Kamera_ASM_Ereignis 0 "No_Event" 255 "ASM_Trigger" ;
VAL_ 2527679684 Kamera_ASM_Zeitstempel_02 255 "Init" ;
VAL_ 2589283730 Kamera_SDA_Geschw_Spur_R 63 "Init" ;
VAL_ 2589283730 Kamera_SDA_Geschw_Spur_L 63 "Init" ;
VAL_ 2589283730 Kamera_SDA_Geschw_Spur_E 63 "Init" ;
VAL_ 2589283730 Kamera_SDA_Abstand_Spur_E1 63 "nicht_verfügbar" ;
VAL_ 2589283730 Kamera_SDA_Abstand_Spur_E2 63 "nicht_verfügbar" ;
VAL_ 2589283730 Kamera_SDA_Abstand_Spur_L1 63 "nicht_verfügbar" ;
VAL_ 2589283730 Kamera_SDA_Abstand_Spur_L2 63 "nicht_verfügbar" ;
VAL_ 2589283730 Kamera_SDA_Abstand_Spur_R1 63 "nicht_verfügbar" ;
VAL_ 2589283730 Kamera_SDA_Abstand_Spur_R2 63 "nicht_verfügbar" ;
VAL_ 2589283730 Kamera_SDA_Eigenblendung 0 "nicht_erkannt" 1 "erkannt" ;
VAL_ 2589283730 Kamera_SDA_Sichtweite 0 "Init" 1 "keine_Sichtweitenbegrenzung" ;
VAL_ 2589283730 Kamera_SDA_Status_allg 0 "nicht_aktiv" 1 "aktiv" 2 "blockiert" 3 "Fehler" ;
VAL_ 2589283730 Kamera_SDA_Status_Beleuchtung 0 "nicht_aktiv" 1 "aktiv" ;
VAL_ 792 Kamera_Systemzustand 0 "Kamera_operativ" 1 "Kamera_Initialisierung" 2 "Kamera_schaltet_ab" 3 "Kamera_Fehler" ;
VAL_ 792 Kamera_FDD_Eigenblend_Guete 14 "Init" 15 "Fehler" ;
VAL_ 792 Kamera_FDD_Eigenblend 0 "Keine_Eigenblendung_erkannt" 1 "Eigenblendung_erkannt" ;
VAL_ 792 Kamera_FDD_Strassenbeleuchung 0 "keine_Strassenbeleuchtung" 1 "Strassenbeleuchtung" 2 "Strassenleuchte" 3 "nicht_verfuegbar" ;
VAL_ 792 Kamera_FDD_Funktionsstatus 0 "FDD_ein_aktiv" 1 "FDD_ein_passiv" 2 "FDD_ein_Einschraenkung_Sicht" 3 "FDD_ein_Fehler_HW_SW" 4 "FDD_aus" 6 "Init" ;
VAL_ 792 Kamera_FDD_Anz_Strassenleuchten 15 "Init" ;
VAL_ 792 Kamera_FDD_Verkehrsrichtung 0 "rechtsverkehr" 1 "linksverkehr" 2 "Init" 3 "nicht verfuegbar" ;
VAL_ 792 Kamera_Helligkeit 1022 "Init" 1023 "Fehler" ;
VAL_ 792 VZE_Status_EDR 0 "Commanded_Off" 1 "On_but_Not_ControllingOrWarning" 2 "Actively_Warning" 3 "Actively_Controlling" 4 "Driver_Override" 5 "Faulted" ;
VAL_ 792 Kamera_FSH_aktiv 0 "Kamera_Frontscheibenheizung_nicht_aktiviert" 1 "Kamera_Frontscheibenheizung_aktiviert" ;
VAL_ 960 RSt_Fahrerhinweise 0 "Init" 1 "Fahreruebernahme_Hinweis_ZAT_Automat_ohne_Gong" 2 "Fahreruebernahme_Hinweis_ZAT_Automat_mit_Gong" 3 "Fahreruebernahme_Hinweis_ZAT_Handschalter_ohne_Gong" 4 "Fahreruebernahme_Hinweis_ZAT_Handschalter_mit_Gong" 5 "Fahreruebernahme_Hinweis_ZAS_Automat_ohne_Gong" 6 "Fahreruebernahme_Hinweis_ZAS_Automat_mit_Gong" 7 "Fahreruebernahme_Hinweis_ZAS_Handschalter_ohne_Gong" 8 "Fahreruebernahme_Hinweis_ZAS_Handschalter_mit_Gong" 9 "RemoteStart_aktiv_ohne_Gong" 10 "RemoteStart_aktiv_mit_Gong" 11 "void" 12 "void" 13 "void" 14 "void" 15 "void" ;
VAL_ 960 ZAS_Kl_S 0 "aus" 1 "S_Kontakt_ein" ;
VAL_ 960 ZAS_Kl_15 0 "aus" 1 "ein" ;
VAL_ 960 ZAS_Kl_X 0 "aus" 1 "ein" ;
VAL_ 960 ZAS_Kl_50_Startanforderung 0 "aus" 1 "KL50_ein_Startwunsch_Fahrer" ;
VAL_ 960 ZAS_Kl_Infotainment 0 "inaktiv" 1 "aktiv" ;
VAL_ 960 KST_Warn_P1_ZST_def 0 "nicht_defekt" 1 "defekt" ;
VAL_ 960 KST_Warn_P2_ZST_def 0 "nicht_defekt" 1 "defekt" ;
VAL_ 960 KST_Fahrerhinweis_1 0 "inaktiv" 1 "aktiv" ;
VAL_ 960 KST_Fahrerhinweis_2 0 "inaktiv" 1 "aktiv" ;
VAL_ 960 BCM_Ausparken_Betrieb 0 "kein_Betrieb" 1 "Ausparkvorgang_aktiv" ;
VAL_ 960 KST_Fahrerhinweis_4 0 "inaktiv" 1 "aktiv" ;
VAL_ 960 KST_Fahrerhinweis_5 0 "inaktiv" 1 "aktiv" ;
VAL_ 960 KST_Fahrerhinweis_6 0 "inaktiv" 1 "aktiv" ;
VAL_ 2463978753 KST_WFS_Fahrfreigabe_Anforderung 0 "Keine" 1 "Uneingeschraenkt" 2 "Eingeschraenkt" ;
VAL_ 2463978753 KST_Sonderzustand_Status 0 "Init" 1 "Uebergang_neue_Anforderung" 2 "Aktiv" 3 "Fehler" ;
VAL_ 2463978753 KST_Sonderzustand_Anforderung 0 "Init" 1 "RemoteStart" 2 "RemoteParkAssist" 3 "IntelligentParkAssist" 4 "TrainiertesParken" 5 "OnlineRemoteUpdate" 6 "Einfrierschutz" 7 "Klemme15ViaDiagnose" 8 "RueckwandklappenSicherungPDC" 9 "ParkHausPilot" 10 "AnhaengerAnkuppelAssistent" 11 "MotorWeiterlaufSchaltung" 31 "Fehler" ;
VAL_ 2463978753 KST_ComfortReadyStatus 0 "aus" 1 "ComfortReadyStatus_ein" ;
VAL_ 1640 KL_LRH_Taster 0 "nicht_betaetigt" 1 "betaetigt" ;
VAL_ 1640 KL_LRH_Stufe 0 "Stufe_niedrig" 1 "Stufe_mittel" 2 "Stufe_hoch" 3 "AUS" ;
VAL_ 1640 HSH_Taster 0 "nicht_betaetigt" 1 "short_push" 2 "long_push" 3 "tbd" ;
VAL_ 1640 FSH_Taster 0 "nicht_betaetigt" 1 "betaetigt" ;
VAL_ 1640 KL_Zuheizer_Freigabe 0 "keine_Freigabe_Zuheizer" 1 "Zuheizerfreigabe" ;
VAL_ 1640 KL_Beschlagsgefahr 0 "keine_Beschlagsgefahr" 1 "Beschlagsgefahr" ;
VAL_ 1640 KRH_Soll_li 0 "aus" 1 "Stufe_1" 2 "Stufe_2" 3 "Stufe_3" ;
VAL_ 1640 KRH_Soll_re 0 "aus" 1 "Stufe_1" 2 "Stufe_2" 3 "Stufe_3" ;
VAL_ 1640 KL_Geblspng_Soll 0 "0V_Motorspannung" 252 "0V_sofort_Abschalten" 253 "0V_senken_mit_Rampe" 254 "reserviert" 255 "Fehler" ;
VAL_ 1640 KL_Geblspng_Fond_Soll 0 "0V_Motorspannung" 252 "0V_sofort_Abschalten" 253 "0V_senken_mit_Rampe" 254 "reserviert" 255 "Fehler" ;
VAL_ 1640 KL_I_Geblaese 255 "Fehler" ;
VAL_ 1640 KL_Kompressorstrom_soll 1022 "Init" 1023 "Fehler" ;
VAL_ 1640 KL_Umluftklappe_Status 0 "Frischluft" 1 "Teilumluft_10" 2 "Teilumluft_20" 3 "Teilumluft_30" 4 "Teilumluft_40" 5 "Teilumluft_50" 6 "Teilumluft_60" 7 "Teilumluft_70" 8 "Teilumluft_80" 9 "Teilumluft_90" 10 "Umluft" 14 "Init" 15 "Fehler" ;
VAL_ 1640 KL_PTC_Verbauinfo 0 "kein_PTC" 1 "600W_geschaltet" 2 "1000W_geschaltet" 3 "1400W_LIN" ;
VAL_ 1505 BCM1_Aussen_Temp_ungef 253 "nicht_verbaut" 254 "Initwert" 255 "Fehler" ;
VAL_ 1505 BCM_Heizungsabsperrventil_Status 0 "HAV_offen" 1 "HAV_geschlossen" 2 "Init_oder_nicht_verbaut" 3 "Fehler" ;
VAL_ 1505 BCM_Heizungspumpe_Status 0 "Pumpe_aus" 1 "Pumpe_aktiv_und_Stauts_iO" 2 "Init_oder_nicht_verbaut" 3 "Fehler" ;
VAL_ 1505 BCM_Kompressorkupplung_Status 0 "Kupplung_offen" 1 "Kupplung_geschlossen" 2 "Init_oder_nicht_verbaut" 3 "Fehler" ;
VAL_ 1505 BCM1_PTC_stufig_Status 0 "Aus" 1 "Stufe_1_aktiv" 2 "Stufe_2_aktiv" 3 "Stufe_3_aktiv" 6 "Init_oder_nicht_verbaut" 7 "Fehler" ;
VAL_ 1505 BCM1_FStatus_Aussentemp_ungef 0 "iO" 1 "niO" ;
VAL_ 1505 BCM1_Kompressorstrom_ist 254 "Init, bzw. nicht verfuegbar" 255 "Fehler" ;
VAL_ 1505 BCM1_OBD_FStatus_ATemp 0 "kein Fehler / Init / nicht verbaut" 1 "KS- (Kurzschluss nach minus)" 2 "KS+ (Kurzschluss nach plus)" 3 "OC (Leitungsunterbrechung)" 4 "OOR+ (Signal zu gross)" 5 "OOR- (Signal zu klein)" 6 "RC+ (Signal unplausibel zu gross)" 7 "RC- (Signal unplausibel zu klein)" 8 "KS+/OC (Kurzschluss nach plus/Unterbrechung)" 9 "KS-/OC  (Kurzschluss nach minus/Unterbrechung)" 10 "KS-/KS+  (Kurzschluss nach minus/plus)" 11 "KS-/KS+/OC (Kurzschluss nach minus/plus/Unterbrechung)" 12 "frei" 13 "frei" 14 "frei" 15 "frei" ;
VAL_ 605 KLR_Fehler 0 "kein_Fehler" 1 "Fehler" ;
VAL_ 605 KLR_ResponseError 0 "normal" 1 "Fehler" ;
VAL_ 605 KLR_Fehler_Codierung 0 "Kein_Fehler" 1 "Fehler" ;
VAL_ 605 KLR_Touchintensitaet_1 251 "Kalibrierung" 252 "nicht_verfuegbar" 253 "res" 254 "Init" 255 "Fehler" ;
VAL_ 605 KLR_Touchintensitaet_2 251 "Kalibrierung" 252 "nicht_verfuegbar" 253 "res" 254 "Init" 255 "Fehler" ;
VAL_ 605 KLR_Touchintensitaet_3 251 "Kalibrierung" 252 "nicht_verfuegbar" 253 "res" 254 "Init" 255 "Fehler" ;
VAL_ 605 KLR_Touchauswertung 0 "Keine_Beruehrung" 1 "Leicht_beruehrt_innen" 2 "Leicht_beruehrt_links" 3 "Leicht_beruehrt_rechts" 4 "Leicht_beruehrt_links_rechts" 5 "Leicht_umgriffen_links" 6 "Leicht_umgriffen_rechts" 7 "Leicht_umgriffen_links_rechts" 8 "Stark_umgriffen_links" 9 "Stark_umgriffen_rechts" 10 "Stark_umgriffen_links_rechts" 11 "res" 12 "res" 13 "Kalibrierung" 14 "Init" 15 "Fehler_Touchauswertung" ;
VAL_ 2549088343 ACC_KompSchutz 0 "KS_nicht_aktiv" 1 "KS_aktiv" ;
VAL_ 2549088343 ACC_Abschaltstufe 0 "keine_Einschraenkung" 1 "Funktionseinschraenkung" ;
VAL_ 2549088343 ACC_Transport_Mode 0 "keine_Einschraenkung" 1 "Funktionseinschraenkung" ;
VAL_ 2549088343 ACC_Nachlauftyp 0 "Komm_bei_KL15_EIN" 1 "Komm_nach_KL15_AUS" 2 "Komm_bei_KL15_AUS" ;
VAL_ 2549088343 KN_ACC_ECUKnockOutTimer 63 "ECUKnockOut_deaktiviert" ;
VAL_ 2549088343 KN_ACC_BusKnockOut 0 "Funktion_nicht_ausgeloest" 1 "Veto_aktiv" 2 "Funktion_ausgeloest" 3 "Funktion_deaktiviert" ;
VAL_ 2549088343 KN_ACC_BusKnockOutTimer 255 "BusKnockOut_deaktiviert" ;
VAL_ 2549088343 NM_ACC_Wakeup 0 "Peripherie_Wakeup__Ursache_nicht_bekannt" 1 "Bus_Wakeup" 2 "KL15_HW" ;
VAL_ 2549088343 KN_ACC_ECUKnockOut 0 "Funktion_nicht_ausgeloest" 1 "Veto_war_aktiv" 2 "Funktion_ausgeloest" 3 "Funktion_deaktiviert" ;
VAL_ 2549088343 KN_ACC_DiagPfad 0 "aktiv" 1 "inaktiv" ;
VAL_ 2549088343 ACC_KD_Fehler 0 "Kein_KD_Fehler" 1 "KD_Fehler" ;
VAL_ 2549088272 Gateway_KompSchutz 0 "inaktiv" 1 "aktiv" ;
VAL_ 2549088272 Gateway_Abschaltstufe 0 "keine_Einschraenkung" 1 "Funktionseinschraenkung" ;
VAL_ 2549088272 Gateway_Transport_Mode 0 "keine_Einschraenkung" 1 "Funktionseinschraenkung" ;
VAL_ 2549088272 Gateway_Nachlauftyp 0 "Komm_bei_KL15_EIN" 1 "Komm_nach_KL15_AUS" 2 "Komm_bei_KL15_AUS" ;
VAL_ 2549088272 NM_Gateway_Wakeup 0 "Peripherie_Wakeup__Ursache_nicht_bekannt" 1 "Bus_Wakeup" 2 "KL15_HW" 3 "ACAN_Wakeup" 4 "FCAN_Wakeup" 5 "KCAN_Wakeup" 6 "ICAN_Wakeup" 7 "DiagCAN_Wakeup" 8 "ECAN_Wakeup" 9 "Energie_LIN_Wakeup" 10 "Bedien_LIN_Wakeup" 11 "HybridCAN_Wakeup" 12 "Flexray_Wakeup" 13 "MFL_WakeUp" 14 "Ethernet" 15 "DCAN_Wakeup" 16 "K2CAN_Wakeup" 17 "CCAN" 18 "AFSCAN_Wakeup" 19 "LIN1" 20 "LIN2" 21 "LIN3" 22 "LIN4" 23 "LIN5" 24 "LIN6" 25 "FASCAN" 26 "FAS2CAN" 27 "MDKCAN" 32 "FlexRay_Branch1_WakeUp" 33 "FlexRay_Branch2_WakeUp" 34 "FlexRay_Branch3_WakeUp" 35 "FlexRay_Branch4_WakeUp" 36 "FlexRay_Branch5_WakeUp" 37 "FlexRay_Branch6_WakeUp" 38 "FlexRay_Branch7_WakeUp" 39 "FlexRay_Branch8_WakeUp" 40 "FlexRay_Branch9_WakeUp" 41 "FlexRay_Branch10_WakeUp" 42 "FlexRay_Branch11_WakeUp" 43 "FlexRay_Branch12_WakeUp" 44 "FlexRay_Branch13_WakeUp" 45 "FlexRay_Branch14_WakeUp" 46 "FlexRay_Branch15_WakeUp" 47 "FlexRay_Branch16_WakeUp" 128 "Energiemanagement" 129 "Funktionswakeup_OBDC" 130 "Hochvoltenergiemanagement" 131 "CWU_empfangen" 132 "Fuer_Bus_relevanten_FC_empfangen" 133 "OnlineDienst_empfangen" 134 "HV_Aktivieren" 135 "HV_Deaktivieren" 136 "VTS_Suche_DriverCard" 137 "VTS_Hupen_Blinken" 138 "Remote_Vehicle_Status" 139 "Plug_and_Charge" 140 "VTS_Wakeup_Infotainment" 141 "EMHLR" 142 "NFcGW_fordert_OTA_FC_an" 143 "Komponentenschutz" 144 "UserStateServer" 145 "Dimmung" 146 "Kessy" 147 "StandardAussenlicht" 148 "ParkKoordinator" 149 "HVLMDynamicChargingPOI" 150 "HVLMChargingManagementServer" 151 "HVLMExtendedChargingMonitoring" 152 "Zentralverriegelung" 153 "FunctionOnDemand" 154 "IAA" 155 "StandKlimatisierung" 156 "RealTimeMonitor" 157 "Klemmensteuerung" 158 "Fremdladung_erkannt" ;
VAL_ 2549088272 KN_GW_DiagPfad 0 "aktiv" 1 "inaktiv" ;
VAL_ 2549088272 GW_KD_Fehler 0 "kein_KD_Fehler" 1 "KD_Fehler" ;
VAL_ 2549088335 Kamera_KompSchutz 0 "inaktiv" 1 "aktiv" ;
VAL_ 2549088335 Kamera_Abschaltstufe 0 "keine_Einschraenkung" 1 "Funktionseinschraenkung" ;
VAL_ 2549088335 Kamera_Transport_Mode 0 "keine_Einschraenkung" 1 "Funktionseinschraenkung" ;
VAL_ 2549088335 Kamera_Nachlauftyp 0 "Komm_bei_KL15_EIN" 1 "Komm_nach_KL15_AUS" 2 "Komm_bei_KL15_AUS" ;
VAL_ 2549088335 KN_Kamera_ECUKnockOutTimer 63 "ECUKnockOut_deaktiviert" ;
VAL_ 2549088335 KN_Kamera_BusKnockOut 0 "Funktion_nicht_ausgeloest" 1 "Veto_aktiv" 2 "Funktion_ausgeloest" 3 "Funktion_deaktiviert" ;
VAL_ 2549088335 KN_Kamera_BusKnockOutTimer 255 "BusKnockOut_deaktiviert" ;
VAL_ 2549088335 NM_Kamera_Wakeup 0 "Peripherie_Wakeup_Ursache_nicht_bekannt" 1 "Bus_Wakeup" 2 "KL15_HW" ;
VAL_ 2549088335 KN_Kamera_ECUKnockOut 0 "Funktion_nicht_ausgeloest" 1 "Veto_war_aktiv" 2 "Funktion_ausgeloest" 3 "Funktion_deaktiviert" ;
VAL_ 2549088335 KN_Kamera_DiagPfad 0 "aktiv" 1 "inaktiv" ;
VAL_ 2549088335 Kamera_KD_Fehler 0 "Kein_KD_Fehler" 1 "KD_Fehler" ;
VAL_ 2549088313 MIK_KompSchutz 0 "inaktiv" 1 "aktiv" ;
VAL_ 2549088313 MIK_Abschaltstufe 0 "keine_Einschraenkung" 1 "Funktionseinschraenkung" ;
VAL_ 2549088313 MIK_Transport_Mode 0 "keine_Einschraenkung" 1 "Funktionseinschraenkung" ;
VAL_ 2549088313 MIK_Nachlauftyp 0 "Komm_bei_KL15_EIN" 1 "Komm_nach_KL15_AUS" 2 "Komm_bei_KL15_AUS" ;
VAL_ 2549088313 KN_MIK_ECUKnockOutTimer 63 "ECUKnockOut_deaktiviert" ;
VAL_ 2549088313 KN_MIK_BusKnockOut 0 "Funktion_nicht_ausgeloest" 1 "Veto_aktiv" 2 "Funktion_ausgeloest" 3 "Funktion_deaktiviert" ;
VAL_ 2549088313 KN_MIK_BusKnockOutTimer 255 "BusKnockOut_deaktiviert" ;
VAL_ 2549088313 NM_MIK_Wakeup 0 "Peripherie_Wakeup__Ursache_nicht_bekannt" 1 "Bus_Wakeup" 2 "KL15_HW" ;
VAL_ 2549088313 KN_MIK_ECUKnockOut 0 "Funktion_nicht_ausgeloest" 1 "Veto_war_aktiv" 2 "Funktion_ausgeloest" 3 "Funktion_deaktiviert" ;
VAL_ 2549088313 KN_MIK_DiagPfad 0 "aktiv" 1 "inaktiv" ;
VAL_ 2549088313 MIK_KD_Fehler 0 "Kein_KD_Fehler" 1 "KD_Fehler" ;
VAL_ 2549088443 NR_01_KompSchutz 0 "KS_nicht_aktiv" 1 "KS_aktiv" ;
VAL_ 2549088443 NR_01_Abschaltstufe 0 "keine_Einschraenkung" 1 "Funktionseinschraenkung" ;
VAL_ 2549088443 NR_01_Transport_Mode 0 "keine_Einschraenkung" 1 "Funktionseinschraenkung" ;
VAL_ 2549088443 NR_01_Nachlauftyp 0 "Komm_bei_KL15_EIN" 1 "Komm_nach_KL15_AUS" 2 "Komm_bei_KL15_AUS" ;
VAL_ 2549088443 KN_NR_01_ECUKnockOutTimer 63 "ECUKnockOut_deaktiviert" ;
VAL_ 2549088443 KN_NR_01_BusKnockOut 0 "Funktion_nicht_ausgeloest" 1 "Veto_aktiv" 2 "Funktion_ausgeloest" 3 "Funktion_deaktiviert" ;
VAL_ 2549088443 KN_NR_01_BusKnockOutTimer 255 "BusKnockOut_deaktiviert" ;
VAL_ 2549088443 NM_NR_01_Wakeup 0 "Peripherie_Wakeup__Ursache_nicht_bekannt" 1 "Bus_Wakeup" 2 "KL15_HW" ;
VAL_ 2549088443 KN_NR_01_ECUKnockOut 0 "Funktion_nicht_ausgeloest" 1 "Veto_war_aktiv" 2 "Funktion_ausgeloest" 3 "Funktion_deaktiviert" ;
VAL_ 2549088443 KN_NR_01_DiagPfad 0 "aktiv" 1 "inaktiv" ;
VAL_ 2549088443 NR_01_KD_Fehler 0 "Kein_KD_Fehler" 1 "KD_Fehler" ;
VAL_ 2549088444 NR_02_KompSchutz 0 "KS_nicht_aktiv" 1 "KS_aktiv" ;
VAL_ 2549088444 NR_02_Abschaltstufe 0 "keine_Einschraenkung" 1 "Funktionseinschraenkung" ;
VAL_ 2549088444 NR_02_Transport_Mode 0 "keine_Einschraenkung" 1 "Funktionseinschraenkung" ;
VAL_ 2549088444 NR_02_Nachlauftyp 0 "Komm_bei_KL15_EIN" 1 "Komm_nach_KL15_AUS" 2 "Komm_bei_KL15_AUS" ;
VAL_ 2549088444 KN_NR_02_ECUKnockOutTimer 63 "ECUKnockOut_deaktiviert" ;
VAL_ 2549088444 KN_NR_02_BusKnockOut 0 "Funktion_nicht_ausgeloest" 1 "Veto_aktiv" 2 "Funktion_ausgeloest" 3 "Funktion_deaktiviert" ;
VAL_ 2549088444 KN_NR_02_BusKnockOutTimer 255 "BusKnockOut_deaktiviert" ;
VAL_ 2549088444 NM_NR_02_Wakeup 0 "Peripherie_Wakeup_Ursache_nicht_bekannt" 1 "Bus_Wakeup" 2 "KL15_HW" ;
VAL_ 2549088444 KN_NR_02_ECUKnockOut 0 "Funktion_nicht_ausgeloest" 1 "Veto_war_aktiv" 2 "Funktion_ausgeloest" 3 "Funktion_deaktiviert" ;
VAL_ 2549088444 KN_NR_02_DiagPfad 0 "aktiv" 1 "inaktiv" ;
VAL_ 2549088444 NR_02_KD_Fehler 0 "Kein_KD_Fehler" 1 "KD_Fehler" ;
VAL_ 919 LDW_Gong 0 "kein akustisches Signal" 1 "Gong_1" 2 "Gong_2" 3 "Gong_3" ;
VAL_ 919 LDW_Frueh_Spaet 0 "frueh_frueh_aktiv" 1 "frueh_spaet_aktiv" 2 "spaet_spaet_aktiv" 3 "Fehler" ;
VAL_ 919 LDW_Texte 0 "keine_Anzeige" 1 "Laneassist_zur_Zeit_n_verfuegbar" 2 "Laneassist_Systemfehler" 3 "Laneassist_zur_Zeit_keine_SSicht" 4 "Laneassist_Fahreruebernahme" 5 "Laneassist_n_verfuegbar_FoD" 6 "Emergency_Alert_Fahreruebernahme" 7 "Laneassist_FahreruebernahmeLeise" 8 "Laneassist_FahreruebernahmeStumm" 9 "EA_Fahrstreifenwechsel" 10 "Laneassist_Deaktiviert" 11 "Laneassist_Fahreruebernahme_hoch" 12 "Laneassist_mittig_fahren" 13 "Laneassist_adaptiv_aktiv" 14 "Laneassist_adaptiv_deaktiv" 15 "Systgr_Fzgfueh_sofort_uebernehm" ;
VAL_ 919 LDW_Seite_DLCTLC 0 "links" 1 "rechts" ;
VAL_ 919 LDW_Status_Anzeige 0 "Init_keine_Anzeige" 1 "Lenkeingriff" 2 "Deaktiviert" 3 "Passiv" 4 "Aktiv" 5 "Passiv_automatisch" 6 "nicht_definiert" 7 "nicht_definiert" ;
VAL_ 919 LDW_Lernmodus_seitenabhaengig 0 "links_aus__rechts_aus" 1 "HCCA_links_an__rechts_an" 2 "HCCA_links_an__rechts_Warnung" 3 "HCCA_links_Warnung__rechts_an" 4 "links_gestrichelt_rechts_Warnung" 5 "links_outlined__rechts_outlined" 6 "links_outlined__rechts_an" 7 "links_outlined__rechts_Warnung" 8 "links_Warnung_rechts_gestrichel" 9 "links_an__rechts_outlined" 10 "links_an__rechts_an" 11 "links_an__rechts_Warnung" 12 "links_und_rechts_gestrichelt" 13 "links_Warnung__rechts_outlined" 14 "links_Warnung__rechts_an" 15 "links_Warnung__rechts_Warnung" ;
VAL_ 919 LDW_TLC 31 "Init" ;
VAL_ 919 HC_Uss_Anforderung 0 "Ultraschallsensoren Aus" 1 "Ultraschallsensoren An" ;
VAL_ 919 LDW_Status_Grid 0 "keine_Anzeige" 1 "reduzierte_Anzeige" 2 "komplette_Anzeige" ;
VAL_ 919 aLDW_FoD_Status 0 "Init" 1 "Funktion_inaktiv" 2 "Funktion_aktiv" ;
VAL_ 919 LDW_Status_LED_gelb 0 "LDW-Status gelb aus" 1 "LDW-Status gelb aktiv" ;
VAL_ 919 LDW_Status_LED_gruen 0 "LDW-Status gruen aus" 1 "LDW-Status gruen aktiv" ;
VAL_ 810 EPS_SpannungsAnf 0 "keine_Anforderung" 1 "Anforderung_Stufe1" 2 "Anforderung_Stufe2" 3 "Anforderung_Stufe3" ;
VAL_ 810 EPS_Endanschlag 0 "Init_bzw_Defaultlenkhub" 1 "Lenkhubaufweitung_1" 2 "EA_nicht_angelernt_bzw_Initialisierung_nicht_abgeschlossen" 3 "Fehler" ;
VAL_ 810 EPS_Akustiksignal 0 "Akustiksignal_nicht_aktiv" 1 "Akustiksignal_aktiv" ;
VAL_ 810 EPS_Fehlerlampe 0 "Lampe_aus" 1 "Lampe_ein" ;
VAL_ 810 EPS_Warnungen 0 "kein_Text" 1 "Text_1" 2 "Text_2" 3 "Text_3" 4 "Text_4" 5 "Text_5" ;
VAL_ 810 EPS_PLA_Status 0 "EPS_PLA_Deaktiv" 1 "EPS_PLA_Init" 2 "EPS_PLA_Fehler_mit_Eintrag" 3 "reserviert" 4 "reserviert" 5 "reserviert" 6 "EPS_PLA_Lenkwinkel_aktiv" 7 "EPS_PLA_Abgewiesen" 8 "EPS_PLA_Funktionsbereit" 9 "reserviert" 10 "EPS_PLA_Abbruch" 11 "reserviert" 12 "reserviert" 13 "reserviert" 14 "reserviert" 15 "reserviert" ;
VAL_ 810 EPS_Charisma_FahrPr 0 "keine_Funktion" 1 "Programm_1" 2 "Programm_2" 3 "Programm_3" 4 "Programm_4" 5 "Programm_5" 6 "Programm_6" 7 "Programm_7" 8 "Programm_8" 9 "Programm_9" 10 "Programm_10" 11 "Programm_11" 12 "Programm_12" 13 "Programm_13" 14 "Programm_14" 15 "Programm_15" ;
VAL_ 810 EPS_Charisma_Status 0 "Init" 1 "verfuegbar" 2 "nicht_verfuegbar" 3 "asynchron_durch_Fahrerwunsch" ;
VAL_ 810 EPS_VZ_Zst_Offset_Geradeaus 0 "pos_VZ" 1 "neg_VZ" ;
VAL_ 810 EPS_Lenkerposition 0 "unbekannt" 1 "Linkslenker" 2 "Rechtslenker" ;
VAL_ 810 EPS_Anf_KL 0 "keine_Anforderung" 1 "Anforderung_Kuehlung" ;
VAL_ 810 EPS_ARA_Status 0 "EPS_ARA_Deaktiv" 1 "EPS_ARA_Init" 2 "EPS_ARA_Fehler_mit_Eintrag" 3 "reserviert" 4 "reserviert" 5 "reserviert" 6 "EPS_ARA_Lenkwinkel_aktiv" 7 "EPS_ARA_Abgewiesen" 8 "EPS_ARA_Funktionsbereit" 9 "reserviert" 10 "EPS_ARA_Abbruch" 11 "reserviert" 12 "reserviert" 13 "reserviert" 14 "reserviert" 15 "reserviert" ;
VAL_ 810 EPS_Zst_Offset_Geradeaus 510 "Init" 511 "Fehler" ;
